VERSION ""

NS_ :

BS_:

BU_: BMS_Controller NF_Controller NF_Controllers

BO_ 2499762532 BATT_Diagnostic_Pack_A: 8 BMS_Controller
 SG_ BATT_01_vBrickOverSev m0 : 2|2@1+ (1,0) [0|3] ""  NF_Controller
 SG_ BATT_01_vBrickOverMod m0 : 0|2@1+ (1,0) [0|3] ""  NF_Controller
 SG_ BATT_01_vBrickOverWar m0 : 14|2@1+ (1,0) [0|3] ""  NF_Controller
 SG_ BATT_01_HostQuiet m0 : 12|2@1+ (1,0) [0|3] ""  NF_Controller
 SG_ BATT_01_vBrickUnderMod m0 : 10|2@1+ (1,0) [0|3] ""  NF_Controller
 SG_ BATT_01_vBrickUnderWar m0 : 8|2@1+ (1,0) [0|3] ""  NF_Controller
 SG_ BATT_01_TempModuleOverSev m0 : 22|2@1+ (1,0) [0|3] ""  NF_Controller
 SG_ BATT_01_TempModuleOverMod m0 : 20|2@1+ (1,0) [0|3] ""  NF_Controller
 SG_ BATT_01_TempModuleOverWar m0 : 18|2@1+ (1,0) [0|3] ""  NF_Controller
 SG_ BATT_01_TempModuleUnderSev m0 : 16|2@1+ (1,0) [0|3] ""  NF_Controller
 SG_ BATT_01_TempModuleUnderMod m0 : 30|2@1+ (1,0) [0|3] ""  NF_Controller
 SG_ BATT_01_TempModuleUnderWar m0 : 28|2@1+ (1,0) [0|3] ""  NF_Controller
 SG_ BATT_01_iOvercharge m0 : 26|2@1+ (1,0) [0|3] ""  NF_Controller
 SG_ BATT_01_iOverdischarge m0 : 24|2@1+ (1,0) [0|3] ""  NF_Controller
 SG_ BATT_01_iOverHardware m0 : 38|2@1+ (1,0) [0|3] ""  NF_Controller
 SG_ BATT_01_PosDcContStuckOpen m0 : 36|2@1+ (1,0) [0|3] ""  NF_Controller
 SG_ BATT_01_PosDcContWelded m0 : 34|2@1+ (1,0) [0|3] ""  NF_Controller
 SG_ BATT_01_NegDcContStuckOpen m0 : 32|2@1+ (1,0) [0|3] ""  NF_Controller
 SG_ BATT_01_NegDcContWelded m0 : 46|2@1+ (1,0) [0|3] ""  NF_Controller
 SG_ BATT_01_PrechgTooFast m0 : 44|2@1+ (1,0) [0|3] ""  NF_Controller
 SG_ BATT_01_PrechgContWelded m0 : 42|2@1+ (1,0) [0|3] ""  NF_Controller
 SG_ BATT_01_PrechgTimeout m0 : 40|2@1+ (1,0) [0|3] ""  NF_Controller
 SG_ BATT_01_PrechgContStuckOpen m0 : 54|2@1+ (1,0) [0|3] ""  NF_Controller
 SG_ BATT_01_ModuleImbalance m0 : 52|2@1+ (1,0) [0|3] ""  NF_Controller
 SG_ BATT_01_ModuleMIA m0 : 50|2@1+ (1,0) [0|3] ""  NF_Controller
 SG_ BATT_01_SensePackVoltError m0 : 48|2@1+ (1,0) [0|3] ""  NF_Controller
 SG_ BATT_01_SenseLoadVoltError m0 : 62|2@1+ (1,0) [0|3] ""  NF_Controller
 SG_ BATT_01_SenseShuntError m0 : 60|2@1+ (1,0) [0|3] ""  NF_Controller
 SG_ BATT_01_SenseFcVoltErrorr m0 : 58|2@1+ (1,0) [0|3] ""  NF_Controller
 SG_ BATT_01_SenseBrickOpen m0 : 56|2@1+ (1,0) [0|3] ""  NF_Controller
 SG_ BATT_02_vBrickOverSev m1 : 2|2@1+ (1,0) [0|3] ""  NF_Controller
 SG_ BATT_02_vBrickOverMod m1 : 0|2@1+ (1,0) [0|3] ""  NF_Controller
 SG_ BATT_02_vBrickOverWar m1 : 14|2@1+ (1,0) [0|3] ""  NF_Controller
 SG_ BATT_02_HostQuiet m1 : 12|2@1+ (1,0) [0|3] ""  NF_Controller
 SG_ BATT_02_vBrickUnderMod m1 : 10|2@1+ (1,0) [0|3] ""  NF_Controller
 SG_ BATT_02_vBrickUnderWar m1 : 8|2@1+ (1,0) [0|3] ""  NF_Controller
 SG_ BATT_02_TempModuleOverSev m1 : 22|2@1+ (1,0) [0|3] ""  NF_Controller
 SG_ BATT_02_TempModuleOverMod m1 : 20|2@1+ (1,0) [0|3] ""  NF_Controller
 SG_ BATT_02_TempModuleOverWar m1 : 18|2@1+ (1,0) [0|3] ""  NF_Controller
 SG_ BATT_02_TempModuleUnderSev m1 : 16|2@1+ (1,0) [0|3] ""  NF_Controller
 SG_ BATT_02_TempModuleUnderMod m1 : 30|2@1+ (1,0) [0|3] ""  NF_Controller
 SG_ BATT_02_TempModuleUnderWar m1 : 28|2@1+ (1,0) [0|3] ""  NF_Controller
 SG_ BATT_02_iOvercharge m1 : 26|2@1+ (1,0) [0|3] ""  NF_Controller
 SG_ BATT_02_iOverdischarge m1 : 24|2@1+ (1,0) [0|3] ""  NF_Controller
 SG_ BATT_02_iOverHardware m1 : 38|2@1+ (1,0) [0|3] ""  NF_Controller
 SG_ BATT_02_PosDcContStuckOpen m1 : 36|2@1+ (1,0) [0|3] ""  NF_Controller
 SG_ BATT_02_PosDcContWelded m1 : 34|2@1+ (1,0) [0|3] ""  NF_Controller
 SG_ BATT_02_NegDcContStuckOpen m1 : 32|2@1+ (1,0) [0|3] ""  NF_Controller
 SG_ BATT_02_NegDcContWelded m1 : 46|2@1+ (1,0) [0|3] ""  NF_Controller
 SG_ BATT_02_PrechgTooFast m1 : 44|2@1+ (1,0) [0|3] ""  NF_Controller
 SG_ BATT_02_PrechgContWelded m1 : 42|2@1+ (1,0) [0|3] ""  NF_Controller
 SG_ BATT_02_PrechgTimeout m1 : 40|2@1+ (1,0) [0|3] ""  NF_Controller
 SG_ BATT_02_PrechgContStuckOpen m1 : 54|2@1+ (1,0) [0|3] ""  NF_Controller
 SG_ BATT_02_ModuleImbalance m1 : 52|2@1+ (1,0) [0|3] ""  NF_Controller
 SG_ BATT_02_ModuleMIA m1 : 50|2@1+ (1,0) [0|3] ""  NF_Controller
 SG_ BATT_02_SensePackVoltError m1 : 48|2@1+ (1,0) [0|3] ""  NF_Controller
 SG_ BATT_02_SenseLoadVoltError m1 : 62|2@1+ (1,0) [0|3] ""  NF_Controller
 SG_ BATT_02_SenseShuntError m1 : 60|2@1+ (1,0) [0|3] ""  NF_Controller
 SG_ BATT_02_SenseFcVoltErrorr m1 : 58|2@1+ (1,0) [0|3] ""  NF_Controller
 SG_ BATT_02_SenseBrickOpen m1 : 56|2@1+ (1,0) [0|3] ""  NF_Controller
 SG_ BATT_03_vBrickOverSev m2 : 2|2@1+ (1,0) [0|3] ""  NF_Controller
 SG_ BATT_03_vBrickOverMod m2 : 0|2@1+ (1,0) [0|3] ""  NF_Controller
 SG_ BATT_03_vBrickOverWar m2 : 14|2@1+ (1,0) [0|3] ""  NF_Controller
 SG_ BATT_03_HostQuiet m2 : 12|2@1+ (1,0) [0|3] ""  NF_Controller
 SG_ BATT_03_vBrickUnderMod m2 : 10|2@1+ (1,0) [0|3] ""  NF_Controller
 SG_ BATT_03_vBrickUnderWar m2 : 8|2@1+ (1,0) [0|3] ""  NF_Controller
 SG_ BATT_03_TempModuleOverSev m2 : 22|2@1+ (1,0) [0|3] ""  NF_Controller
 SG_ BATT_03_TempModuleOverMod m2 : 20|2@1+ (1,0) [0|3] ""  NF_Controller
 SG_ BATT_03_TempModuleOverWar m2 : 18|2@1+ (1,0) [0|3] ""  NF_Controller
 SG_ BATT_03_TempModuleUnderSev m2 : 16|2@1+ (1,0) [0|3] ""  NF_Controller
 SG_ BATT_03_TempModuleUnderMod m2 : 30|2@1+ (1,0) [0|3] ""  NF_Controller
 SG_ BATT_03_TempModuleUnderWar m2 : 28|2@1+ (1,0) [0|3] ""  NF_Controller
 SG_ BATT_03_iOvercharge m2 : 26|2@1+ (1,0) [0|3] ""  NF_Controller
 SG_ BATT_03_iOverdischarge m2 : 24|2@1+ (1,0) [0|3] ""  NF_Controller
 SG_ BATT_03_iOverHardware m2 : 38|2@1+ (1,0) [0|3] ""  NF_Controller
 SG_ BATT_03_PosDcContStuckOpen m2 : 36|2@1+ (1,0) [0|3] ""  NF_Controller
 SG_ BATT_03_PosDcContWelded m2 : 34|2@1+ (1,0) [0|3] ""  NF_Controller
 SG_ BATT_03_NegDcContStuckOpen m2 : 32|2@1+ (1,0) [0|3] ""  NF_Controller
 SG_ BATT_03_NegDcContWelded m2 : 46|2@1+ (1,0) [0|3] ""  NF_Controller
 SG_ BATT_03_PrechgTooFast m2 : 44|2@1+ (1,0) [0|3] ""  NF_Controller
 SG_ BATT_03_PrechgContWelded m2 : 42|2@1+ (1,0) [0|3] ""  NF_Controller
 SG_ BATT_03_PrechgTimeout m2 : 40|2@1+ (1,0) [0|3] ""  NF_Controller
 SG_ BATT_03_PrechgContStuckOpen m2 : 54|2@1+ (1,0) [0|3] ""  NF_Controller
 SG_ BATT_03_ModuleImbalance m2 : 52|2@1+ (1,0) [0|3] ""  NF_Controller
 SG_ BATT_03_ModuleMIA m2 : 50|2@1+ (1,0) [0|3] ""  NF_Controller
 SG_ BATT_03_SensePackVoltError m2 : 48|2@1+ (1,0) [0|3] ""  NF_Controller
 SG_ BATT_03_SenseLoadVoltError m2 : 62|2@1+ (1,0) [0|3] ""  NF_Controller
 SG_ BATT_03_SenseShuntError m2 : 60|2@1+ (1,0) [0|3] ""  NF_Controller
 SG_ BATT_03_SenseFcVoltErrorr m2 : 58|2@1+ (1,0) [0|3] ""  NF_Controller
 SG_ BATT_03_SenseBrickOpen m2 : 56|2@1+ (1,0) [0|3] ""  NF_Controller
 SG_ BATT_04_vBrickOverSev m3 : 2|2@1+ (1,0) [0|3] ""  NF_Controller
 SG_ BATT_04_vBrickOverMod m3 : 0|2@1+ (1,0) [0|3] ""  NF_Controller
 SG_ BATT_04_vBrickOverWar m3 : 14|2@1+ (1,0) [0|3] ""  NF_Controller
 SG_ BATT_04_HostQuiet m3 : 12|2@1+ (1,0) [0|3] ""  NF_Controller
 SG_ BATT_04_vBrickUnderMod m3 : 10|2@1+ (1,0) [0|3] ""  NF_Controller
 SG_ BATT_04_vBrickUnderWar m3 : 8|2@1+ (1,0) [0|3] ""  NF_Controller
 SG_ BATT_04_TempModuleOverSev m3 : 22|2@1+ (1,0) [0|3] ""  NF_Controller
 SG_ BATT_04_TempModuleOverMod m3 : 20|2@1+ (1,0) [0|3] ""  NF_Controller
 SG_ BATT_04_TempModuleOverWar m3 : 18|2@1+ (1,0) [0|3] ""  NF_Controller
 SG_ BATT_04_TempModuleUnderSev m3 : 16|2@1+ (1,0) [0|3] ""  NF_Controller
 SG_ BATT_04_TempModuleUnderMod m3 : 30|2@1+ (1,0) [0|3] ""  NF_Controller
 SG_ BATT_04_TempModuleUnderWar m3 : 28|2@1+ (1,0) [0|3] ""  NF_Controller
 SG_ BATT_04_iOvercharge m3 : 26|2@1+ (1,0) [0|3] ""  NF_Controller
 SG_ BATT_04_iOverdischarge m3 : 24|2@1+ (1,0) [0|3] ""  NF_Controller
 SG_ BATT_04_iOverHardware m3 : 38|2@1+ (1,0) [0|3] ""  NF_Controller
 SG_ BATT_04_PosDcContStuckOpen m3 : 36|2@1+ (1,0) [0|3] ""  NF_Controller
 SG_ BATT_04_PosDcContWelded m3 : 34|2@1+ (1,0) [0|3] ""  NF_Controller
 SG_ BATT_04_NegDcContStuckOpen m3 : 32|2@1+ (1,0) [0|3] ""  NF_Controller
 SG_ BATT_04_NegDcContWelded m3 : 46|2@1+ (1,0) [0|3] ""  NF_Controller
 SG_ BATT_04_PrechgTooFast m3 : 44|2@1+ (1,0) [0|3] ""  NF_Controller
 SG_ BATT_04_PrechgContWelded m3 : 42|2@1+ (1,0) [0|3] ""  NF_Controller
 SG_ BATT_04_PrechgTimeout m3 : 40|2@1+ (1,0) [0|3] ""  NF_Controller
 SG_ BATT_04_PrechgContStuckOpen m3 : 54|2@1+ (1,0) [0|3] ""  NF_Controller
 SG_ BATT_04_ModuleImbalance m3 : 52|2@1+ (1,0) [0|3] ""  NF_Controller
 SG_ BATT_04_ModuleMIA m3 : 50|2@1+ (1,0) [0|3] ""  NF_Controller
 SG_ BATT_04_SensePackVoltError m3 : 48|2@1+ (1,0) [0|3] ""  NF_Controller
 SG_ BATT_04_SenseLoadVoltError m3 : 62|2@1+ (1,0) [0|3] ""  NF_Controller
 SG_ BATT_04_SenseShuntError m3 : 60|2@1+ (1,0) [0|3] ""  NF_Controller
 SG_ BATT_04_SenseFcVoltErrorr m3 : 58|2@1+ (1,0) [0|3] ""  NF_Controller
 SG_ BATT_04_SenseBrickOpen m3 : 56|2@1+ (1,0) [0|3] ""  NF_Controller
 SG_ BATT_05_vBrickOverSev m4 : 2|2@1+ (1,0) [0|3] ""  NF_Controller
 SG_ BATT_05_vBrickOverMod m4 : 0|2@1+ (1,0) [0|3] ""  NF_Controller
 SG_ BATT_05_vBrickOverWar m4 : 14|2@1+ (1,0) [0|3] ""  NF_Controller
 SG_ BATT_05_HostQuiet m4 : 12|2@1+ (1,0) [0|3] ""  NF_Controller
 SG_ BATT_05_vBrickUnderMod m4 : 10|2@1+ (1,0) [0|3] ""  NF_Controller
 SG_ BATT_05_vBrickUnderWar m4 : 8|2@1+ (1,0) [0|3] ""  NF_Controller
 SG_ BATT_05_TempModuleOverSev m4 : 22|2@1+ (1,0) [0|3] ""  NF_Controller
 SG_ BATT_05_TempModuleOverMod m4 : 20|2@1+ (1,0) [0|3] ""  NF_Controller
 SG_ BATT_05_TempModuleOverWar m4 : 18|2@1+ (1,0) [0|3] ""  NF_Controller
 SG_ BATT_05_TempModuleUnderSev m4 : 16|2@1+ (1,0) [0|3] ""  NF_Controller
 SG_ BATT_05_TempModuleUnderMod m4 : 30|2@1+ (1,0) [0|3] ""  NF_Controller
 SG_ BATT_05_TempModuleUnderWar m4 : 28|2@1+ (1,0) [0|3] ""  NF_Controller
 SG_ BATT_05_iOvercharge m4 : 26|2@1+ (1,0) [0|3] ""  NF_Controller
 SG_ BATT_05_iOverdischarge m4 : 24|2@1+ (1,0) [0|3] ""  NF_Controller
 SG_ BATT_05_iOverHardware m4 : 38|2@1+ (1,0) [0|3] ""  NF_Controller
 SG_ BATT_05_PosDcContStuckOpen m4 : 36|2@1+ (1,0) [0|3] ""  NF_Controller
 SG_ BATT_05_PosDcContWelded m4 : 34|2@1+ (1,0) [0|3] ""  NF_Controller
 SG_ BATT_05_NegDcContStuckOpen m4 : 32|2@1+ (1,0) [0|3] ""  NF_Controller
 SG_ BATT_05_NegDcContWelded m4 : 46|2@1+ (1,0) [0|3] ""  NF_Controller
 SG_ BATT_05_PrechgTooFast m4 : 44|2@1+ (1,0) [0|3] ""  NF_Controller
 SG_ BATT_05_PrechgContWelded m4 : 42|2@1+ (1,0) [0|3] ""  NF_Controller
 SG_ BATT_05_PrechgTimeout m4 : 40|2@1+ (1,0) [0|3] ""  NF_Controller
 SG_ BATT_05_PrechgContStuckOpen m4 : 54|2@1+ (1,0) [0|3] ""  NF_Controller
 SG_ BATT_05_ModuleImbalance m4 : 52|2@1+ (1,0) [0|3] ""  NF_Controller
 SG_ BATT_05_ModuleMIA m4 : 50|2@1+ (1,0) [0|3] ""  NF_Controller
 SG_ BATT_05_SensePackVoltError m4 : 48|2@1+ (1,0) [0|3] ""  NF_Controller
 SG_ BATT_05_SenseLoadVoltError m4 : 62|2@1+ (1,0) [0|3] ""  NF_Controller
 SG_ BATT_05_SenseShuntError m4 : 60|2@1+ (1,0) [0|3] ""  NF_Controller
 SG_ BATT_05_SenseFcVoltErrorr m4 : 58|2@1+ (1,0) [0|3] ""  NF_Controller
 SG_ BATT_05_SenseBrickOpen m4 : 56|2@1+ (1,0) [0|3] ""  NF_Controller
 SG_ BATT_06_vBrickOverSev m5 : 2|2@1+ (1,0) [0|3] ""  NF_Controller
 SG_ BATT_06_vBrickOverMod m5 : 0|2@1+ (1,0) [0|3] ""  NF_Controller
 SG_ BATT_06_vBrickOverWar m5 : 14|2@1+ (1,0) [0|3] ""  NF_Controller
 SG_ BATT_06_HostQuiet m5 : 12|2@1+ (1,0) [0|3] ""  NF_Controller
 SG_ BATT_06_vBrickUnderMod m5 : 10|2@1+ (1,0) [0|3] ""  NF_Controller
 SG_ BATT_06_vBrickUnderWar m5 : 8|2@1+ (1,0) [0|3] ""  NF_Controller
 SG_ BATT_06_TempModuleOverSev m5 : 22|2@1+ (1,0) [0|3] ""  NF_Controller
 SG_ BATT_06_TempModuleOverMod m5 : 20|2@1+ (1,0) [0|3] ""  NF_Controller
 SG_ BATT_06_TempModuleOverWar m5 : 18|2@1+ (1,0) [0|3] ""  NF_Controller
 SG_ BATT_06_TempModuleUnderSev m5 : 16|2@1+ (1,0) [0|3] ""  NF_Controller
 SG_ BATT_06_TempModuleUnderMod m5 : 30|2@1+ (1,0) [0|3] ""  NF_Controller
 SG_ BATT_06_TempModuleUnderWar m5 : 28|2@1+ (1,0) [0|3] ""  NF_Controller
 SG_ BATT_06_iOvercharge m5 : 26|2@1+ (1,0) [0|3] ""  NF_Controller
 SG_ BATT_06_iOverdischarge m5 : 24|2@1+ (1,0) [0|3] ""  NF_Controller
 SG_ BATT_06_iOverHardware m5 : 38|2@1+ (1,0) [0|3] ""  NF_Controller
 SG_ BATT_06_PosDcContStuckOpen m5 : 36|2@1+ (1,0) [0|3] ""  NF_Controller
 SG_ BATT_06_PosDcContWelded m5 : 34|2@1+ (1,0) [0|3] ""  NF_Controller
 SG_ BATT_06_NegDcContStuckOpen m5 : 32|2@1+ (1,0) [0|3] ""  NF_Controller
 SG_ BATT_06_NegDcContWelded m5 : 46|2@1+ (1,0) [0|3] ""  NF_Controller
 SG_ BATT_06_PrechgTooFast m5 : 44|2@1+ (1,0) [0|3] ""  NF_Controller
 SG_ BATT_06_PrechgContWelded m5 : 42|2@1+ (1,0) [0|3] ""  NF_Controller
 SG_ BATT_06_PrechgTimeout m5 : 40|2@1+ (1,0) [0|3] ""  NF_Controller
 SG_ BATT_06_PrechgContStuckOpen m5 : 54|2@1+ (1,0) [0|3] ""  NF_Controller
 SG_ BATT_06_ModuleImbalance m5 : 52|2@1+ (1,0) [0|3] ""  NF_Controller
 SG_ BATT_06_ModuleMIA m5 : 50|2@1+ (1,0) [0|3] ""  NF_Controller
 SG_ BATT_06_SensePackVoltError m5 : 48|2@1+ (1,0) [0|3] ""  NF_Controller
 SG_ BATT_06_SenseLoadVoltError m5 : 62|2@1+ (1,0) [0|3] ""  NF_Controller
 SG_ BATT_06_SenseShuntError m5 : 60|2@1+ (1,0) [0|3] ""  NF_Controller
 SG_ BATT_06_SenseFcVoltErrorr m5 : 58|2@1+ (1,0) [0|3] ""  NF_Controller
 SG_ BATT_06_SenseBrickOpen m5 : 56|2@1+ (1,0) [0|3] ""  NF_Controller
 SG_ BATT_07_vBrickOverSev m6 : 2|2@1+ (1,0) [0|3] ""  NF_Controller
 SG_ BATT_07_vBrickOverMod m6 : 0|2@1+ (1,0) [0|3] ""  NF_Controller
 SG_ BATT_07_vBrickOverWar m6 : 14|2@1+ (1,0) [0|3] ""  NF_Controller
 SG_ BATT_07_HostQuiet m6 : 12|2@1+ (1,0) [0|3] ""  NF_Controller
 SG_ BATT_07_vBrickUnderMod m6 : 10|2@1+ (1,0) [0|3] ""  NF_Controller
 SG_ BATT_07_vBrickUnderWar m6 : 8|2@1+ (1,0) [0|3] ""  NF_Controller
 SG_ BATT_07_TempModuleOverSev m6 : 22|2@1+ (1,0) [0|3] ""  NF_Controller
 SG_ BATT_07_TempModuleOverMod m6 : 20|2@1+ (1,0) [0|3] ""  NF_Controller
 SG_ BATT_07_TempModuleOverWar m6 : 18|2@1+ (1,0) [0|3] ""  NF_Controller
 SG_ BATT_07_TempModuleUnderSev m6 : 16|2@1+ (1,0) [0|3] ""  NF_Controller
 SG_ BATT_07_TempModuleUnderMod m6 : 30|2@1+ (1,0) [0|3] ""  NF_Controller
 SG_ BATT_07_TempModuleUnderWar m6 : 28|2@1+ (1,0) [0|3] ""  NF_Controller
 SG_ BATT_07_iOvercharge m6 : 26|2@1+ (1,0) [0|3] ""  NF_Controller
 SG_ BATT_07_iOverdischarge m6 : 24|2@1+ (1,0) [0|3] ""  NF_Controller
 SG_ BATT_07_iOverHardware m6 : 38|2@1+ (1,0) [0|3] ""  NF_Controller
 SG_ BATT_07_PosDcContStuckOpen m6 : 36|2@1+ (1,0) [0|3] ""  NF_Controller
 SG_ BATT_07_PosDcContWelded m6 : 34|2@1+ (1,0) [0|3] ""  NF_Controller
 SG_ BATT_07_NegDcContStuckOpen m6 : 32|2@1+ (1,0) [0|3] ""  NF_Controller
 SG_ BATT_07_NegDcContWelded m6 : 46|2@1+ (1,0) [0|3] ""  NF_Controller
 SG_ BATT_07_PrechgTooFast m6 : 44|2@1+ (1,0) [0|3] ""  NF_Controller
 SG_ BATT_07_PrechgContWelded m6 : 42|2@1+ (1,0) [0|3] ""  NF_Controller
 SG_ BATT_07_PrechgTimeout m6 : 40|2@1+ (1,0) [0|3] ""  NF_Controller
 SG_ BATT_07_PrechgContStuckOpen m6 : 54|2@1+ (1,0) [0|3] ""  NF_Controller
 SG_ BATT_07_ModuleImbalance m6 : 52|2@1+ (1,0) [0|3] ""  NF_Controller
 SG_ BATT_07_ModuleMIA m6 : 50|2@1+ (1,0) [0|3] ""  NF_Controller
 SG_ BATT_07_SensePackVoltError m6 : 48|2@1+ (1,0) [0|3] ""  NF_Controller
 SG_ BATT_07_SenseLoadVoltError m6 : 62|2@1+ (1,0) [0|3] ""  NF_Controller
 SG_ BATT_07_SenseShuntError m6 : 60|2@1+ (1,0) [0|3] ""  NF_Controller
 SG_ BATT_07_SenseFcVoltErrorr m6 : 58|2@1+ (1,0) [0|3] ""  NF_Controller
 SG_ BATT_07_SenseBrickOpen m6 : 56|2@1+ (1,0) [0|3] ""  NF_Controller
 SG_ BATT_08_vBrickOverSev m7 : 2|2@1+ (1,0) [0|3] ""  NF_Controller
 SG_ BATT_08_vBrickOverMod m7 : 0|2@1+ (1,0) [0|3] ""  NF_Controller
 SG_ BATT_08_vBrickOverWar m7 : 14|2@1+ (1,0) [0|3] ""  NF_Controller
 SG_ BATT_08_HostQuiet m7 : 12|2@1+ (1,0) [0|3] ""  NF_Controller
 SG_ BATT_08_vBrickUnderMod m7 : 10|2@1+ (1,0) [0|3] ""  NF_Controller
 SG_ BATT_08_vBrickUnderWar m7 : 8|2@1+ (1,0) [0|3] ""  NF_Controller
 SG_ BATT_08_TempModuleOverSev m7 : 22|2@1+ (1,0) [0|3] ""  NF_Controller
 SG_ BATT_08_TempModuleOverMod m7 : 20|2@1+ (1,0) [0|3] ""  NF_Controller
 SG_ BATT_08_TempModuleOverWar m7 : 18|2@1+ (1,0) [0|3] ""  NF_Controller
 SG_ BATT_08_TempModuleUnderSev m7 : 16|2@1+ (1,0) [0|3] ""  NF_Controller
 SG_ BATT_08_TempModuleUnderMod m7 : 30|2@1+ (1,0) [0|3] ""  NF_Controller
 SG_ BATT_08_TempModuleUnderWar m7 : 28|2@1+ (1,0) [0|3] ""  NF_Controller
 SG_ BATT_08_iOvercharge m7 : 26|2@1+ (1,0) [0|3] ""  NF_Controller
 SG_ BATT_08_iOverdischarge m7 : 24|2@1+ (1,0) [0|3] ""  NF_Controller
 SG_ BATT_08_iOverHardware m7 : 38|2@1+ (1,0) [0|3] ""  NF_Controller
 SG_ BATT_08_PosDcContStuckOpen m7 : 36|2@1+ (1,0) [0|3] ""  NF_Controller
 SG_ BATT_08_PosDcContWelded m7 : 34|2@1+ (1,0) [0|3] ""  NF_Controller
 SG_ BATT_08_NegDcContStuckOpen m7 : 32|2@1+ (1,0) [0|3] ""  NF_Controller
 SG_ BATT_08_NegDcContWelded m7 : 46|2@1+ (1,0) [0|3] ""  NF_Controller
 SG_ BATT_08_PrechgTooFast m7 : 44|2@1+ (1,0) [0|3] ""  NF_Controller
 SG_ BATT_08_PrechgContWelded m7 : 42|2@1+ (1,0) [0|3] ""  NF_Controller
 SG_ BATT_08_PrechgTimeout m7 : 40|2@1+ (1,0) [0|3] ""  NF_Controller
 SG_ BATT_08_PrechgContStuckOpen m7 : 54|2@1+ (1,0) [0|3] ""  NF_Controller
 SG_ BATT_08_ModuleImbalance m7 : 52|2@1+ (1,0) [0|3] ""  NF_Controller
 SG_ BATT_08_ModuleMIA m7 : 50|2@1+ (1,0) [0|3] ""  NF_Controller
 SG_ BATT_08_SensePackVoltError m7 : 48|2@1+ (1,0) [0|3] ""  NF_Controller
 SG_ BATT_08_SenseLoadVoltError m7 : 62|2@1+ (1,0) [0|3] ""  NF_Controller
 SG_ BATT_08_SenseShuntError m7 : 60|2@1+ (1,0) [0|3] ""  NF_Controller
 SG_ BATT_08_SenseFcVoltErrorr m7 : 58|2@1+ (1,0) [0|3] ""  NF_Controller
 SG_ BATT_08_SenseBrickOpen m7 : 56|2@1+ (1,0) [0|3] ""  NF_Controller
 SG_ BATT_09_vBrickOverSev m8 : 2|2@1+ (1,0) [0|3] ""  NF_Controller
 SG_ BATT_09_vBrickOverMod m8 : 0|2@1+ (1,0) [0|3] ""  NF_Controller
 SG_ BATT_09_vBrickOverWar m8 : 14|2@1+ (1,0) [0|3] ""  NF_Controller
 SG_ BATT_09_HostQuiet m8 : 12|2@1+ (1,0) [0|3] ""  NF_Controller
 SG_ BATT_09_vBrickUnderMod m8 : 10|2@1+ (1,0) [0|3] ""  NF_Controller
 SG_ BATT_09_vBrickUnderWar m8 : 8|2@1+ (1,0) [0|3] ""  NF_Controller
 SG_ BATT_09_TempModuleOverSev m8 : 22|2@1+ (1,0) [0|3] ""  NF_Controller
 SG_ BATT_09_TempModuleOverMod m8 : 20|2@1+ (1,0) [0|3] ""  NF_Controller
 SG_ BATT_09_TempModuleOverWar m8 : 18|2@1+ (1,0) [0|3] ""  NF_Controller
 SG_ BATT_09_TempModuleUnderSev m8 : 16|2@1+ (1,0) [0|3] ""  NF_Controller
 SG_ BATT_09_TempModuleUnderMod m8 : 30|2@1+ (1,0) [0|3] ""  NF_Controller
 SG_ BATT_09_TempModuleUnderWar m8 : 28|2@1+ (1,0) [0|3] ""  NF_Controller
 SG_ BATT_09_iOvercharge m8 : 26|2@1+ (1,0) [0|3] ""  NF_Controller
 SG_ BATT_09_iOverdischarge m8 : 24|2@1+ (1,0) [0|3] ""  NF_Controller
 SG_ BATT_09_iOverHardware m8 : 38|2@1+ (1,0) [0|3] ""  NF_Controller
 SG_ BATT_09_PosDcContStuckOpen m8 : 36|2@1+ (1,0) [0|3] ""  NF_Controller
 SG_ BATT_09_PosDcContWelded m8 : 34|2@1+ (1,0) [0|3] ""  NF_Controller
 SG_ BATT_09_NegDcContStuckOpen m8 : 32|2@1+ (1,0) [0|3] ""  NF_Controller
 SG_ BATT_09_NegDcContWelded m8 : 46|2@1+ (1,0) [0|3] ""  NF_Controller
 SG_ BATT_09_PrechgTooFast m8 : 44|2@1+ (1,0) [0|3] ""  NF_Controller
 SG_ BATT_09_PrechgContWelded m8 : 42|2@1+ (1,0) [0|3] ""  NF_Controller
 SG_ BATT_09_PrechgTimeout m8 : 40|2@1+ (1,0) [0|3] ""  NF_Controller
 SG_ BATT_09_PrechgContStuckOpen m8 : 54|2@1+ (1,0) [0|3] ""  NF_Controller
 SG_ BATT_09_ModuleImbalance m8 : 52|2@1+ (1,0) [0|3] ""  NF_Controller
 SG_ BATT_09_ModuleMIA m8 : 50|2@1+ (1,0) [0|3] ""  NF_Controller
 SG_ BATT_09_SensePackVoltError m8 : 48|2@1+ (1,0) [0|3] ""  NF_Controller
 SG_ BATT_09_SenseLoadVoltError m8 : 62|2@1+ (1,0) [0|3] ""  NF_Controller
 SG_ BATT_09_SenseShuntError m8 : 60|2@1+ (1,0) [0|3] ""  NF_Controller
 SG_ BATT_09_SenseFcVoltErrorr m8 : 58|2@1+ (1,0) [0|3] ""  NF_Controller
 SG_ BATT_09_SenseBrickOpen m8 : 56|2@1+ (1,0) [0|3] ""  NF_Controller
 SG_ BATT_10_vBrickOverSev m9 : 2|2@1+ (1,0) [0|3] ""  NF_Controller
 SG_ BATT_10_vBrickOverMod m9 : 0|2@1+ (1,0) [0|3] ""  NF_Controller
 SG_ BATT_10_vBrickOverWar m9 : 14|2@1+ (1,0) [0|3] ""  NF_Controller
 SG_ BATT_10_HostQuiet m9 : 12|2@1+ (1,0) [0|3] ""  NF_Controller
 SG_ BATT_10_vBrickUnderMod m9 : 10|2@1+ (1,0) [0|3] ""  NF_Controller
 SG_ BATT_10_vBrickUnderWar m9 : 8|2@1+ (1,0) [0|3] ""  NF_Controller
 SG_ BATT_10_TempModuleOverSev m9 : 22|2@1+ (1,0) [0|3] ""  NF_Controller
 SG_ BATT_10_TempModuleOverMod m9 : 20|2@1+ (1,0) [0|3] ""  NF_Controller
 SG_ BATT_10_TempModuleOverWar m9 : 18|2@1+ (1,0) [0|3] ""  NF_Controller
 SG_ BATT_10_TempModuleUnderSev m9 : 16|2@1+ (1,0) [0|3] ""  NF_Controller
 SG_ BATT_10_TempModuleUnderMod m9 : 30|2@1+ (1,0) [0|3] ""  NF_Controller
 SG_ BATT_10_TempModuleUnderWar m9 : 28|2@1+ (1,0) [0|3] ""  NF_Controller
 SG_ BATT_10_iOvercharge m9 : 26|2@1+ (1,0) [0|3] ""  NF_Controller
 SG_ BATT_10_iOverdischarge m9 : 24|2@1+ (1,0) [0|3] ""  NF_Controller
 SG_ BATT_10_iOverHardware m9 : 38|2@1+ (1,0) [0|3] ""  NF_Controller
 SG_ BATT_10_PosDcContStuckOpen m9 : 36|2@1+ (1,0) [0|3] ""  NF_Controller
 SG_ BATT_10_PosDcContWelded m9 : 34|2@1+ (1,0) [0|3] ""  NF_Controller
 SG_ BATT_10_NegDcContStuckOpen m9 : 32|2@1+ (1,0) [0|3] ""  NF_Controller
 SG_ BATT_10_NegDcContWelded m9 : 46|2@1+ (1,0) [0|3] ""  NF_Controller
 SG_ BATT_10_PrechgTooFast m9 : 44|2@1+ (1,0) [0|3] ""  NF_Controller
 SG_ BATT_10_PrechgContWelded m9 : 42|2@1+ (1,0) [0|3] ""  NF_Controller
 SG_ BATT_10_PrechgTimeout m9 : 40|2@1+ (1,0) [0|3] ""  NF_Controller
 SG_ BATT_10_PrechgContStuckOpen m9 : 54|2@1+ (1,0) [0|3] ""  NF_Controller
 SG_ BATT_10_ModuleImbalance m9 : 52|2@1+ (1,0) [0|3] ""  NF_Controller
 SG_ BATT_10_ModuleMIA m9 : 50|2@1+ (1,0) [0|3] ""  NF_Controller
 SG_ BATT_10_SensePackVoltError m9 : 48|2@1+ (1,0) [0|3] ""  NF_Controller
 SG_ BATT_10_SenseLoadVoltError m9 : 62|2@1+ (1,0) [0|3] ""  NF_Controller
 SG_ BATT_10_SenseShuntError m9 : 60|2@1+ (1,0) [0|3] ""  NF_Controller
 SG_ BATT_10_SenseFcVoltErrorr m9 : 58|2@1+ (1,0) [0|3] ""  NF_Controller
 SG_ BATT_10_SenseBrickOpen m9 : 56|2@1+ (1,0) [0|3] ""  NF_Controller
 SG_ BATT_11_vBrickOverSev m10 : 2|2@1+ (1,0) [0|3] ""  NF_Controller
 SG_ BATT_11_vBrickOverMod m10 : 0|2@1+ (1,0) [0|3] ""  NF_Controller
 SG_ BATT_11_vBrickOverWar m10 : 14|2@1+ (1,0) [0|3] ""  NF_Controller
 SG_ BATT_11_HostQuiet m10 : 12|2@1+ (1,0) [0|3] ""  NF_Controller
 SG_ BATT_11_vBrickUnderMod m10 : 10|2@1+ (1,0) [0|3] ""  NF_Controller
 SG_ BATT_11_vBrickUnderWar m10 : 8|2@1+ (1,0) [0|3] ""  NF_Controller
 SG_ BATT_11_TempModuleOverSev m10 : 22|2@1+ (1,0) [0|3] ""  NF_Controller
 SG_ BATT_11_TempModuleOverMod m10 : 20|2@1+ (1,0) [0|3] ""  NF_Controller
 SG_ BATT_11_TempModuleOverWar m10 : 18|2@1+ (1,0) [0|3] ""  NF_Controller
 SG_ BATT_11_TempModuleUnderSev m10 : 16|2@1+ (1,0) [0|3] ""  NF_Controller
 SG_ BATT_11_TempModuleUnderMod m10 : 30|2@1+ (1,0) [0|3] ""  NF_Controller
 SG_ BATT_11_TempModuleUnderWar m10 : 28|2@1+ (1,0) [0|3] ""  NF_Controller
 SG_ BATT_11_iOvercharge m10 : 26|2@1+ (1,0) [0|3] ""  NF_Controller
 SG_ BATT_11_iOverdischarge m10 : 24|2@1+ (1,0) [0|3] ""  NF_Controller
 SG_ BATT_11_iOverHardware m10 : 38|2@1+ (1,0) [0|3] ""  NF_Controller
 SG_ BATT_11_PosDcContStuckOpen m10 : 36|2@1+ (1,0) [0|3] ""  NF_Controller
 SG_ BATT_11_PosDcContWelded m10 : 34|2@1+ (1,0) [0|3] ""  NF_Controller
 SG_ BATT_11_NegDcContStuckOpen m10 : 32|2@1+ (1,0) [0|3] ""  NF_Controller
 SG_ BATT_11_NegDcContWelded m10 : 46|2@1+ (1,0) [0|3] ""  NF_Controller
 SG_ BATT_11_PrechgTooFast m10 : 44|2@1+ (1,0) [0|3] ""  NF_Controller
 SG_ BATT_11_PrechgContWelded m10 : 42|2@1+ (1,0) [0|3] ""  NF_Controller
 SG_ BATT_11_PrechgTimeout m10 : 40|2@1+ (1,0) [0|3] ""  NF_Controller
 SG_ BATT_11_PrechgContStuckOpen m10 : 54|2@1+ (1,0) [0|3] ""  NF_Controller
 SG_ BATT_11_ModuleImbalance m10 : 52|2@1+ (1,0) [0|3] ""  NF_Controller
 SG_ BATT_11_ModuleMIA m10 : 50|2@1+ (1,0) [0|3] ""  NF_Controller
 SG_ BATT_11_SensePackVoltError m10 : 48|2@1+ (1,0) [0|3] ""  NF_Controller
 SG_ BATT_11_SenseLoadVoltError m10 : 62|2@1+ (1,0) [0|3] ""  NF_Controller
 SG_ BATT_11_SenseShuntError m10 : 60|2@1+ (1,0) [0|3] ""  NF_Controller
 SG_ BATT_11_SenseFcVoltErrorr m10 : 58|2@1+ (1,0) [0|3] ""  NF_Controller
 SG_ BATT_11_SenseBrickOpen m10 : 56|2@1+ (1,0) [0|3] ""  NF_Controller
 SG_ BATT_12_vBrickOverSev m11 : 2|2@1+ (1,0) [0|3] ""  NF_Controller
 SG_ BATT_12_vBrickOverMod m11 : 0|2@1+ (1,0) [0|3] ""  NF_Controller
 SG_ BATT_12_vBrickOverWar m11 : 14|2@1+ (1,0) [0|3] ""  NF_Controller
 SG_ BATT_12_HostQuiet m11 : 12|2@1+ (1,0) [0|3] ""  NF_Controller
 SG_ BATT_12_vBrickUnderMod m11 : 10|2@1+ (1,0) [0|3] ""  NF_Controller
 SG_ BATT_12_vBrickUnderWar m11 : 8|2@1+ (1,0) [0|3] ""  NF_Controller
 SG_ BATT_12_TempModuleOverSev m11 : 22|2@1+ (1,0) [0|3] ""  NF_Controller
 SG_ BATT_12_TempModuleOverMod m11 : 20|2@1+ (1,0) [0|3] ""  NF_Controller
 SG_ BATT_12_TempModuleOverWar m11 : 18|2@1+ (1,0) [0|3] ""  NF_Controller
 SG_ BATT_12_TempModuleUnderSev m11 : 16|2@1+ (1,0) [0|3] ""  NF_Controller
 SG_ BATT_12_TempModuleUnderMod m11 : 30|2@1+ (1,0) [0|3] ""  NF_Controller
 SG_ BATT_12_TempModuleUnderWar m11 : 28|2@1+ (1,0) [0|3] ""  NF_Controller
 SG_ BATT_12_iOvercharge m11 : 26|2@1+ (1,0) [0|3] ""  NF_Controller
 SG_ BATT_12_iOverdischarge m11 : 24|2@1+ (1,0) [0|3] ""  NF_Controller
 SG_ BATT_12_iOverHardware m11 : 38|2@1+ (1,0) [0|3] ""  NF_Controller
 SG_ BATT_12_PosDcContStuckOpen m11 : 36|2@1+ (1,0) [0|3] ""  NF_Controller
 SG_ BATT_12_PosDcContWelded m11 : 34|2@1+ (1,0) [0|3] ""  NF_Controller
 SG_ BATT_12_NegDcContStuckOpen m11 : 32|2@1+ (1,0) [0|3] ""  NF_Controller
 SG_ BATT_12_NegDcContWelded m11 : 46|2@1+ (1,0) [0|3] ""  NF_Controller
 SG_ BATT_12_PrechgTooFast m11 : 44|2@1+ (1,0) [0|3] ""  NF_Controller
 SG_ BATT_12_PrechgContWelded m11 : 42|2@1+ (1,0) [0|3] ""  NF_Controller
 SG_ BATT_12_PrechgTimeout m11 : 40|2@1+ (1,0) [0|3] ""  NF_Controller
 SG_ BATT_12_PrechgContStuckOpen m11 : 54|2@1+ (1,0) [0|3] ""  NF_Controller
 SG_ BATT_12_ModuleImbalance m11 : 52|2@1+ (1,0) [0|3] ""  NF_Controller
 SG_ BATT_12_ModuleMIA m11 : 50|2@1+ (1,0) [0|3] ""  NF_Controller
 SG_ BATT_12_SensePackVoltError m11 : 48|2@1+ (1,0) [0|3] ""  NF_Controller
 SG_ BATT_12_SenseLoadVoltError m11 : 62|2@1+ (1,0) [0|3] ""  NF_Controller
 SG_ BATT_12_SenseShuntError m11 : 60|2@1+ (1,0) [0|3] ""  NF_Controller
 SG_ BATT_12_SenseFcVoltErrorr m11 : 58|2@1+ (1,0) [0|3] ""  NF_Controller
 SG_ BATT_12_SenseBrickOpen m11 : 56|2@1+ (1,0) [0|3] ""  NF_Controller
 SG_ BATT_13_vBrickOverSev m12 : 2|2@1+ (1,0) [0|3] ""  NF_Controller
 SG_ BATT_13_vBrickOverMod m12 : 0|2@1+ (1,0) [0|3] ""  NF_Controller
 SG_ BATT_13_vBrickOverWar m12 : 14|2@1+ (1,0) [0|3] ""  NF_Controller
 SG_ BATT_13_HostQuiet m12 : 12|2@1+ (1,0) [0|3] ""  NF_Controller
 SG_ BATT_13_vBrickUnderMod m12 : 10|2@1+ (1,0) [0|3] ""  NF_Controller
 SG_ BATT_13_vBrickUnderWar m12 : 8|2@1+ (1,0) [0|3] ""  NF_Controller
 SG_ BATT_13_TempModuleOverSev m12 : 22|2@1+ (1,0) [0|3] ""  NF_Controller
 SG_ BATT_13_TempModuleOverMod m12 : 20|2@1+ (1,0) [0|3] ""  NF_Controller
 SG_ BATT_13_TempModuleOverWar m12 : 18|2@1+ (1,0) [0|3] ""  NF_Controller
 SG_ BATT_13_TempModuleUnderSev m12 : 16|2@1+ (1,0) [0|3] ""  NF_Controller
 SG_ BATT_13_TempModuleUnderMod m12 : 30|2@1+ (1,0) [0|3] ""  NF_Controller
 SG_ BATT_13_TempModuleUnderWar m12 : 28|2@1+ (1,0) [0|3] ""  NF_Controller
 SG_ BATT_13_iOvercharge m12 : 26|2@1+ (1,0) [0|3] ""  NF_Controller
 SG_ BATT_13_iOverdischarge m12 : 24|2@1+ (1,0) [0|3] ""  NF_Controller
 SG_ BATT_13_iOverHardware m12 : 38|2@1+ (1,0) [0|3] ""  NF_Controller
 SG_ BATT_13_PosDcContStuckOpen m12 : 36|2@1+ (1,0) [0|3] ""  NF_Controller
 SG_ BATT_13_PosDcContWelded m12 : 34|2@1+ (1,0) [0|3] ""  NF_Controller
 SG_ BATT_13_NegDcContStuckOpen m12 : 32|2@1+ (1,0) [0|3] ""  NF_Controller
 SG_ BATT_13_NegDcContWelded m12 : 46|2@1+ (1,0) [0|3] ""  NF_Controller
 SG_ BATT_13_PrechgTooFast m12 : 44|2@1+ (1,0) [0|3] ""  NF_Controller
 SG_ BATT_13_PrechgContWelded m12 : 42|2@1+ (1,0) [0|3] ""  NF_Controller
 SG_ BATT_13_PrechgTimeout m12 : 40|2@1+ (1,0) [0|3] ""  NF_Controller
 SG_ BATT_13_PrechgContStuckOpen m12 : 54|2@1+ (1,0) [0|3] ""  NF_Controller
 SG_ BATT_13_ModuleImbalance m12 : 52|2@1+ (1,0) [0|3] ""  NF_Controller
 SG_ BATT_13_ModuleMIA m12 : 50|2@1+ (1,0) [0|3] ""  NF_Controller
 SG_ BATT_13_SensePackVoltError m12 : 48|2@1+ (1,0) [0|3] ""  NF_Controller
 SG_ BATT_13_SenseLoadVoltError m12 : 62|2@1+ (1,0) [0|3] ""  NF_Controller
 SG_ BATT_13_SenseShuntError m12 : 60|2@1+ (1,0) [0|3] ""  NF_Controller
 SG_ BATT_13_SenseFcVoltErrorr m12 : 58|2@1+ (1,0) [0|3] ""  NF_Controller
 SG_ BATT_13_SenseBrickOpen m12 : 56|2@1+ (1,0) [0|3] ""  NF_Controller
 SG_ BATT_14_vBrickOverSev m13 : 2|2@1+ (1,0) [0|3] ""  NF_Controller
 SG_ BATT_14_vBrickOverMod m13 : 0|2@1+ (1,0) [0|3] ""  NF_Controller
 SG_ BATT_14_vBrickOverWar m13 : 14|2@1+ (1,0) [0|3] ""  NF_Controller
 SG_ BATT_14_HostQuiet m13 : 12|2@1+ (1,0) [0|3] ""  NF_Controller
 SG_ BATT_14_vBrickUnderMod m13 : 10|2@1+ (1,0) [0|3] ""  NF_Controller
 SG_ BATT_14_vBrickUnderWar m13 : 8|2@1+ (1,0) [0|3] ""  NF_Controller
 SG_ BATT_14_TempModuleOverSev m13 : 22|2@1+ (1,0) [0|3] ""  NF_Controller
 SG_ BATT_14_TempModuleOverMod m13 : 20|2@1+ (1,0) [0|3] ""  NF_Controller
 SG_ BATT_14_TempModuleOverWar m13 : 18|2@1+ (1,0) [0|3] ""  NF_Controller
 SG_ BATT_14_TempModuleUnderSev m13 : 16|2@1+ (1,0) [0|3] ""  NF_Controller
 SG_ BATT_14_TempModuleUnderMod m13 : 30|2@1+ (1,0) [0|3] ""  NF_Controller
 SG_ BATT_14_TempModuleUnderWar m13 : 28|2@1+ (1,0) [0|3] ""  NF_Controller
 SG_ BATT_14_iOvercharge m13 : 26|2@1+ (1,0) [0|3] ""  NF_Controller
 SG_ BATT_14_iOverdischarge m13 : 24|2@1+ (1,0) [0|3] ""  NF_Controller
 SG_ BATT_14_iOverHardware m13 : 38|2@1+ (1,0) [0|3] ""  NF_Controller
 SG_ BATT_14_PosDcContStuckOpen m13 : 36|2@1+ (1,0) [0|3] ""  NF_Controller
 SG_ BATT_14_PosDcContWelded m13 : 34|2@1+ (1,0) [0|3] ""  NF_Controller
 SG_ BATT_14_NegDcContStuckOpen m13 : 32|2@1+ (1,0) [0|3] ""  NF_Controller
 SG_ BATT_14_NegDcContWelded m13 : 46|2@1+ (1,0) [0|3] ""  NF_Controller
 SG_ BATT_14_PrechgTooFast m13 : 44|2@1+ (1,0) [0|3] ""  NF_Controller
 SG_ BATT_14_PrechgContWelded m13 : 42|2@1+ (1,0) [0|3] ""  NF_Controller
 SG_ BATT_14_PrechgTimeout m13 : 40|2@1+ (1,0) [0|3] ""  NF_Controller
 SG_ BATT_14_PrechgContStuckOpen m13 : 54|2@1+ (1,0) [0|3] ""  NF_Controller
 SG_ BATT_14_ModuleImbalance m13 : 52|2@1+ (1,0) [0|3] ""  NF_Controller
 SG_ BATT_14_ModuleMIA m13 : 50|2@1+ (1,0) [0|3] ""  NF_Controller
 SG_ BATT_14_SensePackVoltError m13 : 48|2@1+ (1,0) [0|3] ""  NF_Controller
 SG_ BATT_14_SenseLoadVoltError m13 : 62|2@1+ (1,0) [0|3] ""  NF_Controller
 SG_ BATT_14_SenseShuntError m13 : 60|2@1+ (1,0) [0|3] ""  NF_Controller
 SG_ BATT_14_SenseFcVoltErrorr m13 : 58|2@1+ (1,0) [0|3] ""  NF_Controller
 SG_ BATT_14_SenseBrickOpen m13 : 56|2@1+ (1,0) [0|3] ""  NF_Controller
 SG_ BATT_15_vBrickOverSev m14 : 2|2@1+ (1,0) [0|3] ""  NF_Controller
 SG_ BATT_15_vBrickOverMod m14 : 0|2@1+ (1,0) [0|3] ""  NF_Controller
 SG_ BATT_15_vBrickOverWar m14 : 14|2@1+ (1,0) [0|3] ""  NF_Controller
 SG_ BATT_15_HostQuiet m14 : 12|2@1+ (1,0) [0|3] ""  NF_Controller
 SG_ BATT_15_vBrickUnderMod m14 : 10|2@1+ (1,0) [0|3] ""  NF_Controller
 SG_ BATT_15_vBrickUnderWar m14 : 8|2@1+ (1,0) [0|3] ""  NF_Controller
 SG_ BATT_15_TempModuleOverSev m14 : 22|2@1+ (1,0) [0|3] ""  NF_Controller
 SG_ BATT_15_TempModuleOverMod m14 : 20|2@1+ (1,0) [0|3] ""  NF_Controller
 SG_ BATT_15_TempModuleOverWar m14 : 18|2@1+ (1,0) [0|3] ""  NF_Controller
 SG_ BATT_15_TempModuleUnderSev m14 : 16|2@1+ (1,0) [0|3] ""  NF_Controller
 SG_ BATT_15_TempModuleUnderMod m14 : 30|2@1+ (1,0) [0|3] ""  NF_Controller
 SG_ BATT_15_TempModuleUnderWar m14 : 28|2@1+ (1,0) [0|3] ""  NF_Controller
 SG_ BATT_15_iOvercharge m14 : 26|2@1+ (1,0) [0|3] ""  NF_Controller
 SG_ BATT_15_iOverdischarge m14 : 24|2@1+ (1,0) [0|3] ""  NF_Controller
 SG_ BATT_15_iOverHardware m14 : 38|2@1+ (1,0) [0|3] ""  NF_Controller
 SG_ BATT_15_PosDcContStuckOpen m14 : 36|2@1+ (1,0) [0|3] ""  NF_Controller
 SG_ BATT_15_PosDcContWelded m14 : 34|2@1+ (1,0) [0|3] ""  NF_Controller
 SG_ BATT_15_NegDcContStuckOpen m14 : 32|2@1+ (1,0) [0|3] ""  NF_Controller
 SG_ BATT_15_NegDcContWelded m14 : 46|2@1+ (1,0) [0|3] ""  NF_Controller
 SG_ BATT_15_PrechgTooFast m14 : 44|2@1+ (1,0) [0|3] ""  NF_Controller
 SG_ BATT_15_PrechgContWelded m14 : 42|2@1+ (1,0) [0|3] ""  NF_Controller
 SG_ BATT_15_PrechgTimeout m14 : 40|2@1+ (1,0) [0|3] ""  NF_Controller
 SG_ BATT_15_PrechgContStuckOpen m14 : 54|2@1+ (1,0) [0|3] ""  NF_Controller
 SG_ BATT_15_ModuleImbalance m14 : 52|2@1+ (1,0) [0|3] ""  NF_Controller
 SG_ BATT_15_ModuleMIA m14 : 50|2@1+ (1,0) [0|3] ""  NF_Controller
 SG_ BATT_15_SensePackVoltError m14 : 48|2@1+ (1,0) [0|3] ""  NF_Controller
 SG_ BATT_15_SenseLoadVoltError m14 : 62|2@1+ (1,0) [0|3] ""  NF_Controller
 SG_ BATT_15_SenseShuntError m14 : 60|2@1+ (1,0) [0|3] ""  NF_Controller
 SG_ BATT_15_SenseFcVoltErrorr m14 : 58|2@1+ (1,0) [0|3] ""  NF_Controller
 SG_ BATT_15_SenseBrickOpen m14 : 56|2@1+ (1,0) [0|3] ""  NF_Controller
 SG_ multiplexor_batt_diag_A M : 4|4@1+ (1,0) [0|15] ""  NF_Controller

BO_ 2499758948 BATT_Diagnostic_System_A: 8 BMS_Controller
 SG_ BATT_vBrickOverSev : 2|2@1+ (1,0) [0|3] ""  NF_Controller
 SG_ BATT_vBrickOverMod : 0|2@1+ (1,0) [0|3] ""  NF_Controller
 SG_ BATT_vBrickOverWar : 14|2@1+ (1,0) [0|3] ""  NF_Controller
 SG_ BATT_HostQuiet : 12|2@1+ (1,0) [0|3] ""  NF_Controller
 SG_ BATT_vBrickUnderMod : 10|2@1+ (1,0) [0|3] ""  NF_Controller
 SG_ BATT_vBrickUnderWar : 8|2@1+ (1,0) [0|3] ""  NF_Controller
 SG_ BATT_TempModuleOverSev : 22|2@1+ (1,0) [0|3] ""  NF_Controller
 SG_ BATT_TempModuleOverMod : 20|2@1+ (1,0) [0|3] ""  NF_Controller
 SG_ BATT_TempModuleOverWar : 18|2@1+ (1,0) [0|3] ""  NF_Controller
 SG_ BATT_TempModuleUnderSev : 16|2@1+ (1,0) [0|3] ""  NF_Controller
 SG_ BATT_TempModuleUnderMod : 30|2@1+ (1,0) [0|3] ""  NF_Controller
 SG_ BATT_TempModuleUnderWar : 28|2@1+ (1,0) [0|3] ""  NF_Controller
 SG_ BATT_iOvercharge : 26|2@1+ (1,0) [0|3] ""  NF_Controller
 SG_ BATT_iOverdischarge : 24|2@1+ (1,0) [0|3] ""  NF_Controller
 SG_ BATT_iOverHardware : 38|2@1+ (1,0) [0|3] ""  NF_Controller
 SG_ BATT_PosDcContStuckOpen : 36|2@1+ (1,0) [0|3] ""  NF_Controller
 SG_ BATT_PosDcContWelded : 34|2@1+ (1,0) [0|3] ""  NF_Controller
 SG_ BATT_NegDcContStuckOpen : 32|2@1+ (1,0) [0|3] ""  NF_Controller
 SG_ BATT_NegDcContWelded : 46|2@1+ (1,0) [0|3] ""  NF_Controller
 SG_ BATT_PrechgTooFast : 44|2@1+ (1,0) [0|3] ""  NF_Controller
 SG_ BATT_PrechgContWelded : 42|2@1+ (1,0) [0|3] ""  NF_Controller
 SG_ BATT_PrechgTimeout : 40|2@1+ (1,0) [0|3] ""  NF_Controller
 SG_ BATT_PrechgContStuckOpen : 54|2@1+ (1,0) [0|3] ""  NF_Controller
 SG_ BATT_ModuleImbalance : 52|2@1+ (1,0) [0|3] ""  NF_Controller
 SG_ BATT_ModuleMIA : 50|2@1+ (1,0) [0|3] ""  NF_Controller
 SG_ BATT_SensePackVoltError : 48|2@1+ (1,0) [0|3] ""  NF_Controller
 SG_ BATT_SenseLoadVoltError : 62|2@1+ (1,0) [0|3] ""  NF_Controller
 SG_ BATT_SenseShuntError : 60|2@1+ (1,0) [0|3] ""  NF_Controller
 SG_ BATT_SenseFcVoltErrorr : 58|2@1+ (1,0) [0|3] ""  NF_Controller
 SG_ BATT_SenseBrickOpen : 56|2@1+ (1,0) [0|3] ""  NF_Controller

BO_ 2499759204 BATT_Diagnostic_System_B: 8 BMS_Controller
 SG_ BATT_SenseBrickImpHigh : 2|2@1+ (1,0) [0|3] ""  NF_Controller
 SG_ BATT_AFEfault : 0|2@1+ (1,0) [0|3] ""  NF_Controller
 SG_ BATT_AFEerror : 14|2@1+ (1,0) [0|3] ""  NF_Controller
 SG_ BATT_HostMIA : 12|2@1+ (1,0) [0|3] ""  NF_Controller
 SG_ BATT_TempAmbientOverSev : 10|2@1+ (1,0) [0|3] ""  NF_Controller
 SG_ BATT_TempAmbientOverMod : 8|2@1+ (1,0) [0|3] ""  NF_Controller
 SG_ BATT_TempAmbientOverWar : 22|2@1+ (1,0) [0|3] ""  NF_Controller
 SG_ BATT_AbnormReset : 20|2@1+ (1,0) [0|3] ""  NF_Controller
 SG_ BATT_SenseAuxVoltError : 18|2@1+ (1,0) [0|3] ""  NF_Controller
 SG_ BATT_CalibrationInvalid : 16|2@1+ (1,0) [0|3] ""  NF_Controller
 SG_ BATT_TaskLockup : 30|2@1+ (1,0) [0|3] ""  NF_Controller
 SG_ BATT_RAMover : 28|2@1+ (1,0) [0|3] ""  NF_Controller
 SG_ BATT_BrickOverdischarge : 26|2@1+ (1,0) [0|3] ""  NF_Controller
 SG_ BATT_BrickOvercharge : 24|2@1+ (1,0) [0|3] ""  NF_Controller
 SG_ BATT_vBrickImbalance : 38|2@1+ (1,0) [0|3] ""  NF_Controller
 SG_ BATT_TempBrickImbalance : 36|2@1+ (1,0) [0|3] ""  NF_Controller
 SG_ BATT_CapPackLow : 34|2@1+ (1,0) [0|3] ""  NF_Controller
 SG_ BATT_rBrickHigh : 32|2@1+ (1,0) [0|3] ""  NF_Controller
 SG_ BATT_PowerpackInsuffErr : 46|2@1+ (1,0) [0|3] ""  NF_Controller
 SG_ BATT_BrickSoftShort : 44|2@1+ (1,0) [0|3] ""  NF_Controller
 SG_ BATT_chargeUndercurrent : 42|2@1+ (1,0) [0|3] ""  NF_Controller
 SG_ BATT_HVILcurrentSourceError : 40|2@1+ (1,0) [0|3] ""  NF_Controller
 SG_ BATT_SRS : 54|2@1+ (1,0) [0|3] ""  NF_Controller
 SG_ BATT_IsolationExtWar : 52|2@1+ (1,0) [0|3] ""  NF_Controller
 SG_ BATT_IsolationIntWar : 50|2@1+ (1,0) [0|3] ""  NF_Controller
 SG_ BATT_PyroFuseBlown : 48|2@1+ (1,0) [0|3] ""  NF_Controller
 SG_ BATT_vBrickUnderSev : 62|2@1+ (1,0) [0|3] ""  NF_Controller
 SG_ BATT_chargePrechargeTimeout : 60|2@1+ (1,0) [0|3] ""  NF_Controller
 SG_ BATT_ModuleThermistorShort : 58|2@1+ (1,0) [0|3] ""  NF_Controller
 SG_ BATT_ModuleThermistorBroken : 56|2@1+ (1,0) [0|3] ""  NF_Controller

BO_ 2499759460 BATT_Diagnostic_System_C: 8 BMS_Controller
 SG_ BATT_HVILvoltageError : 2|2@1+ (1,0) [0|3] ""  NF_Controller
 SG_ BATT_HVILcurrentReturnError : 0|2@1+ (1,0) [0|3] ""  NF_Controller
 SG_ BATT_PosFcContWelded : 14|2@1+ (1,0) [0|3] ""  NF_Controller
 SG_ BATT_PosFcContStuckOpen : 12|2@1+ (1,0) [0|3] ""  NF_Controller
 SG_ BATT_NegFcContWelded : 10|2@1+ (1,0) [0|3] ""  NF_Controller
 SG_ BATT_NegFcContStuckOpen : 8|2@1+ (1,0) [0|3] ""  NF_Controller
 SG_ BATT_IsospiBreak : 22|2@1+ (1,0) [0|3] ""  NF_Controller
 SG_ BATT_IsolationIntFault : 20|2@1+ (1,0) [0|3] ""  NF_Controller
 SG_ BATT_IsolationExtFault : 18|2@1+ (1,0) [0|3] ""  NF_Controller
 SG_ BATT_event_12v_filter_error : 16|2@1+ (1,0) [0|3] ""  NF_Controller
 SG_ BATT_event_hall_eff_hi_rang_err : 30|2@1+ (1,0) [0|3] ""  NF_Controller
 SG_ BATT_event_brick_volt_sns_open : 28|2@1+ (1,0) [0|3] ""  NF_Controller
 SG_ BATT_event_5v_error : 26|2@1+ (1,0) [0|3] ""  NF_Controller
 SG_ BATT_event_3_3_hot_error : 24|2@1+ (1,0) [0|3] ""  NF_Controller
 SG_ BATT_event_12v_input_error : 38|2@1+ (1,0) [0|3] ""  NF_Controller
 SG_ BATT_event_1_25v_error : 36|2@1+ (1,0) [0|3] ""  NF_Controller
 SG_ BATT_event_shunt_MIA : 34|2@1+ (1,0) [0|3] ""  NF_Controller
 SG_ BATT_event_SBC_int_reg_error : 32|2@1+ (1,0) [0|3] ""  NF_Controller
 SG_ BATT_event_pos_3_3v_analog_error : 46|2@1+ (1,0) [0|3] ""  NF_Controller
 SG_ BATT_event_outlt_clnt_thrm_open : 44|2@1+ (1,0) [0|3] ""  NF_Controller
 SG_ BATT_event_neg_3_3_analog_error : 42|2@1+ (1,0) [0|3] ""  NF_Controller
 SG_ BATT_event_inlet_clnt_thrm_open : 40|2@1+ (1,0) [0|3] ""  NF_Controller
 SG_ BATT_event_hall_eff_lo_rang_err : 54|2@1+ (1,0) [0|3] ""  NF_Controller
 SG_ BATT_event_outlt_clnt_thrm_short : 52|2@1+ (1,0) [0|3] ""  NF_Controller
 SG_ BATT_event_inlet_clnt_thrm_short : 50|2@1+ (1,0) [0|3] ""  NF_Controller
 SG_ BATT_event_3_3v_error : 48|2@1+ (1,0) [0|3] ""  NF_Controller

BO_ 2499759716 BATT_Diagnostic_System_D: 8 BMS_Controller

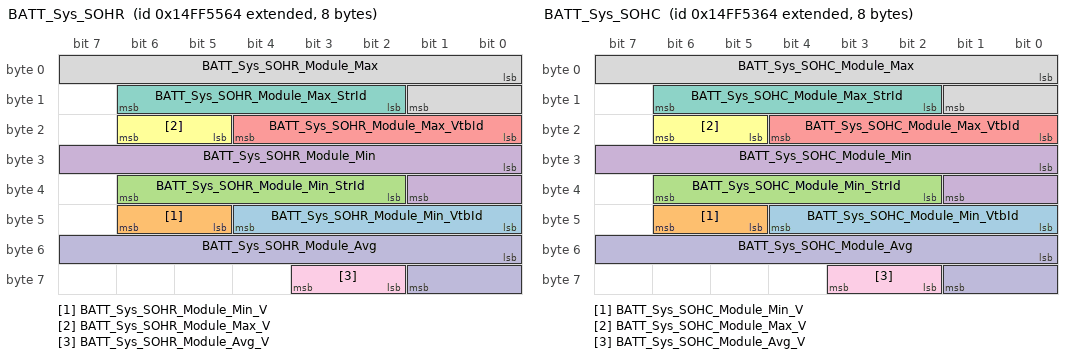
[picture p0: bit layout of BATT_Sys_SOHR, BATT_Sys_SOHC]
BO_ 2499761508 BATT_Sys_SOHR: 8 BMS_Controller
 SG_ BATT_Sys_SOHR_Module_Min_VtbId : 40|5@1+ (1,0) [0|29] "Index"  NF_Controller
 SG_ BATT_Sys_SOHR_Module_Min_V : 45|2@1+ (1,0) [0|3] ""  NF_Controller
 SG_ BATT_Sys_SOHR_Module_Min_StrId : 34|5@1+ (1,101) [101|124] "Index"  NF_Controller
 SG_ BATT_Sys_SOHR_Module_Min : 24|10@1+ (0.1,0) [0|100] "%"  NF_Controller
 SG_ BATT_Sys_SOHR_Module_Max_VtbId : 16|5@1+ (1,0) [0|29] "Index"  NF_Controller
 SG_ BATT_Sys_SOHR_Module_Max_V : 21|2@1+ (1,0) [0|3] ""  NF_Controller
 SG_ BATT_Sys_SOHR_Module_Max_StrId : 10|5@1+ (1,101) [101|124] "Index"  NF_Controller
 SG_ BATT_Sys_SOHR_Module_Max : 0|10@1+ (0.1,0) [0|100] "%"  NF_Controller
 SG_ BATT_Sys_SOHR_Module_Avg_V : 58|2@1+ (1,0) [0|3] ""  NF_Controller
 SG_ BATT_Sys_SOHR_Module_Avg : 48|10@1+ (0.1,0) [0|100] "%"  NF_Controller

BO_ 2499760996 BATT_Sys_SOHC: 8 BMS_Controller
 SG_ BATT_Sys_SOHC_Module_Min_VtbId : 40|5@1+ (1,0) [0|29] "Index"  NF_Controller
 SG_ BATT_Sys_SOHC_Module_Min_V : 45|2@1+ (1,0) [0|3] ""  NF_Controller
 SG_ BATT_Sys_SOHC_Module_Min_StrId : 34|5@1+ (1,101) [101|124] "Index"  NF_Controller
 SG_ BATT_Sys_SOHC_Module_Min : 24|10@1+ (0.1,0) [0|100] "%"  NF_Controller
 SG_ BATT_Sys_SOHC_Module_Max_VtbId : 16|5@1+ (1,0) [0|29] "Index"  NF_Controller
 SG_ BATT_Sys_SOHC_Module_Max_V : 21|2@1+ (1,0) [0|3] ""  NF_Controller
 SG_ BATT_Sys_SOHC_Module_Max_StrId : 10|5@1+ (1,101) [101|124] "Index"  NF_Controller
 SG_ BATT_Sys_SOHC_Module_Max : 0|10@1+ (0.1,0) [0|100] "%"  NF_Controller
 SG_ BATT_Sys_SOHC_Module_Avg_V : 58|2@1+ (1,0) [0|3] ""  NF_Controller
 SG_ BATT_Sys_SOHC_Module_Avg : 48|10@1+ (0.1,0) [0|100] "%"  NF_Controller

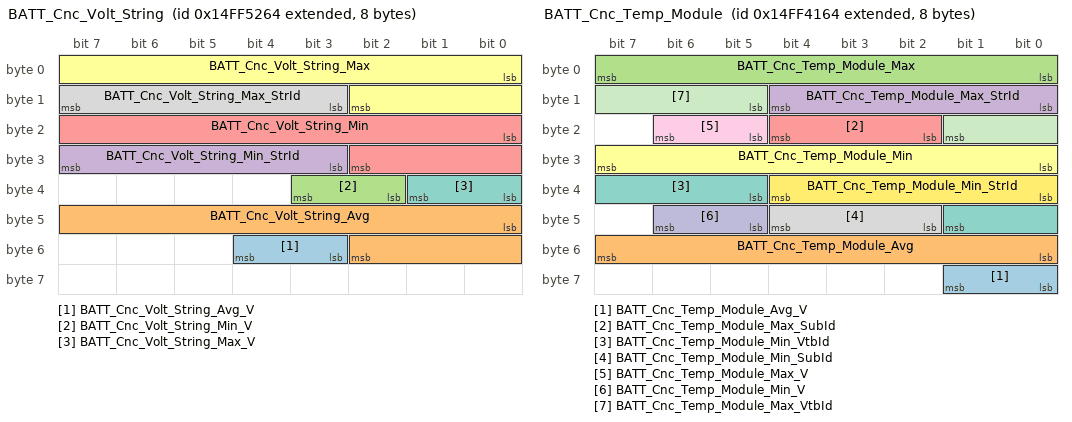
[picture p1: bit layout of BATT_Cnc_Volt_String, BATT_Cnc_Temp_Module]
BO_ 2499760740 BATT_Cnc_Volt_String: 8 BMS_Controller
 SG_ BATT_Cnc_Volt_String_Avg_V : 51|2@1+ (1,0) [0|3] ""  NF_Controller
 SG_ BATT_Cnc_Volt_String_Avg : 40|11@1+ (1,0) [0|1250] "Volts"  NF_Controller
 SG_ BATT_Cnc_Volt_String_Min_V : 34|2@1+ (1,0) [0|3] ""  NF_Controller
 SG_ BATT_Cnc_Volt_String_Min_StrId : 27|5@1+ (1,101) [101|124] "Index"  NF_Controller
 SG_ BATT_Cnc_Volt_String_Min : 16|11@1+ (1,0) [0|1250] "Volts"  NF_Controller
 SG_ BATT_Cnc_Volt_String_Max : 0|11@1+ (1,0) [0|1250] "Volts"  NF_Controller
 SG_ BATT_Cnc_Volt_String_Max_V : 32|2@1+ (1,0) [0|3] ""  NF_Controller
 SG_ BATT_Cnc_Volt_String_Max_StrId : 11|5@1+ (1,101) [101|124] "Index"  NF_Controller

BO_ 2499756388 BATT_Cnc_Temp_Module: 8 BMS_Controller
 SG_ BATT_Cnc_Temp_Module_Avg_V : 56|2@1+ (1,0) [0|3] ""  NF_Controller
 SG_ BATT_Cnc_Temp_Module_Avg : 48|8@1+ (1,-40) [-40|200] "Degree C"  NF_Controller
 SG_ BATT_Cnc_Temp_Module_Max : 0|8@1+ (1,-40) [-40|200] "Degree C"  NF_Controller
 SG_ BATT_Cnc_Temp_Module_Max_StrId : 8|5@1+ (1,101) [101|124] "Index"  NF_Controller
 SG_ BATT_Cnc_Temp_Module_Max_SubId : 18|3@1+ (1,0) [1|4] "Index"  NF_Controller
 SG_ BATT_Cnc_Temp_Module_Min : 24|8@1+ (1,-40) [-40|200] "Degree C"  NF_Controller
 SG_ BATT_Cnc_Temp_Module_Min_VtbId : 37|5@1+ (1,0) [0|29] "Index"  NF_Controller
 SG_ BATT_Cnc_Temp_Module_Min_SubId : 42|3@1+ (1,0) [1|4] "Index"  NF_Controller
 SG_ BATT_Cnc_Temp_Module_Max_V : 21|2@1+ (1,0) [0|3] ""  NF_Controller
 SG_ BATT_Cnc_Temp_Module_Min_V : 45|2@1+ (1,0) [0|3] ""  NF_Controller
 SG_ BATT_Cnc_Temp_Module_Max_VtbId : 13|5@1+ (1,0) [0|29] "Index"  NF_Controller
 SG_ BATT_Cnc_Temp_Module_Min_StrId : 32|5@1+ (1,101) [101|124] "Index"  NF_Controller

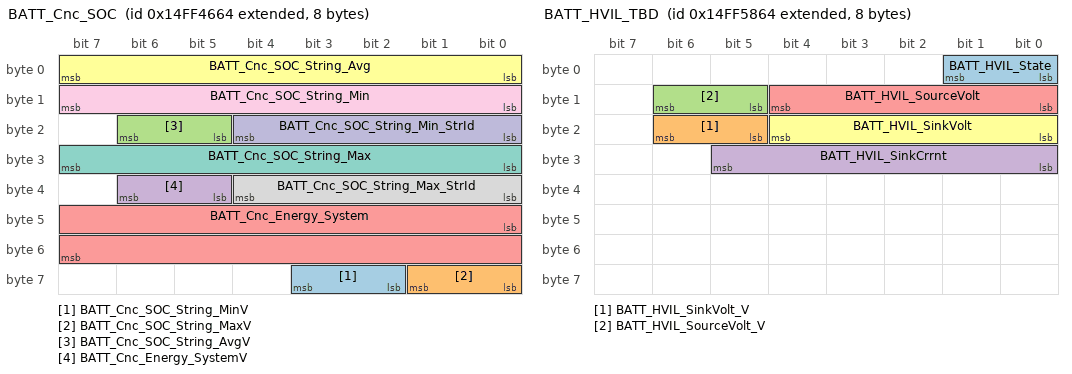
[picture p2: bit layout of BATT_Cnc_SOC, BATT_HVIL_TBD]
BO_ 2499757668 BATT_Cnc_SOC: 8 BMS_Controller
 SG_ BATT_Cnc_SOC_String_MinV : 58|2@1+ (1,0) [0|3] ""  NF_Controller
 SG_ BATT_Cnc_SOC_String_MaxV : 56|2@1+ (1,0) [0|3] ""  NF_Controller
 SG_ BATT_Cnc_SOC_String_AvgV : 21|2@1+ (1,0) [0|3] ""  NF_Controller
 SG_ BATT_Cnc_Energy_SystemV : 37|2@1+ (1,0) [0|3] ""  NF_Controller
 SG_ BATT_Cnc_Energy_System : 40|16@1+ (0.01,0) [0|655.35] "KWh"  NF_Controller
 SG_ BATT_Cnc_SOC_String_Avg : 0|8@1+ (0.4,0) [0|100] "%"  NF_Controller
 SG_ BATT_Cnc_SOC_String_Max : 24|8@1+ (0.4,0) [0|100] "%"  NF_Controller
 SG_ BATT_Cnc_SOC_String_Max_StrId : 32|5@1+ (1,101) [101|124] "Index"  NF_Controller
 SG_ BATT_Cnc_SOC_String_Min : 8|8@1+ (0.4,0) [0|100] "%"  NF_Controller
 SG_ BATT_Cnc_SOC_String_Min_StrId : 16|5@1+ (1,101) [101|124] "Index"  NF_Controller

BO_ 2499762276 BATT_HVIL_TBD: 8 BMS_Controller
 SG_ BATT_HVIL_State : 0|2@1+ (1,0) [0|3] ""  NF_Controller
 SG_ BATT_HVIL_SinkVolt_V : 21|2@1+ (1,0) [0|3] ""  NF_Controller
 SG_ BATT_HVIL_SourceVolt_V : 13|2@1+ (1,0) [0|3] ""  NF_Controller
 SG_ BATT_HVIL_SinkCrrnt : 24|6@1+ (1,0) [0|50] "mA"  NF_Controller
 SG_ BATT_HVIL_SourceVolt : 8|5@1+ (1,0) [0|29] "Volts"  NF_Controller
 SG_ BATT_HVIL_SinkVolt : 16|5@1+ (1,0) [0|29] "Volts"  NF_Controller

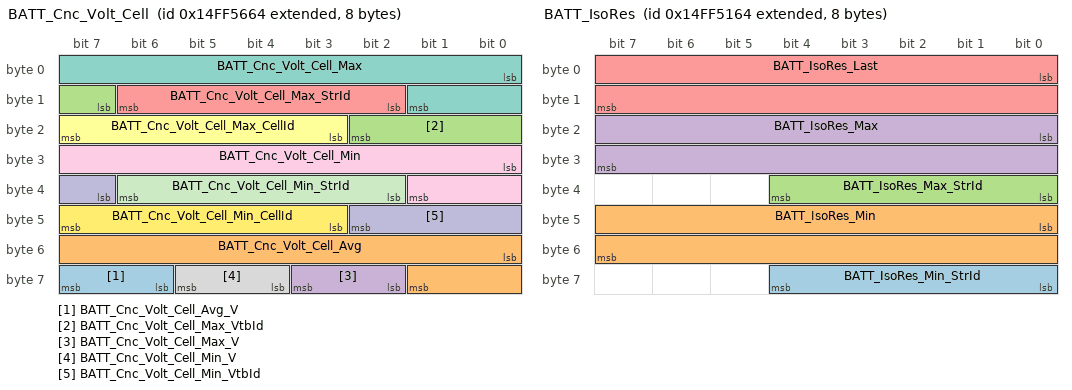
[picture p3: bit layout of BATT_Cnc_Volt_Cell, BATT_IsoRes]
BO_ 2499761764 BATT_Cnc_Volt_Cell: 8 BMS_Controller
 SG_ BATT_Cnc_Volt_Cell_Avg_V : 62|2@1+ (1,0) [0|3] ""  NF_Controller
 SG_ BATT_Cnc_Volt_Cell_Avg : 48|10@1+ (0.005,0) [0|5.115] "Volts"  NF_Controller
 SG_ BATT_Cnc_Volt_Cell_Max_VtbId : 15|4@1+ (1,1) [0|16] "Index"  NF_Controller
 SG_ BATT_Cnc_Volt_Cell_Max_V : 58|2@1+ (1,0) [0|3] ""  NF_Controller
 SG_ BATT_Cnc_Volt_Cell_Max_StrId : 10|5@1+ (1,101) [101|124] "Index"  NF_Controller
 SG_ BATT_Cnc_Volt_Cell_Max_CellId : 19|5@1+ (1,0) [0|31] "Index"  NF_Controller
 SG_ BATT_Cnc_Volt_Cell_Max : 0|10@1+ (0.005,0) [0|5.115] "Volts"  NF_Controller
 SG_ BATT_Cnc_Volt_Cell_Min_V : 60|2@1+ (1,0) [0|3] ""  NF_Controller
 SG_ BATT_Cnc_Volt_Cell_Min : 24|10@1+ (0.005,0) [0|5.115] "Volts"  NF_Controller
 SG_ BATT_Cnc_Volt_Cell_Min_VtbId : 39|4@1+ (1,1) [0|16] "Index"  NF_Controller
 SG_ BATT_Cnc_Volt_Cell_Min_StrId : 34|5@1+ (1,101) [101|124] "Index"  NF_Controller
 SG_ BATT_Cnc_Volt_Cell_Min_CellId : 43|5@1+ (1,0) [0|31] "Index"  NF_Controller

BO_ 2499760484 BATT_IsoRes: 8 BMS_Controller
 SG_ BATT_IsoRes_Min_StrId : 56|5@1+ (1,101) [101|124] "Index"  NF_Controller
 SG_ BATT_IsoRes_Min : 40|16@1+ (10,0) [0|655330] "kOhms"  NF_Controller
 SG_ BATT_IsoRes_Max_StrId : 32|5@1+ (1,101) [101|124] "Index"  NF_Controller
 SG_ BATT_IsoRes_Max : 16|16@1+ (10,0) [0|655330] "kOhms"  NF_Controller
 SG_ BATT_IsoRes_Last : 0|16@1+ (10,0) [0|655330] "kOhms"  NF_Controller

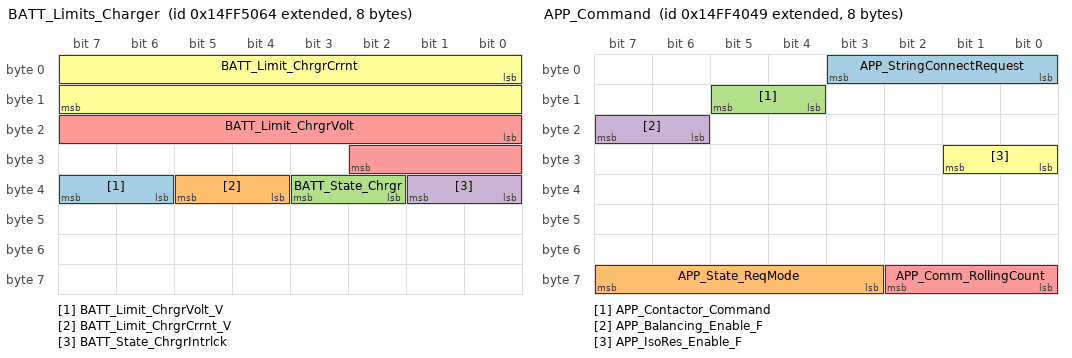
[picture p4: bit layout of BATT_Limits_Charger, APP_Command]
BO_ 2499760228 BATT_Limits_Charger: 8 BMS_Controller
 SG_ BATT_Limit_ChrgrVolt_V : 38|2@1+ (1,0) [0|3] ""  NF_Controller
 SG_ BATT_Limit_ChrgrCrrnt_V : 36|2@1+ (1,0) [0|3] ""  NF_Controller
 SG_ BATT_State_Chrgr : 34|2@1+ (1,0) [0|3] ""  NF_Controller
 SG_ BATT_State_ChrgrIntrlck : 32|2@1+ (1,0) [0|3] ""  NF_Controller
 SG_ BATT_Limit_ChrgrVolt : 16|11@1+ (1,0) [0|2047] "Volts"  NF_Controller
 SG_ BATT_Limit_ChrgrCrrnt : 0|16@1+ (0.5,0) [0|16000] "Amps"  NF_Controller

BO_ 2499756105 APP_Command: 8 NF_Controller
 SG_ APP_StringConnectRequest : 0|4@1+ (1,0) [0|15] ""  BMS_Controller
 SG_ APP_State_ReqMode : 59|5@1+ (1,0) [0|4] ""  BMS_Controller
 SG_ APP_Contactor_Command : 12|2@1+ (1,0) [0|3] ""  BMS_Controller
 SG_ APP_Balancing_Enable_F : 22|2@1+ (1,0) [0|3] ""  BMS_Controller
 SG_ APP_Comm_RollingCount : 56|3@1+ (1,0) [0|7] "Count"  BMS_Controller
 SG_ APP_IsoRes_Enable_F : 24|2@1+ (1,0) [0|3] ""  BMS_Controller

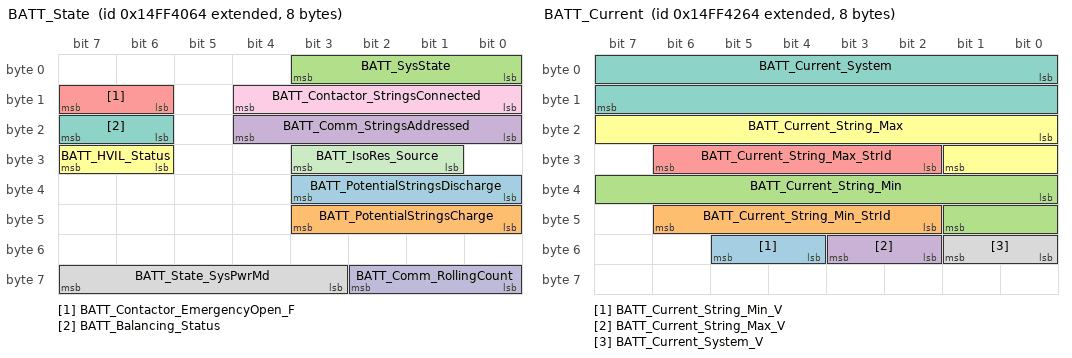
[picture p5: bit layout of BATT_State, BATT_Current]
BO_ 2499756132 BATT_State: 8 BMS_Controller
 SG_ BATT_PotentialStringsDischarge : 32|4@1+ (1,0) [0|15] "" Vector__XXX
 SG_ BATT_PotentialStringsCharge : 40|4@1+ (1,0) [0|15] "" Vector__XXX
 SG_ BATT_SysState : 0|4@1+ (1,0) [0|15] "" Vector__XXX
 SG_ BATT_Comm_StringsAddressed : 16|5@1+ (1,0) [0|24] "Count"  NF_Controller
 SG_ BATT_Contactor_EmergencyOpen_F : 14|2@1+ (1,0) [0|3] ""  NF_Controller
 SG_ BATT_HVIL_Status : 30|2@1+ (1,0) [0|3] ""  NF_Controller
 SG_ BATT_Balancing_Status : 22|2@1+ (1,0) [0|3] ""  NF_Controller
 SG_ BATT_State_SysPwrMd : 59|5@1+ (1,0) [0|5] ""  NF_Controller
 SG_ BATT_Contactor_StringsConnected : 8|5@1+ (1,0) [0|24] "Count"  NF_Controller
 SG_ BATT_Comm_RollingCount : 56|3@1+ (1,0) [0|7] "Count"  NF_Controller
 SG_ BATT_IsoRes_Source : 25|3@1+ (1,0) [0|7] ""  NF_Controller

BO_ 2499756644 BATT_Current: 8 BMS_Controller
 SG_ BATT_Current_String_Min_V : 52|2@1+ (1,0) [0|3] ""  NF_Controller
 SG_ BATT_Current_String_Min_StrId : 42|5@1+ (1,101) [101|124] "Index"  NF_Controller
 SG_ BATT_Current_String_Min : 32|10@1+ (1,-500) [-500|500] "Amps"  NF_Controller
 SG_ BATT_Current_String_Max_V : 50|2@1+ (1,0) [0|3] ""  NF_Controller
 SG_ BATT_Current_String_Max_StrId : 26|5@1+ (1,101) [101|124] "Index"  NF_Controller
 SG_ BATT_Current_String_Max : 16|10@1+ (1,-500) [-500|500] "Amps"  NF_Controller
 SG_ BATT_Current_System : 0|16@1+ (0.5,-16000) [-16000|16000] "Amps"  NF_Controller
 SG_ BATT_Current_System_V : 48|2@1+ (1,0) [0|3] ""  NF_Controller

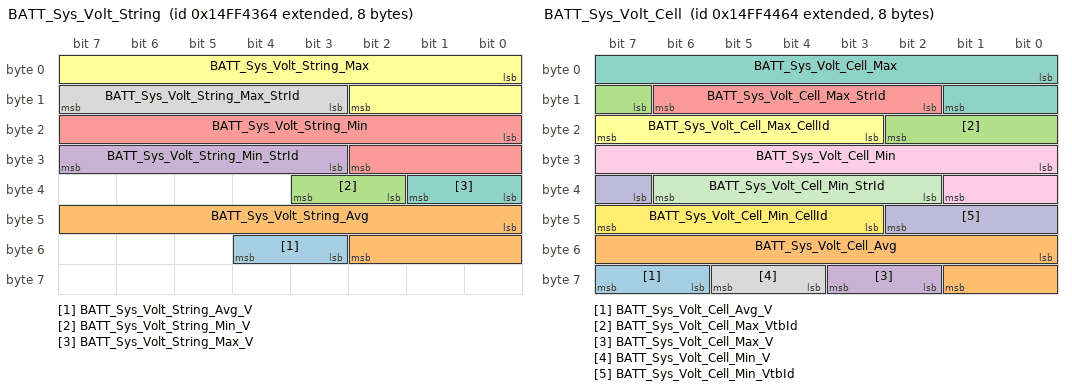
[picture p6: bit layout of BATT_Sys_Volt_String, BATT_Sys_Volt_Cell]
BO_ 2499756900 BATT_Sys_Volt_String: 8 BMS_Controller
 SG_ BATT_Sys_Volt_String_Avg_V : 51|2@1+ (1,0) [0|3] ""  NF_Controller
 SG_ BATT_Sys_Volt_String_Avg : 40|11@1+ (1,0) [0|1250] "Volts"  NF_Controller
 SG_ BATT_Sys_Volt_String_Min_V : 34|2@1+ (1,0) [0|3] ""  NF_Controller
 SG_ BATT_Sys_Volt_String_Min_StrId : 27|5@1+ (1,101) [101|124] "Index"  NF_Controller
 SG_ BATT_Sys_Volt_String_Min : 16|11@1+ (1,0) [0|1250] "Volts"  NF_Controller
 SG_ BATT_Sys_Volt_String_Max : 0|11@1+ (1,0) [0|1250] "Volts"  NF_Controller
 SG_ BATT_Sys_Volt_String_Max_V : 32|2@1+ (1,0) [0|3] ""  NF_Controller
 SG_ BATT_Sys_Volt_String_Max_StrId : 11|5@1+ (1,101) [101|124] "Index"  NF_Controller

BO_ 2499757156 BATT_Sys_Volt_Cell: 8 BMS_Controller
 SG_ BATT_Sys_Volt_Cell_Avg_V : 62|2@1+ (1,0) [0|3] ""  NF_Controller
 SG_ BATT_Sys_Volt_Cell_Avg : 48|10@1+ (0.005,0) [0|5.115] "Volts"  NF_Controller
 SG_ BATT_Sys_Volt_Cell_Max_VtbId : 15|4@1+ (1,0) [0|15] "Index"  NF_Controller
 SG_ BATT_Sys_Volt_Cell_Max_V : 58|2@1+ (1,0) [0|3] ""  NF_Controller
 SG_ BATT_Sys_Volt_Cell_Max_StrId : 10|5@1+ (1,101) [101|124] "Index"  NF_Controller
 SG_ BATT_Sys_Volt_Cell_Max_CellId : 19|5@1+ (1,0) [0|31] "Index"  NF_Controller
 SG_ BATT_Sys_Volt_Cell_Max : 0|10@1+ (0.005,0) [0|5.115] "Volts"  NF_Controller
 SG_ BATT_Sys_Volt_Cell_Min_V : 60|2@1+ (1,0) [0|3] ""  NF_Controller
 SG_ BATT_Sys_Volt_Cell_Min : 24|10@1+ (0.005,0) [0|5.115] "Volts"  NF_Controller
 SG_ BATT_Sys_Volt_Cell_Min_VtbId : 39|4@1+ (1,0) [0|31] "Index"  NF_Controller
 SG_ BATT_Sys_Volt_Cell_Min_StrId : 34|5@1+ (1,101) [101|124] "Index"  NF_Controller
 SG_ BATT_Sys_Volt_Cell_Min_CellId : 43|5@1+ (1,0) [0|31] "Index"  NF_Controller

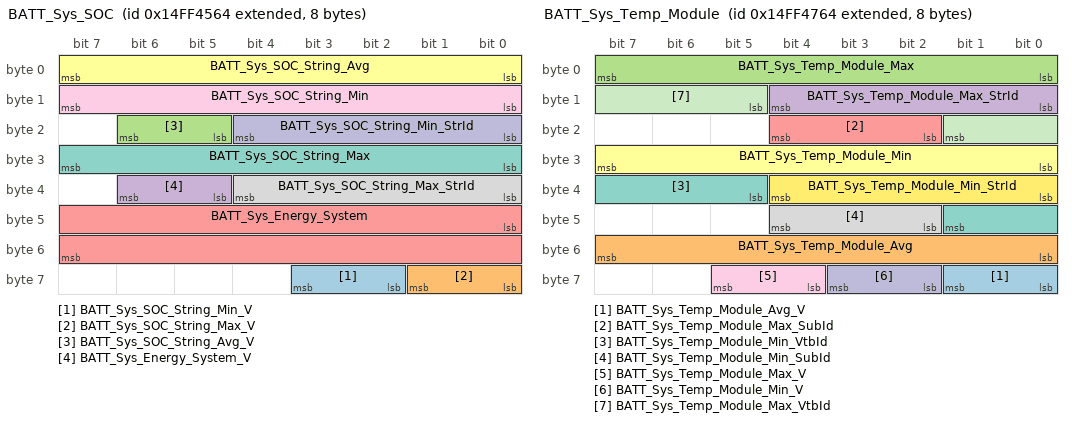
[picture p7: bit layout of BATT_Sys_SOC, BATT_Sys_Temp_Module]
BO_ 2499757412 BATT_Sys_SOC: 8 BMS_Controller
 SG_ BATT_Sys_SOC_String_Min_V : 58|2@1+ (1,0) [0|3] ""  NF_Controller
 SG_ BATT_Sys_SOC_String_Max_V : 56|2@1+ (1,0) [0|3] ""  NF_Controller
 SG_ BATT_Sys_SOC_String_Avg_V : 21|2@1+ (1,0) [0|3] ""  NF_Controller
 SG_ BATT_Sys_Energy_System_V : 37|2@1+ (1,0) [0|3] ""  NF_Controller
 SG_ BATT_Sys_Energy_System : 40|16@1+ (0.01,0) [0|655.35] "KWh"  NF_Controller
 SG_ BATT_Sys_SOC_String_Avg : 0|8@1+ (0.4,0) [0|100] "%"  NF_Controller
 SG_ BATT_Sys_SOC_String_Max : 24|8@1+ (0.4,0) [0|100] "%"  NF_Controller
 SG_ BATT_Sys_SOC_String_Max_StrId : 32|5@1+ (1,101) [101|124] "Index"  NF_Controller
 SG_ BATT_Sys_SOC_String_Min : 8|8@1+ (0.4,0) [0|100] "%"  NF_Controller
 SG_ BATT_Sys_SOC_String_Min_StrId : 16|5@1+ (1,101) [101|124] "Index"  NF_Controller

BO_ 2499757924 BATT_Sys_Temp_Module: 8 BMS_Controller
 SG_ BATT_Sys_Temp_Module_Avg_V : 56|2@1+ (1,0) [0|3] ""  NF_Controller
 SG_ BATT_Sys_Temp_Module_Avg : 48|8@1+ (1,-40) [-40|200] "Degree C"  NF_Controller
 SG_ BATT_Sys_Temp_Module_Max : 0|8@1+ (1,-40) [-40|200] "Degree C"  NF_Controller
 SG_ BATT_Sys_Temp_Module_Max_StrId : 8|5@1+ (1,101) [101|124] "Index"  NF_Controller
 SG_ BATT_Sys_Temp_Module_Max_SubId : 18|3@1+ (1,0) [1|4] "Index"  NF_Controller
 SG_ BATT_Sys_Temp_Module_Min : 24|8@1+ (1,-40) [-40|200] "Degree C"  NF_Controller
 SG_ BATT_Sys_Temp_Module_Min_VtbId : 37|5@1+ (1,0) [0|29] "Index"  NF_Controller
 SG_ BATT_Sys_Temp_Module_Min_SubId : 42|3@1+ (1,0) [1|4] "Index"  NF_Controller
 SG_ BATT_Sys_Temp_Module_Max_V : 60|2@1+ (1,0) [0|3] ""  NF_Controller
 SG_ BATT_Sys_Temp_Module_Min_V : 58|2@1+ (1,0) [0|3] ""  NF_Controller
 SG_ BATT_Sys_Temp_Module_Max_VtbId : 13|5@1+ (1,0) [0|29] "Index"  NF_Controller
 SG_ BATT_Sys_Temp_Module_Min_StrId : 32|5@1+ (1,101) [101|124] "Index"  NF_Controller

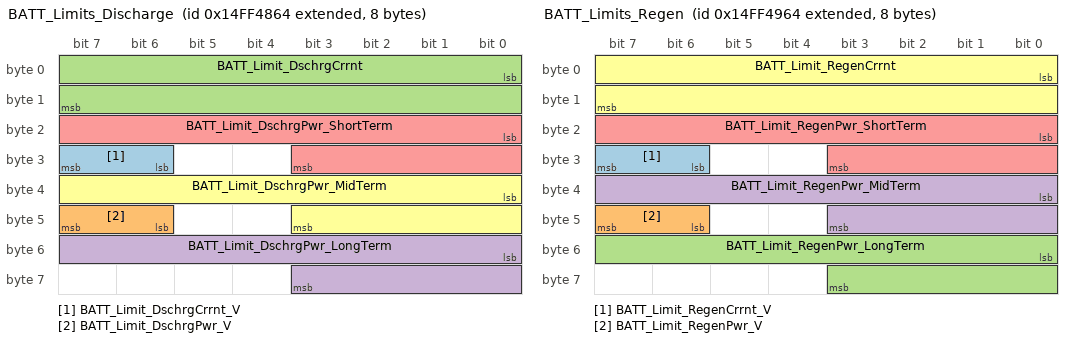
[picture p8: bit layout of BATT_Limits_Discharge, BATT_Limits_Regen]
BO_ 2499758180 BATT_Limits_Discharge: 8 BMS_Controller
 SG_ BATT_Limit_DschrgCrrnt_V : 30|2@1+ (1,0) [0|3] ""  NF_Controller
 SG_ BATT_Limit_DschrgPwr_V : 46|2@1+ (1,0) [0|3] ""  NF_Controller
 SG_ BATT_Limit_DschrgCrrnt : 0|16@1+ (0.5,0) [0|16000] "Amps"  NF_Controller
 SG_ BATT_Limit_DschrgPwr_LongTerm : 48|12@1+ (1,0) [0|4095] "KW"  NF_Controller
 SG_ BATT_Limit_DschrgPwr_ShortTerm : 16|12@1+ (1,0) [0|4095] "KW"  NF_Controller
 SG_ BATT_Limit_DschrgPwr_MidTerm : 32|12@1+ (1,0) [0|4095] "KW"  NF_Controller

BO_ 2499758436 BATT_Limits_Regen: 8 BMS_Controller
 SG_ BATT_Limit_RegenCrrnt_V : 30|2@1+ (1,0) [0|3] ""  NF_Controller
 SG_ BATT_Limit_RegenPwr_V : 46|2@1+ (1,0) [0|3] ""  NF_Controller
 SG_ BATT_Limit_RegenPwr_LongTerm : 48|12@1+ (1,0) [0|4095] "KW"  NF_Controller
 SG_ BATT_Limit_RegenPwr_MidTerm : 32|12@1+ (1,0) [0|4095] "KW"  NF_Controller
 SG_ BATT_Limit_RegenPwr_ShortTerm : 16|12@1+ (1,0) [0|4095] "KW"  NF_Controller
 SG_ BATT_Limit_RegenCrrnt : 0|16@1+ (0.5,0) [0|16000] "Amps"  NF_Controller

CM_ BO_ 2499761508 "SOH  signals communicating string resistance information calculated from all strings.";
CM_ BO_ 2499760996 "SOH signals communicating string capacity related information calculated from all strings.";
CM_ BO_ 2499760740 "String Voltage signals communicating string information limted to strings that are connected to High Voltage (contactors closed).";
CM_ BO_ 2499756388 "Temperature signals communicating string information limted to strings that are connected to High Voltage (contactors closed).";
CM_ BO_ 2499757668 "SOC / Energy signals communicating string information limted to strings that are connected to High Voltage (contactors closed).";
CM_ BO_ 2499762276 "HVIL information as reported by the Application - BMS Interface (Master Contrl Unit).";
CM_ BO_ 2499761764 "Voltage signals communicating string information limted to strings that are connected to High Voltage (contactors closed).";
CM_ BO_ 2499760484 "This message contains the results from the last Isolation Resistance Test.  The system always runs an Isolation Test after contactors open and may run an Isolation Test at start-up.  See integration guide for more information";
CM_ BO_ 2499760228 "Signals related to Charging Limits, are calculated by the Battery Management System.";
CM_ BO_ 2499756105 "This Message is the only message that is required for the XPAND System to operate. See individual signal comments and the Integration Guide.";
CM_ SG_ 2499756105 APP_State_ReqMode "A signal from the Application that requests that the Battery Management System enter Charge/Discharge Mode.
This only works if Contactor_Command is Close & APP_Comm_RollingCount is incrementing.
See Value Descriptions";
CM_ SG_ 2499756105 APP_Contactor_Command "A signal from the Application that requests that the Battery Management System closes contactors.
This only works if App_StateReqMode is Charge/Discharge & APP_Comm_RollingCount is incrementing.
See Value Descriptions";
CM_ SG_ 2499756105 APP_Balancing_Enable_F "Signal from the Application that communicates to the Battery Management System that Cell Balance (if neccessary) is allowed.
See Value Descriptions tab for more information.";
CM_ SG_ 2499756105 APP_Comm_RollingCount "An incrementing signal from the Application that the Battery Management System used to calculate freshness.
The Application should increment (with rollover) this signal every time it's message is transmitted to the Battery Management System.

";
CM_ SG_ 2499756105 APP_IsoRes_Enable_F "CURRENTLY NOT SUPPORTED.  Signal from the Application that communicates to the Battery Management System that Runtime Isolation Detection is allowed.
See Value Descriptions tab for more information.";
CM_ BO_ 2499756132 "These signals communicate the state of the Battery Management System.  Look here for an overal understanding of the state of the BMS.";
CM_ SG_ 2499756132 BATT_Comm_StringsAddressed "This signal communicates the number of strings addressed at initialization";
CM_ SG_ 2499756132 BATT_Contactor_EmergencyOpen_F "This signal communicates if there was a Battery Management Fault that necessitated the contactors opening immediately.  If this happens, there will be a Fault flag set in BATT_Diagnostics
";
CM_ SG_ 2499756132 BATT_HVIL_Status "This signal communicates the high level status of the HVIL.   See the Value Description";
CM_ SG_ 2499756132 BATT_Balancing_Status "This signal communicates if a string in the BMS is currently balancing. See the Value Description";
CM_ SG_ 2499756132 BATT_State_SysPwrMd "This signal communicates the overal state of the System. When in Partial Run or Run, one or more strings are connected to High Voltage.";
CM_ SG_ 2499756132 BATT_Contactor_StringsConnected "This signal communicates the number of strings connected to High Voltage at any given time.";
CM_ SG_ 2499756132 BATT_Comm_RollingCount "An ever incrementing signal that the Application can chose to monitor to ensure the BMS is sending fresh information with each message.";
CM_ SG_ 2499756132 BATT_IsoRes_Source "The results of the Isolation Test can be recovered from NVM or it can be from recently running the Isolation Test.  This signal communicates the source of the results.";
CM_ BO_ 2499756644 "Signals related to String Current as calculated by the Battery Management System.";
CM_ BO_ 2499756900 "String Voltage signals communicating string information calculated from all strings connected or not connected.";
CM_ BO_ 2499757156 "Cell Voltage signals communicating string information calculated from all strings connected or not connected.";
CM_ BO_ 2499757412 "SOC / Energy signals communicating string information calculated from all strings connected or not connected.";
CM_ BO_ 2499757924 "Temperature signals communicating string information calculated from all strings connected or not connected.";
CM_ BO_ 2499758180 "Signals related to Discharging Limits, are calculated by the Battery Management System.";
CM_ BO_ 2499758436 "Signals related to Regen Limits, are calculated by the Battery Management System.";
BA_DEF_ SG_  "SigType" ENUM  "Default","Range","RangeSigned","ASCII","Discrete","Control","ReferencePGN","DTC","StringDelimiter","StringLength","StringLengthControl","MessageCounter","MessageChecksum";
BA_DEF_ SG_  "GenSigEVName" STRING ;
BA_DEF_ SG_  "GenSigILSupport" ENUM  "No","Yes";
BA_DEF_ SG_  "GenSigSendType" ENUM  "Cyclic","OnWrite","OnWriteWithRepetition","OnChange","OnChangeWithRepetition","IfActive","IfActiveWithRepetition","NoSigSendType";
BA_DEF_ SG_  "GenSigStartValue" INT 0 10000;
BA_DEF_ BO_  "GenMsgILSupport" ENUM  "No","Yes";
BA_DEF_ BO_  "GenMsgSendType" ENUM  "cyclic","NotUsed","IfActive","NotUsed","NotUsed","NotUsed","NotUsed","NotUsed","noMsgSendType";
BA_DEF_ BO_  "GenMsgRequestable" INT 0 1;
BA_DEF_ BO_  "GenMsgCycleTime" INT 0 3600000;
BA_DEF_ SG_  "SPN" INT 0 524287;
BA_DEF_ BO_  "VFrameFormat" ENUM  "StandardCAN","ExtendedCAN","reserved","J1939PG";
BA_DEF_ SG_  "SystemSignalLongSymbol" STRING ;
BA_DEF_DEF_  "SigType" "Default";
BA_DEF_DEF_  "GenSigEVName" "Env@Nodename_@Signame";
BA_DEF_DEF_  "GenSigILSupport" "Yes";
BA_DEF_DEF_  "GenSigSendType" "NoSigSendType";
BA_DEF_DEF_  "GenSigStartValue" 0;
BA_DEF_DEF_  "GenMsgILSupport" "Yes";
BA_DEF_DEF_  "GenMsgSendType" "noMsgSendType";
BA_DEF_DEF_  "GenMsgRequestable" 1;
BA_DEF_DEF_  "GenMsgCycleTime" 0;
BA_DEF_DEF_  "SPN" 0;
BA_DEF_DEF_  "VFrameFormat" "J1939PG";
BA_DEF_DEF_  "SystemSignalLongSymbol" "";
BA_ "VFrameFormat" BO_ 2499762532 1;
BA_ "GenMsgSendType" BO_ 2499762532 0;
BA_ "VFrameFormat" BO_ 2499758948 1;
BA_ "GenMsgCycleTime" BO_ 2499758948 200;
BA_ "GenMsgSendType" BO_ 2499758948 0;
BA_ "GenMsgCycleTime" BO_ 2499759204 200;
BA_ "GenMsgSendType" BO_ 2499759204 0;
BA_ "VFrameFormat" BO_ 2499759204 1;
BA_ "GenMsgCycleTime" BO_ 2499759460 200;
BA_ "GenMsgSendType" BO_ 2499759460 0;
BA_ "VFrameFormat" BO_ 2499759460 1;
BA_ "VFrameFormat" BO_ 2499759716 1;
BA_ "GenMsgSendType" BO_ 2499759716 0;
BA_ "GenMsgCycleTime" BO_ 2499759716 200;
BA_ "GenMsgSendType" BO_ 2499761508 0;
BA_ "GenMsgCycleTime" BO_ 2499761508 5000;
BA_ "GenMsgSendType" BO_ 2499760996 0;
BA_ "GenMsgCycleTime" BO_ 2499760996 5000;
BA_ "GenMsgCycleTime" BO_ 2499760740 100;
BA_ "GenMsgSendType" BO_ 2499760740 0;
BA_ "GenMsgCycleTime" BO_ 2499756388 1000;
BA_ "GenMsgSendType" BO_ 2499756388 0;
BA_ "GenMsgCycleTime" BO_ 2499757668 500;
BA_ "GenMsgSendType" BO_ 2499757668 0;
BA_ "GenMsgCycleTime" BO_ 2499762276 100;
BA_ "GenMsgSendType" BO_ 2499762276 0;
BA_ "GenMsgSendType" BO_ 2499761764 0;
BA_ "GenMsgCycleTime" BO_ 2499761764 100;
BA_ "GenMsgCycleTime" BO_ 2499760484 100;
BA_ "GenMsgSendType" BO_ 2499760484 0;
BA_ "GenMsgCycleTime" BO_ 2499760228 1000;
BA_ "GenMsgSendType" BO_ 2499760228 0;
BA_ "GenMsgCycleTime" BO_ 2499756105 100;
BA_ "GenMsgSendType" BO_ 2499756105 0;
BA_ "GenMsgCycleTime" BO_ 2499756132 100;
BA_ "GenMsgSendType" BO_ 2499756132 0;
BA_ "GenMsgCycleTime" BO_ 2499756644 100;
BA_ "GenMsgSendType" BO_ 2499756644 0;
BA_ "GenMsgCycleTime" BO_ 2499756900 100;
BA_ "GenMsgSendType" BO_ 2499756900 0;
BA_ "GenMsgCycleTime" BO_ 2499757156 100;
BA_ "GenMsgSendType" BO_ 2499757156 0;
BA_ "GenMsgCycleTime" BO_ 2499757412 500;
BA_ "GenMsgSendType" BO_ 2499757412 0;
BA_ "GenMsgCycleTime" BO_ 2499757924 1000;
BA_ "GenMsgSendType" BO_ 2499757924 0;
BA_ "GenMsgCycleTime" BO_ 2499758180 1000;
BA_ "GenMsgSendType" BO_ 2499758180 0;
BA_ "GenMsgCycleTime" BO_ 2499758436 1000;
BA_ "GenMsgSendType" BO_ 2499758436 0;
BA_ "GenSigStartValue" SG_ 2499762532 BATT_01_vBrickOverSev 2;
BA_ "GenSigStartValue" SG_ 2499762532 BATT_01_vBrickOverMod 2;
BA_ "GenSigStartValue" SG_ 2499762532 BATT_01_vBrickOverWar 2;
BA_ "GenSigStartValue" SG_ 2499762532 BATT_01_HostQuiet 2;
BA_ "GenSigStartValue" SG_ 2499762532 BATT_01_vBrickUnderMod 2;
BA_ "GenSigStartValue" SG_ 2499762532 BATT_01_vBrickUnderWar 2;
BA_ "GenSigStartValue" SG_ 2499762532 BATT_01_TempModuleOverSev 2;
BA_ "GenSigStartValue" SG_ 2499762532 BATT_01_TempModuleOverMod 2;
BA_ "GenSigStartValue" SG_ 2499762532 BATT_01_TempModuleOverWar 2;
BA_ "GenSigStartValue" SG_ 2499762532 BATT_01_TempModuleUnderSev 2;
BA_ "GenSigStartValue" SG_ 2499762532 BATT_01_TempModuleUnderMod 2;
BA_ "GenSigStartValue" SG_ 2499762532 BATT_01_TempModuleUnderWar 2;
BA_ "GenSigStartValue" SG_ 2499762532 BATT_01_iOvercharge 2;
BA_ "GenSigStartValue" SG_ 2499762532 BATT_01_iOverdischarge 2;
BA_ "GenSigStartValue" SG_ 2499762532 BATT_01_iOverHardware 2;
BA_ "GenSigStartValue" SG_ 2499762532 BATT_01_PosDcContStuckOpen 2;
BA_ "GenSigStartValue" SG_ 2499762532 BATT_01_PosDcContWelded 2;
BA_ "GenSigStartValue" SG_ 2499762532 BATT_01_NegDcContStuckOpen 2;
BA_ "GenSigStartValue" SG_ 2499762532 BATT_01_NegDcContWelded 2;
BA_ "GenSigStartValue" SG_ 2499762532 BATT_01_PrechgTooFast 2;
BA_ "GenSigStartValue" SG_ 2499762532 BATT_01_PrechgContWelded 2;
BA_ "GenSigStartValue" SG_ 2499762532 BATT_01_PrechgTimeout 2;
BA_ "GenSigStartValue" SG_ 2499762532 BATT_01_PrechgContStuckOpen 2;
BA_ "GenSigStartValue" SG_ 2499762532 BATT_01_ModuleImbalance 2;
BA_ "GenSigStartValue" SG_ 2499762532 BATT_01_ModuleMIA 2;
BA_ "GenSigStartValue" SG_ 2499762532 BATT_01_SensePackVoltError 2;
BA_ "GenSigStartValue" SG_ 2499762532 BATT_01_SenseLoadVoltError 2;
BA_ "GenSigStartValue" SG_ 2499762532 BATT_01_SenseShuntError 2;
BA_ "GenSigStartValue" SG_ 2499762532 BATT_01_SenseFcVoltErrorr 2;
BA_ "GenSigStartValue" SG_ 2499762532 BATT_01_SenseBrickOpen 2;
BA_ "GenSigStartValue" SG_ 2499762532 BATT_02_vBrickOverSev 2;
BA_ "GenSigStartValue" SG_ 2499762532 BATT_02_vBrickOverMod 2;
BA_ "GenSigStartValue" SG_ 2499762532 BATT_02_vBrickOverWar 2;
BA_ "GenSigStartValue" SG_ 2499762532 BATT_02_HostQuiet 2;
BA_ "GenSigStartValue" SG_ 2499762532 BATT_02_vBrickUnderMod 2;
BA_ "GenSigStartValue" SG_ 2499762532 BATT_02_vBrickUnderWar 2;
BA_ "GenSigStartValue" SG_ 2499762532 BATT_02_TempModuleOverSev 2;
BA_ "GenSigStartValue" SG_ 2499762532 BATT_02_TempModuleOverMod 2;
BA_ "GenSigStartValue" SG_ 2499762532 BATT_02_TempModuleOverWar 2;
BA_ "GenSigStartValue" SG_ 2499762532 BATT_02_TempModuleUnderSev 2;
BA_ "GenSigStartValue" SG_ 2499762532 BATT_02_TempModuleUnderMod 2;
BA_ "GenSigStartValue" SG_ 2499762532 BATT_02_TempModuleUnderWar 2;
BA_ "GenSigStartValue" SG_ 2499762532 BATT_02_iOvercharge 2;
BA_ "GenSigStartValue" SG_ 2499762532 BATT_02_iOverdischarge 2;
BA_ "GenSigStartValue" SG_ 2499762532 BATT_02_iOverHardware 2;
BA_ "GenSigStartValue" SG_ 2499762532 BATT_02_PosDcContStuckOpen 2;
BA_ "GenSigStartValue" SG_ 2499762532 BATT_02_PosDcContWelded 2;
BA_ "GenSigStartValue" SG_ 2499762532 BATT_02_NegDcContStuckOpen 2;
BA_ "GenSigStartValue" SG_ 2499762532 BATT_02_NegDcContWelded 2;
BA_ "GenSigStartValue" SG_ 2499762532 BATT_02_PrechgTooFast 2;
BA_ "GenSigStartValue" SG_ 2499762532 BATT_02_PrechgContWelded 2;
BA_ "GenSigStartValue" SG_ 2499762532 BATT_02_PrechgTimeout 2;
BA_ "GenSigStartValue" SG_ 2499762532 BATT_02_PrechgContStuckOpen 2;
BA_ "GenSigStartValue" SG_ 2499762532 BATT_02_ModuleImbalance 2;
BA_ "GenSigStartValue" SG_ 2499762532 BATT_02_ModuleMIA 2;
BA_ "GenSigStartValue" SG_ 2499762532 BATT_02_SensePackVoltError 2;
BA_ "GenSigStartValue" SG_ 2499762532 BATT_02_SenseLoadVoltError 2;
BA_ "GenSigStartValue" SG_ 2499762532 BATT_02_SenseShuntError 2;
BA_ "GenSigStartValue" SG_ 2499762532 BATT_02_SenseFcVoltErrorr 2;
BA_ "GenSigStartValue" SG_ 2499762532 BATT_02_SenseBrickOpen 2;
BA_ "GenSigStartValue" SG_ 2499762532 BATT_03_vBrickOverSev 2;
BA_ "GenSigStartValue" SG_ 2499762532 BATT_03_vBrickOverMod 2;
BA_ "GenSigStartValue" SG_ 2499762532 BATT_03_vBrickOverWar 2;
BA_ "GenSigStartValue" SG_ 2499762532 BATT_03_HostQuiet 2;
BA_ "GenSigStartValue" SG_ 2499762532 BATT_03_vBrickUnderMod 2;
BA_ "GenSigStartValue" SG_ 2499762532 BATT_03_vBrickUnderWar 2;
BA_ "GenSigStartValue" SG_ 2499762532 BATT_03_TempModuleOverSev 2;
BA_ "GenSigStartValue" SG_ 2499762532 BATT_03_TempModuleOverMod 2;
BA_ "GenSigStartValue" SG_ 2499762532 BATT_03_TempModuleOverWar 2;
BA_ "GenSigStartValue" SG_ 2499762532 BATT_03_TempModuleUnderSev 2;
BA_ "GenSigStartValue" SG_ 2499762532 BATT_03_TempModuleUnderMod 2;
BA_ "GenSigStartValue" SG_ 2499762532 BATT_03_TempModuleUnderWar 2;
BA_ "GenSigStartValue" SG_ 2499762532 BATT_03_iOvercharge 2;
BA_ "GenSigStartValue" SG_ 2499762532 BATT_03_iOverdischarge 2;
BA_ "GenSigStartValue" SG_ 2499762532 BATT_03_iOverHardware 2;
BA_ "GenSigStartValue" SG_ 2499762532 BATT_03_PosDcContStuckOpen 2;
BA_ "GenSigStartValue" SG_ 2499762532 BATT_03_PosDcContWelded 2;
BA_ "GenSigStartValue" SG_ 2499762532 BATT_03_NegDcContStuckOpen 2;
BA_ "GenSigStartValue" SG_ 2499762532 BATT_03_NegDcContWelded 2;
BA_ "GenSigStartValue" SG_ 2499762532 BATT_03_PrechgTooFast 2;
BA_ "GenSigStartValue" SG_ 2499762532 BATT_03_PrechgContWelded 2;
BA_ "GenSigStartValue" SG_ 2499762532 BATT_03_PrechgTimeout 2;
BA_ "GenSigStartValue" SG_ 2499762532 BATT_03_PrechgContStuckOpen 2;
BA_ "GenSigStartValue" SG_ 2499762532 BATT_03_ModuleImbalance 2;
BA_ "GenSigStartValue" SG_ 2499762532 BATT_03_ModuleMIA 2;
BA_ "GenSigStartValue" SG_ 2499762532 BATT_03_SensePackVoltError 2;
BA_ "GenSigStartValue" SG_ 2499762532 BATT_03_SenseLoadVoltError 2;
BA_ "GenSigStartValue" SG_ 2499762532 BATT_03_SenseShuntError 2;
BA_ "GenSigStartValue" SG_ 2499762532 BATT_03_SenseFcVoltErrorr 2;
BA_ "GenSigStartValue" SG_ 2499762532 BATT_03_SenseBrickOpen 2;
BA_ "GenSigStartValue" SG_ 2499762532 BATT_04_vBrickOverSev 2;
BA_ "GenSigStartValue" SG_ 2499762532 BATT_04_vBrickOverMod 2;
BA_ "GenSigStartValue" SG_ 2499762532 BATT_04_vBrickOverWar 2;
BA_ "GenSigStartValue" SG_ 2499762532 BATT_04_HostQuiet 2;
BA_ "GenSigStartValue" SG_ 2499762532 BATT_04_vBrickUnderMod 2;
BA_ "GenSigStartValue" SG_ 2499762532 BATT_04_vBrickUnderWar 2;
BA_ "GenSigStartValue" SG_ 2499762532 BATT_04_TempModuleOverSev 2;
BA_ "GenSigStartValue" SG_ 2499762532 BATT_04_TempModuleOverMod 2;
BA_ "GenSigStartValue" SG_ 2499762532 BATT_04_TempModuleOverWar 2;
BA_ "GenSigStartValue" SG_ 2499762532 BATT_04_TempModuleUnderSev 2;
BA_ "GenSigStartValue" SG_ 2499762532 BATT_04_TempModuleUnderMod 2;
BA_ "GenSigStartValue" SG_ 2499762532 BATT_04_TempModuleUnderWar 2;
BA_ "GenSigStartValue" SG_ 2499762532 BATT_04_iOvercharge 2;
BA_ "GenSigStartValue" SG_ 2499762532 BATT_04_iOverdischarge 2;
BA_ "GenSigStartValue" SG_ 2499762532 BATT_04_iOverHardware 2;
BA_ "GenSigStartValue" SG_ 2499762532 BATT_04_PosDcContStuckOpen 2;
BA_ "GenSigStartValue" SG_ 2499762532 BATT_04_PosDcContWelded 2;
BA_ "GenSigStartValue" SG_ 2499762532 BATT_04_NegDcContStuckOpen 2;
BA_ "GenSigStartValue" SG_ 2499762532 BATT_04_NegDcContWelded 2;
BA_ "GenSigStartValue" SG_ 2499762532 BATT_04_PrechgTooFast 2;
BA_ "GenSigStartValue" SG_ 2499762532 BATT_04_PrechgContWelded 2;
BA_ "GenSigStartValue" SG_ 2499762532 BATT_04_PrechgTimeout 2;
BA_ "GenSigStartValue" SG_ 2499762532 BATT_04_PrechgContStuckOpen 2;
BA_ "GenSigStartValue" SG_ 2499762532 BATT_04_ModuleImbalance 2;
BA_ "GenSigStartValue" SG_ 2499762532 BATT_04_ModuleMIA 2;
BA_ "GenSigStartValue" SG_ 2499762532 BATT_04_SensePackVoltError 2;
BA_ "GenSigStartValue" SG_ 2499762532 BATT_04_SenseLoadVoltError 2;
BA_ "GenSigStartValue" SG_ 2499762532 BATT_04_SenseShuntError 2;
BA_ "GenSigStartValue" SG_ 2499762532 BATT_04_SenseFcVoltErrorr 2;
BA_ "GenSigStartValue" SG_ 2499762532 BATT_04_SenseBrickOpen 2;
BA_ "GenSigStartValue" SG_ 2499762532 BATT_05_vBrickOverSev 2;
BA_ "GenSigStartValue" SG_ 2499762532 BATT_05_vBrickOverMod 2;
BA_ "GenSigStartValue" SG_ 2499762532 BATT_05_vBrickOverWar 2;
BA_ "GenSigStartValue" SG_ 2499762532 BATT_05_HostQuiet 2;
BA_ "GenSigStartValue" SG_ 2499762532 BATT_05_vBrickUnderMod 2;
BA_ "GenSigStartValue" SG_ 2499762532 BATT_05_vBrickUnderWar 2;
BA_ "GenSigStartValue" SG_ 2499762532 BATT_05_TempModuleOverSev 2;
BA_ "GenSigStartValue" SG_ 2499762532 BATT_05_TempModuleOverMod 2;
BA_ "GenSigStartValue" SG_ 2499762532 BATT_05_TempModuleOverWar 2;
BA_ "GenSigStartValue" SG_ 2499762532 BATT_05_TempModuleUnderSev 2;
BA_ "GenSigStartValue" SG_ 2499762532 BATT_05_TempModuleUnderMod 2;
BA_ "GenSigStartValue" SG_ 2499762532 BATT_05_TempModuleUnderWar 2;
BA_ "GenSigStartValue" SG_ 2499762532 BATT_05_iOvercharge 2;
BA_ "GenSigStartValue" SG_ 2499762532 BATT_05_iOverdischarge 2;
BA_ "GenSigStartValue" SG_ 2499762532 BATT_05_iOverHardware 2;
BA_ "GenSigStartValue" SG_ 2499762532 BATT_05_PosDcContStuckOpen 2;
BA_ "GenSigStartValue" SG_ 2499762532 BATT_05_PosDcContWelded 2;
BA_ "GenSigStartValue" SG_ 2499762532 BATT_05_NegDcContStuckOpen 2;
BA_ "GenSigStartValue" SG_ 2499762532 BATT_05_NegDcContWelded 2;
BA_ "GenSigStartValue" SG_ 2499762532 BATT_05_PrechgTooFast 2;
BA_ "GenSigStartValue" SG_ 2499762532 BATT_05_PrechgContWelded 2;
BA_ "GenSigStartValue" SG_ 2499762532 BATT_05_PrechgTimeout 2;
BA_ "GenSigStartValue" SG_ 2499762532 BATT_05_PrechgContStuckOpen 2;
BA_ "GenSigStartValue" SG_ 2499762532 BATT_05_ModuleImbalance 2;
BA_ "GenSigStartValue" SG_ 2499762532 BATT_05_ModuleMIA 2;
BA_ "GenSigStartValue" SG_ 2499762532 BATT_05_SensePackVoltError 2;
BA_ "GenSigStartValue" SG_ 2499762532 BATT_05_SenseLoadVoltError 2;
BA_ "GenSigStartValue" SG_ 2499762532 BATT_05_SenseShuntError 2;
BA_ "GenSigStartValue" SG_ 2499762532 BATT_05_SenseFcVoltErrorr 2;
BA_ "GenSigStartValue" SG_ 2499762532 BATT_05_SenseBrickOpen 2;
BA_ "GenSigStartValue" SG_ 2499762532 BATT_06_vBrickOverSev 2;
BA_ "GenSigStartValue" SG_ 2499762532 BATT_06_vBrickOverMod 2;
BA_ "GenSigStartValue" SG_ 2499762532 BATT_06_vBrickOverWar 2;
BA_ "GenSigStartValue" SG_ 2499762532 BATT_06_HostQuiet 2;
BA_ "GenSigStartValue" SG_ 2499762532 BATT_06_vBrickUnderMod 2;
BA_ "GenSigStartValue" SG_ 2499762532 BATT_06_vBrickUnderWar 2;
BA_ "GenSigStartValue" SG_ 2499762532 BATT_06_TempModuleOverSev 2;
BA_ "GenSigStartValue" SG_ 2499762532 BATT_06_TempModuleOverMod 2;
BA_ "GenSigStartValue" SG_ 2499762532 BATT_06_TempModuleOverWar 2;
BA_ "GenSigStartValue" SG_ 2499762532 BATT_06_TempModuleUnderSev 2;
BA_ "GenSigStartValue" SG_ 2499762532 BATT_06_TempModuleUnderMod 2;
BA_ "GenSigStartValue" SG_ 2499762532 BATT_06_TempModuleUnderWar 2;
BA_ "GenSigStartValue" SG_ 2499762532 BATT_06_iOvercharge 2;
BA_ "GenSigStartValue" SG_ 2499762532 BATT_06_iOverdischarge 2;
BA_ "GenSigStartValue" SG_ 2499762532 BATT_06_iOverHardware 2;
BA_ "GenSigStartValue" SG_ 2499762532 BATT_06_PosDcContStuckOpen 2;
BA_ "GenSigStartValue" SG_ 2499762532 BATT_06_PosDcContWelded 2;
BA_ "GenSigStartValue" SG_ 2499762532 BATT_06_NegDcContStuckOpen 2;
BA_ "GenSigStartValue" SG_ 2499762532 BATT_06_NegDcContWelded 2;
BA_ "GenSigStartValue" SG_ 2499762532 BATT_06_PrechgTooFast 2;
BA_ "GenSigStartValue" SG_ 2499762532 BATT_06_PrechgContWelded 2;
BA_ "GenSigStartValue" SG_ 2499762532 BATT_06_PrechgTimeout 2;
BA_ "GenSigStartValue" SG_ 2499762532 BATT_06_PrechgContStuckOpen 2;
BA_ "GenSigStartValue" SG_ 2499762532 BATT_06_ModuleImbalance 2;
BA_ "GenSigStartValue" SG_ 2499762532 BATT_06_ModuleMIA 2;
BA_ "GenSigStartValue" SG_ 2499762532 BATT_06_SensePackVoltError 2;
BA_ "GenSigStartValue" SG_ 2499762532 BATT_06_SenseLoadVoltError 2;
BA_ "GenSigStartValue" SG_ 2499762532 BATT_06_SenseShuntError 2;
BA_ "GenSigStartValue" SG_ 2499762532 BATT_06_SenseFcVoltErrorr 2;
BA_ "GenSigStartValue" SG_ 2499762532 BATT_06_SenseBrickOpen 2;
BA_ "GenSigStartValue" SG_ 2499762532 BATT_07_vBrickOverSev 2;
BA_ "GenSigStartValue" SG_ 2499762532 BATT_07_vBrickOverMod 2;
BA_ "GenSigStartValue" SG_ 2499762532 BATT_07_vBrickOverWar 2;
BA_ "GenSigStartValue" SG_ 2499762532 BATT_07_HostQuiet 2;
BA_ "GenSigStartValue" SG_ 2499762532 BATT_07_vBrickUnderMod 2;
BA_ "GenSigStartValue" SG_ 2499762532 BATT_07_vBrickUnderWar 2;
BA_ "GenSigStartValue" SG_ 2499762532 BATT_07_TempModuleOverSev 2;
BA_ "GenSigStartValue" SG_ 2499762532 BATT_07_TempModuleOverMod 2;
BA_ "GenSigStartValue" SG_ 2499762532 BATT_07_TempModuleOverWar 2;
BA_ "GenSigStartValue" SG_ 2499762532 BATT_07_TempModuleUnderSev 2;
BA_ "GenSigStartValue" SG_ 2499762532 BATT_07_TempModuleUnderMod 2;
BA_ "GenSigStartValue" SG_ 2499762532 BATT_07_TempModuleUnderWar 2;
BA_ "GenSigStartValue" SG_ 2499762532 BATT_07_iOvercharge 2;
BA_ "GenSigStartValue" SG_ 2499762532 BATT_07_iOverdischarge 2;
BA_ "GenSigStartValue" SG_ 2499762532 BATT_07_iOverHardware 2;
BA_ "GenSigStartValue" SG_ 2499762532 BATT_07_PosDcContStuckOpen 2;
BA_ "GenSigStartValue" SG_ 2499762532 BATT_07_PosDcContWelded 2;
BA_ "GenSigStartValue" SG_ 2499762532 BATT_07_NegDcContStuckOpen 2;
BA_ "GenSigStartValue" SG_ 2499762532 BATT_07_NegDcContWelded 2;
BA_ "GenSigStartValue" SG_ 2499762532 BATT_07_PrechgTooFast 2;
BA_ "GenSigStartValue" SG_ 2499762532 BATT_07_PrechgContWelded 2;
BA_ "GenSigStartValue" SG_ 2499762532 BATT_07_PrechgTimeout 2;
BA_ "GenSigStartValue" SG_ 2499762532 BATT_07_PrechgContStuckOpen 2;
BA_ "GenSigStartValue" SG_ 2499762532 BATT_07_ModuleImbalance 2;
BA_ "GenSigStartValue" SG_ 2499762532 BATT_07_ModuleMIA 2;
BA_ "GenSigStartValue" SG_ 2499762532 BATT_07_SensePackVoltError 2;
BA_ "GenSigStartValue" SG_ 2499762532 BATT_07_SenseLoadVoltError 2;
BA_ "GenSigStartValue" SG_ 2499762532 BATT_07_SenseShuntError 2;
BA_ "GenSigStartValue" SG_ 2499762532 BATT_07_SenseFcVoltErrorr 2;
BA_ "GenSigStartValue" SG_ 2499762532 BATT_07_SenseBrickOpen 2;
BA_ "GenSigStartValue" SG_ 2499762532 BATT_08_vBrickOverSev 2;
BA_ "GenSigStartValue" SG_ 2499762532 BATT_08_vBrickOverMod 2;
BA_ "GenSigStartValue" SG_ 2499762532 BATT_08_vBrickOverWar 2;
BA_ "GenSigStartValue" SG_ 2499762532 BATT_08_HostQuiet 2;
BA_ "GenSigStartValue" SG_ 2499762532 BATT_08_vBrickUnderMod 2;
BA_ "GenSigStartValue" SG_ 2499762532 BATT_08_vBrickUnderWar 2;
BA_ "GenSigStartValue" SG_ 2499762532 BATT_08_TempModuleOverSev 2;
BA_ "GenSigStartValue" SG_ 2499762532 BATT_08_TempModuleOverMod 2;
BA_ "GenSigStartValue" SG_ 2499762532 BATT_08_TempModuleOverWar 2;
BA_ "GenSigStartValue" SG_ 2499762532 BATT_08_TempModuleUnderSev 2;
BA_ "GenSigStartValue" SG_ 2499762532 BATT_08_TempModuleUnderMod 2;
BA_ "GenSigStartValue" SG_ 2499762532 BATT_08_TempModuleUnderWar 2;
BA_ "GenSigStartValue" SG_ 2499762532 BATT_08_iOvercharge 2;
BA_ "GenSigStartValue" SG_ 2499762532 BATT_08_iOverdischarge 2;
BA_ "GenSigStartValue" SG_ 2499762532 BATT_08_iOverHardware 2;
BA_ "GenSigStartValue" SG_ 2499762532 BATT_08_PosDcContStuckOpen 2;
BA_ "GenSigStartValue" SG_ 2499762532 BATT_08_PosDcContWelded 2;
BA_ "GenSigStartValue" SG_ 2499762532 BATT_08_NegDcContStuckOpen 2;
BA_ "GenSigStartValue" SG_ 2499762532 BATT_08_NegDcContWelded 2;
BA_ "GenSigStartValue" SG_ 2499762532 BATT_08_PrechgTooFast 2;
BA_ "GenSigStartValue" SG_ 2499762532 BATT_08_PrechgContWelded 2;
BA_ "GenSigStartValue" SG_ 2499762532 BATT_08_PrechgTimeout 2;
BA_ "GenSigStartValue" SG_ 2499762532 BATT_08_PrechgContStuckOpen 2;
BA_ "GenSigStartValue" SG_ 2499762532 BATT_08_ModuleImbalance 2;
BA_ "GenSigStartValue" SG_ 2499762532 BATT_08_ModuleMIA 2;
BA_ "GenSigStartValue" SG_ 2499762532 BATT_08_SensePackVoltError 2;
BA_ "GenSigStartValue" SG_ 2499762532 BATT_08_SenseLoadVoltError 2;
BA_ "GenSigStartValue" SG_ 2499762532 BATT_08_SenseShuntError 2;
BA_ "GenSigStartValue" SG_ 2499762532 BATT_08_SenseFcVoltErrorr 2;
BA_ "GenSigStartValue" SG_ 2499762532 BATT_08_SenseBrickOpen 2;
BA_ "GenSigStartValue" SG_ 2499762532 BATT_09_vBrickOverSev 2;
BA_ "GenSigStartValue" SG_ 2499762532 BATT_09_vBrickOverMod 2;
BA_ "GenSigStartValue" SG_ 2499762532 BATT_09_vBrickOverWar 2;
BA_ "GenSigStartValue" SG_ 2499762532 BATT_09_HostQuiet 2;
BA_ "GenSigStartValue" SG_ 2499762532 BATT_09_vBrickUnderMod 2;
BA_ "GenSigStartValue" SG_ 2499762532 BATT_09_vBrickUnderWar 2;
BA_ "GenSigStartValue" SG_ 2499762532 BATT_09_TempModuleOverSev 2;
BA_ "GenSigStartValue" SG_ 2499762532 BATT_09_TempModuleOverMod 2;
BA_ "GenSigStartValue" SG_ 2499762532 BATT_09_TempModuleOverWar 2;
BA_ "GenSigStartValue" SG_ 2499762532 BATT_09_TempModuleUnderSev 2;
BA_ "GenSigStartValue" SG_ 2499762532 BATT_09_TempModuleUnderMod 2;
BA_ "GenSigStartValue" SG_ 2499762532 BATT_09_TempModuleUnderWar 2;
BA_ "GenSigStartValue" SG_ 2499762532 BATT_09_iOvercharge 2;
BA_ "GenSigStartValue" SG_ 2499762532 BATT_09_iOverdischarge 2;
BA_ "GenSigStartValue" SG_ 2499762532 BATT_09_iOverHardware 2;
BA_ "GenSigStartValue" SG_ 2499762532 BATT_09_PosDcContStuckOpen 2;
BA_ "GenSigStartValue" SG_ 2499762532 BATT_09_PosDcContWelded 2;
BA_ "GenSigStartValue" SG_ 2499762532 BATT_09_NegDcContStuckOpen 2;
BA_ "GenSigStartValue" SG_ 2499762532 BATT_09_NegDcContWelded 2;
BA_ "GenSigStartValue" SG_ 2499762532 BATT_09_PrechgTooFast 2;
BA_ "GenSigStartValue" SG_ 2499762532 BATT_09_PrechgContWelded 2;
BA_ "GenSigStartValue" SG_ 2499762532 BATT_09_PrechgTimeout 2;
BA_ "GenSigStartValue" SG_ 2499762532 BATT_09_PrechgContStuckOpen 2;
BA_ "GenSigStartValue" SG_ 2499762532 BATT_09_ModuleImbalance 2;
BA_ "GenSigStartValue" SG_ 2499762532 BATT_09_ModuleMIA 2;
BA_ "GenSigStartValue" SG_ 2499762532 BATT_09_SensePackVoltError 2;
BA_ "GenSigStartValue" SG_ 2499762532 BATT_09_SenseLoadVoltError 2;
BA_ "GenSigStartValue" SG_ 2499762532 BATT_09_SenseShuntError 2;
BA_ "GenSigStartValue" SG_ 2499762532 BATT_09_SenseFcVoltErrorr 2;
BA_ "GenSigStartValue" SG_ 2499762532 BATT_09_SenseBrickOpen 2;
BA_ "GenSigStartValue" SG_ 2499762532 BATT_10_vBrickOverSev 2;
BA_ "GenSigStartValue" SG_ 2499762532 BATT_10_vBrickOverMod 2;
BA_ "GenSigStartValue" SG_ 2499762532 BATT_10_vBrickOverWar 2;
BA_ "GenSigStartValue" SG_ 2499762532 BATT_10_HostQuiet 2;
BA_ "GenSigStartValue" SG_ 2499762532 BATT_10_vBrickUnderMod 2;
BA_ "GenSigStartValue" SG_ 2499762532 BATT_10_vBrickUnderWar 2;
BA_ "GenSigStartValue" SG_ 2499762532 BATT_10_TempModuleOverSev 2;
BA_ "GenSigStartValue" SG_ 2499762532 BATT_10_TempModuleOverMod 2;
BA_ "GenSigStartValue" SG_ 2499762532 BATT_10_TempModuleOverWar 2;
BA_ "GenSigStartValue" SG_ 2499762532 BATT_10_TempModuleUnderSev 2;
BA_ "GenSigStartValue" SG_ 2499762532 BATT_10_TempModuleUnderMod 2;
BA_ "GenSigStartValue" SG_ 2499762532 BATT_10_TempModuleUnderWar 2;
BA_ "GenSigStartValue" SG_ 2499762532 BATT_10_iOvercharge 2;
BA_ "GenSigStartValue" SG_ 2499762532 BATT_10_iOverdischarge 2;
BA_ "GenSigStartValue" SG_ 2499762532 BATT_10_iOverHardware 2;
BA_ "GenSigStartValue" SG_ 2499762532 BATT_10_PosDcContStuckOpen 2;
BA_ "GenSigStartValue" SG_ 2499762532 BATT_10_PosDcContWelded 2;
BA_ "GenSigStartValue" SG_ 2499762532 BATT_10_NegDcContStuckOpen 2;
BA_ "GenSigStartValue" SG_ 2499762532 BATT_10_NegDcContWelded 2;
BA_ "GenSigStartValue" SG_ 2499762532 BATT_10_PrechgTooFast 2;
BA_ "GenSigStartValue" SG_ 2499762532 BATT_10_PrechgContWelded 2;
BA_ "GenSigStartValue" SG_ 2499762532 BATT_10_PrechgTimeout 2;
BA_ "GenSigStartValue" SG_ 2499762532 BATT_10_PrechgContStuckOpen 2;
BA_ "GenSigStartValue" SG_ 2499762532 BATT_10_ModuleImbalance 2;
BA_ "GenSigStartValue" SG_ 2499762532 BATT_10_ModuleMIA 2;
BA_ "GenSigStartValue" SG_ 2499762532 BATT_10_SensePackVoltError 2;
BA_ "GenSigStartValue" SG_ 2499762532 BATT_10_SenseLoadVoltError 2;
BA_ "GenSigStartValue" SG_ 2499762532 BATT_10_SenseShuntError 2;
BA_ "GenSigStartValue" SG_ 2499762532 BATT_10_SenseFcVoltErrorr 2;
BA_ "GenSigStartValue" SG_ 2499762532 BATT_10_SenseBrickOpen 2;
BA_ "GenSigStartValue" SG_ 2499762532 BATT_11_vBrickOverSev 2;
BA_ "GenSigStartValue" SG_ 2499762532 BATT_11_vBrickOverMod 2;
BA_ "GenSigStartValue" SG_ 2499762532 BATT_11_vBrickOverWar 2;
BA_ "GenSigStartValue" SG_ 2499762532 BATT_11_HostQuiet 2;
BA_ "GenSigStartValue" SG_ 2499762532 BATT_11_vBrickUnderMod 2;
BA_ "GenSigStartValue" SG_ 2499762532 BATT_11_vBrickUnderWar 2;
BA_ "GenSigStartValue" SG_ 2499762532 BATT_11_TempModuleOverSev 2;
BA_ "GenSigStartValue" SG_ 2499762532 BATT_11_TempModuleOverMod 2;
BA_ "GenSigStartValue" SG_ 2499762532 BATT_11_TempModuleOverWar 2;
BA_ "GenSigStartValue" SG_ 2499762532 BATT_11_TempModuleUnderSev 2;
BA_ "GenSigStartValue" SG_ 2499762532 BATT_11_TempModuleUnderMod 2;
BA_ "GenSigStartValue" SG_ 2499762532 BATT_11_TempModuleUnderWar 2;
BA_ "GenSigStartValue" SG_ 2499762532 BATT_11_iOvercharge 2;
BA_ "GenSigStartValue" SG_ 2499762532 BATT_11_iOverdischarge 2;
BA_ "GenSigStartValue" SG_ 2499762532 BATT_11_iOverHardware 2;
BA_ "GenSigStartValue" SG_ 2499762532 BATT_11_PosDcContStuckOpen 2;
BA_ "GenSigStartValue" SG_ 2499762532 BATT_11_PosDcContWelded 2;
BA_ "GenSigStartValue" SG_ 2499762532 BATT_11_NegDcContStuckOpen 2;
BA_ "GenSigStartValue" SG_ 2499762532 BATT_11_NegDcContWelded 2;
BA_ "GenSigStartValue" SG_ 2499762532 BATT_11_PrechgTooFast 2;
BA_ "GenSigStartValue" SG_ 2499762532 BATT_11_PrechgContWelded 2;
BA_ "GenSigStartValue" SG_ 2499762532 BATT_11_PrechgTimeout 2;
BA_ "GenSigStartValue" SG_ 2499762532 BATT_11_PrechgContStuckOpen 2;
BA_ "GenSigStartValue" SG_ 2499762532 BATT_11_ModuleImbalance 2;
BA_ "GenSigStartValue" SG_ 2499762532 BATT_11_ModuleMIA 2;
BA_ "GenSigStartValue" SG_ 2499762532 BATT_11_SensePackVoltError 2;
BA_ "GenSigStartValue" SG_ 2499762532 BATT_11_SenseLoadVoltError 2;
BA_ "GenSigStartValue" SG_ 2499762532 BATT_11_SenseShuntError 2;
BA_ "GenSigStartValue" SG_ 2499762532 BATT_11_SenseFcVoltErrorr 2;
BA_ "GenSigStartValue" SG_ 2499762532 BATT_11_SenseBrickOpen 2;
BA_ "GenSigStartValue" SG_ 2499762532 BATT_12_vBrickOverSev 2;
BA_ "GenSigStartValue" SG_ 2499762532 BATT_12_vBrickOverMod 2;
BA_ "GenSigStartValue" SG_ 2499762532 BATT_12_vBrickOverWar 2;
BA_ "GenSigStartValue" SG_ 2499762532 BATT_12_HostQuiet 2;
BA_ "GenSigStartValue" SG_ 2499762532 BATT_12_vBrickUnderMod 2;
BA_ "GenSigStartValue" SG_ 2499762532 BATT_12_vBrickUnderWar 2;
BA_ "GenSigStartValue" SG_ 2499762532 BATT_12_TempModuleOverSev 2;
BA_ "GenSigStartValue" SG_ 2499762532 BATT_12_TempModuleOverMod 2;
BA_ "GenSigStartValue" SG_ 2499762532 BATT_12_TempModuleOverWar 2;
BA_ "GenSigStartValue" SG_ 2499762532 BATT_12_TempModuleUnderSev 2;
BA_ "GenSigStartValue" SG_ 2499762532 BATT_12_TempModuleUnderMod 2;
BA_ "GenSigStartValue" SG_ 2499762532 BATT_12_TempModuleUnderWar 2;
BA_ "GenSigStartValue" SG_ 2499762532 BATT_12_iOvercharge 2;
BA_ "GenSigStartValue" SG_ 2499762532 BATT_12_iOverdischarge 2;
BA_ "GenSigStartValue" SG_ 2499762532 BATT_12_iOverHardware 2;
BA_ "GenSigStartValue" SG_ 2499762532 BATT_12_PosDcContStuckOpen 2;
BA_ "GenSigStartValue" SG_ 2499762532 BATT_12_PosDcContWelded 2;
BA_ "GenSigStartValue" SG_ 2499762532 BATT_12_NegDcContStuckOpen 2;
BA_ "GenSigStartValue" SG_ 2499762532 BATT_12_NegDcContWelded 2;
BA_ "GenSigStartValue" SG_ 2499762532 BATT_12_PrechgTooFast 2;
BA_ "GenSigStartValue" SG_ 2499762532 BATT_12_PrechgContWelded 2;
BA_ "GenSigStartValue" SG_ 2499762532 BATT_12_PrechgTimeout 2;
BA_ "GenSigStartValue" SG_ 2499762532 BATT_12_PrechgContStuckOpen 2;
BA_ "GenSigStartValue" SG_ 2499762532 BATT_12_ModuleImbalance 2;
BA_ "GenSigStartValue" SG_ 2499762532 BATT_12_ModuleMIA 2;
BA_ "GenSigStartValue" SG_ 2499762532 BATT_12_SensePackVoltError 2;
BA_ "GenSigStartValue" SG_ 2499762532 BATT_12_SenseLoadVoltError 2;
BA_ "GenSigStartValue" SG_ 2499762532 BATT_12_SenseShuntError 2;
BA_ "GenSigStartValue" SG_ 2499762532 BATT_12_SenseFcVoltErrorr 2;
BA_ "GenSigStartValue" SG_ 2499762532 BATT_12_SenseBrickOpen 2;
BA_ "GenSigStartValue" SG_ 2499762532 BATT_13_vBrickOverSev 2;
BA_ "GenSigStartValue" SG_ 2499762532 BATT_13_vBrickOverMod 2;
BA_ "GenSigStartValue" SG_ 2499762532 BATT_13_vBrickOverWar 2;
BA_ "GenSigStartValue" SG_ 2499762532 BATT_13_HostQuiet 2;
BA_ "GenSigStartValue" SG_ 2499762532 BATT_13_vBrickUnderMod 2;
BA_ "GenSigStartValue" SG_ 2499762532 BATT_13_vBrickUnderWar 2;
BA_ "GenSigStartValue" SG_ 2499762532 BATT_13_TempModuleOverSev 2;
BA_ "GenSigStartValue" SG_ 2499762532 BATT_13_TempModuleOverMod 2;
BA_ "GenSigStartValue" SG_ 2499762532 BATT_13_TempModuleOverWar 2;
BA_ "GenSigStartValue" SG_ 2499762532 BATT_13_TempModuleUnderSev 2;
BA_ "GenSigStartValue" SG_ 2499762532 BATT_13_TempModuleUnderMod 2;
BA_ "GenSigStartValue" SG_ 2499762532 BATT_13_TempModuleUnderWar 2;
BA_ "GenSigStartValue" SG_ 2499762532 BATT_13_iOvercharge 2;
BA_ "GenSigStartValue" SG_ 2499762532 BATT_13_iOverdischarge 2;
BA_ "GenSigStartValue" SG_ 2499762532 BATT_13_iOverHardware 2;
BA_ "GenSigStartValue" SG_ 2499762532 BATT_13_PosDcContStuckOpen 2;
BA_ "GenSigStartValue" SG_ 2499762532 BATT_13_PosDcContWelded 2;
BA_ "GenSigStartValue" SG_ 2499762532 BATT_13_NegDcContStuckOpen 2;
BA_ "GenSigStartValue" SG_ 2499762532 BATT_13_NegDcContWelded 2;
BA_ "GenSigStartValue" SG_ 2499762532 BATT_13_PrechgTooFast 2;
BA_ "GenSigStartValue" SG_ 2499762532 BATT_13_PrechgContWelded 2;
BA_ "GenSigStartValue" SG_ 2499762532 BATT_13_PrechgTimeout 2;
BA_ "GenSigStartValue" SG_ 2499762532 BATT_13_PrechgContStuckOpen 2;
BA_ "GenSigStartValue" SG_ 2499762532 BATT_13_ModuleImbalance 2;
BA_ "GenSigStartValue" SG_ 2499762532 BATT_13_ModuleMIA 2;
BA_ "GenSigStartValue" SG_ 2499762532 BATT_13_SensePackVoltError 2;
BA_ "GenSigStartValue" SG_ 2499762532 BATT_13_SenseLoadVoltError 2;
BA_ "GenSigStartValue" SG_ 2499762532 BATT_13_SenseShuntError 2;
BA_ "GenSigStartValue" SG_ 2499762532 BATT_13_SenseFcVoltErrorr 2;
BA_ "GenSigStartValue" SG_ 2499762532 BATT_13_SenseBrickOpen 2;
BA_ "GenSigStartValue" SG_ 2499762532 BATT_14_vBrickOverSev 2;
BA_ "GenSigStartValue" SG_ 2499762532 BATT_14_vBrickOverMod 2;
BA_ "GenSigStartValue" SG_ 2499762532 BATT_14_vBrickOverWar 2;
BA_ "GenSigStartValue" SG_ 2499762532 BATT_14_HostQuiet 2;
BA_ "GenSigStartValue" SG_ 2499762532 BATT_14_vBrickUnderMod 2;
BA_ "GenSigStartValue" SG_ 2499762532 BATT_14_vBrickUnderWar 2;
BA_ "GenSigStartValue" SG_ 2499762532 BATT_14_TempModuleOverSev 2;
BA_ "GenSigStartValue" SG_ 2499762532 BATT_14_TempModuleOverMod 2;
BA_ "GenSigStartValue" SG_ 2499762532 BATT_14_TempModuleOverWar 2;
BA_ "GenSigStartValue" SG_ 2499762532 BATT_14_TempModuleUnderSev 2;
BA_ "GenSigStartValue" SG_ 2499762532 BATT_14_TempModuleUnderMod 2;
BA_ "GenSigStartValue" SG_ 2499762532 BATT_14_TempModuleUnderWar 2;
BA_ "GenSigStartValue" SG_ 2499762532 BATT_14_iOvercharge 2;
BA_ "GenSigStartValue" SG_ 2499762532 BATT_14_iOverdischarge 2;
BA_ "GenSigStartValue" SG_ 2499762532 BATT_14_iOverHardware 2;
BA_ "GenSigStartValue" SG_ 2499762532 BATT_14_PosDcContStuckOpen 2;
BA_ "GenSigStartValue" SG_ 2499762532 BATT_14_PosDcContWelded 2;
BA_ "GenSigStartValue" SG_ 2499762532 BATT_14_NegDcContStuckOpen 2;
BA_ "GenSigStartValue" SG_ 2499762532 BATT_14_NegDcContWelded 2;
BA_ "GenSigStartValue" SG_ 2499762532 BATT_14_PrechgTooFast 2;
BA_ "GenSigStartValue" SG_ 2499762532 BATT_14_PrechgContWelded 2;
BA_ "GenSigStartValue" SG_ 2499762532 BATT_14_PrechgTimeout 2;
BA_ "GenSigStartValue" SG_ 2499762532 BATT_14_PrechgContStuckOpen 2;
BA_ "GenSigStartValue" SG_ 2499762532 BATT_14_ModuleImbalance 2;
BA_ "GenSigStartValue" SG_ 2499762532 BATT_14_ModuleMIA 2;
BA_ "GenSigStartValue" SG_ 2499762532 BATT_14_SensePackVoltError 2;
BA_ "GenSigStartValue" SG_ 2499762532 BATT_14_SenseLoadVoltError 2;
BA_ "GenSigStartValue" SG_ 2499762532 BATT_14_SenseShuntError 2;
BA_ "GenSigStartValue" SG_ 2499762532 BATT_14_SenseFcVoltErrorr 2;
BA_ "GenSigStartValue" SG_ 2499762532 BATT_14_SenseBrickOpen 2;
BA_ "GenSigStartValue" SG_ 2499762532 BATT_15_vBrickOverSev 2;
BA_ "GenSigStartValue" SG_ 2499762532 BATT_15_vBrickOverMod 2;
BA_ "GenSigStartValue" SG_ 2499762532 BATT_15_vBrickOverWar 2;
BA_ "GenSigStartValue" SG_ 2499762532 BATT_15_HostQuiet 2;
BA_ "GenSigStartValue" SG_ 2499762532 BATT_15_vBrickUnderMod 2;
BA_ "GenSigStartValue" SG_ 2499762532 BATT_15_vBrickUnderWar 2;
BA_ "GenSigStartValue" SG_ 2499762532 BATT_15_TempModuleOverSev 2;
BA_ "GenSigStartValue" SG_ 2499762532 BATT_15_TempModuleOverMod 2;
BA_ "GenSigStartValue" SG_ 2499762532 BATT_15_TempModuleOverWar 2;
BA_ "GenSigStartValue" SG_ 2499762532 BATT_15_TempModuleUnderSev 2;
BA_ "GenSigStartValue" SG_ 2499762532 BATT_15_TempModuleUnderMod 2;
BA_ "GenSigStartValue" SG_ 2499762532 BATT_15_TempModuleUnderWar 2;
BA_ "GenSigStartValue" SG_ 2499762532 BATT_15_iOvercharge 2;
BA_ "GenSigStartValue" SG_ 2499762532 BATT_15_iOverdischarge 2;
BA_ "GenSigStartValue" SG_ 2499762532 BATT_15_iOverHardware 2;
BA_ "GenSigStartValue" SG_ 2499762532 BATT_15_PosDcContStuckOpen 2;
BA_ "GenSigStartValue" SG_ 2499762532 BATT_15_PosDcContWelded 2;
BA_ "GenSigStartValue" SG_ 2499762532 BATT_15_NegDcContStuckOpen 2;
BA_ "GenSigStartValue" SG_ 2499762532 BATT_15_NegDcContWelded 2;
BA_ "GenSigStartValue" SG_ 2499762532 BATT_15_PrechgTooFast 2;
BA_ "GenSigStartValue" SG_ 2499762532 BATT_15_PrechgContWelded 2;
BA_ "GenSigStartValue" SG_ 2499762532 BATT_15_PrechgTimeout 2;
BA_ "GenSigStartValue" SG_ 2499762532 BATT_15_PrechgContStuckOpen 2;
BA_ "GenSigStartValue" SG_ 2499762532 BATT_15_ModuleImbalance 2;
BA_ "GenSigStartValue" SG_ 2499762532 BATT_15_ModuleMIA 2;
BA_ "GenSigStartValue" SG_ 2499762532 BATT_15_SensePackVoltError 2;
BA_ "GenSigStartValue" SG_ 2499762532 BATT_15_SenseLoadVoltError 2;
BA_ "GenSigStartValue" SG_ 2499762532 BATT_15_SenseShuntError 2;
BA_ "GenSigStartValue" SG_ 2499762532 BATT_15_SenseFcVoltErrorr 2;
BA_ "GenSigStartValue" SG_ 2499762532 BATT_15_SenseBrickOpen 2;
BA_ "GenSigStartValue" SG_ 2499758948 BATT_vBrickOverSev 2;
BA_ "GenSigStartValue" SG_ 2499758948 BATT_vBrickOverMod 2;
BA_ "GenSigStartValue" SG_ 2499758948 BATT_vBrickOverWar 2;
BA_ "GenSigStartValue" SG_ 2499758948 BATT_HostQuiet 2;
BA_ "GenSigStartValue" SG_ 2499758948 BATT_vBrickUnderMod 2;
BA_ "GenSigStartValue" SG_ 2499758948 BATT_vBrickUnderWar 2;
BA_ "GenSigStartValue" SG_ 2499758948 BATT_TempModuleOverSev 2;
BA_ "GenSigStartValue" SG_ 2499758948 BATT_TempModuleOverMod 2;
BA_ "GenSigStartValue" SG_ 2499758948 BATT_TempModuleOverWar 2;
BA_ "GenSigStartValue" SG_ 2499758948 BATT_TempModuleUnderSev 2;
BA_ "GenSigStartValue" SG_ 2499758948 BATT_TempModuleUnderMod 2;
BA_ "GenSigStartValue" SG_ 2499758948 BATT_TempModuleUnderWar 2;
BA_ "GenSigStartValue" SG_ 2499758948 BATT_iOvercharge 2;
BA_ "GenSigStartValue" SG_ 2499758948 BATT_iOverdischarge 2;
BA_ "GenSigStartValue" SG_ 2499758948 BATT_iOverHardware 2;
BA_ "GenSigStartValue" SG_ 2499758948 BATT_PosDcContStuckOpen 2;
BA_ "GenSigStartValue" SG_ 2499758948 BATT_PosDcContWelded 2;
BA_ "GenSigStartValue" SG_ 2499758948 BATT_NegDcContStuckOpen 2;
BA_ "GenSigStartValue" SG_ 2499758948 BATT_NegDcContWelded 2;
BA_ "GenSigStartValue" SG_ 2499758948 BATT_PrechgTooFast 2;
BA_ "GenSigStartValue" SG_ 2499758948 BATT_PrechgContWelded 2;
BA_ "GenSigStartValue" SG_ 2499758948 BATT_PrechgTimeout 2;
BA_ "GenSigStartValue" SG_ 2499758948 BATT_PrechgContStuckOpen 2;
BA_ "GenSigStartValue" SG_ 2499758948 BATT_ModuleImbalance 2;
BA_ "GenSigStartValue" SG_ 2499758948 BATT_ModuleMIA 2;
BA_ "GenSigStartValue" SG_ 2499758948 BATT_SensePackVoltError 2;
BA_ "GenSigStartValue" SG_ 2499758948 BATT_SenseLoadVoltError 2;
BA_ "GenSigStartValue" SG_ 2499758948 BATT_SenseShuntError 2;
BA_ "GenSigStartValue" SG_ 2499758948 BATT_SenseFcVoltErrorr 2;
BA_ "GenSigStartValue" SG_ 2499758948 BATT_SenseBrickOpen 2;
BA_ "GenSigStartValue" SG_ 2499759204 BATT_SenseBrickImpHigh 2;
BA_ "GenSigStartValue" SG_ 2499759204 BATT_AFEfault 2;
BA_ "GenSigStartValue" SG_ 2499759204 BATT_AFEerror 2;
BA_ "GenSigStartValue" SG_ 2499759204 BATT_HostMIA 2;
BA_ "GenSigStartValue" SG_ 2499759204 BATT_TempAmbientOverSev 2;
BA_ "GenSigStartValue" SG_ 2499759204 BATT_TempAmbientOverMod 2;
BA_ "GenSigStartValue" SG_ 2499759204 BATT_TempAmbientOverWar 2;
BA_ "GenSigStartValue" SG_ 2499759204 BATT_AbnormReset 2;
BA_ "GenSigStartValue" SG_ 2499759204 BATT_SenseAuxVoltError 2;
BA_ "GenSigStartValue" SG_ 2499759204 BATT_CalibrationInvalid 2;
BA_ "GenSigStartValue" SG_ 2499759204 BATT_TaskLockup 2;
BA_ "GenSigStartValue" SG_ 2499759204 BATT_RAMover 2;
BA_ "GenSigStartValue" SG_ 2499759204 BATT_BrickOverdischarge 2;
BA_ "GenSigStartValue" SG_ 2499759204 BATT_BrickOvercharge 2;
BA_ "GenSigStartValue" SG_ 2499759204 BATT_vBrickImbalance 2;
BA_ "GenSigStartValue" SG_ 2499759204 BATT_TempBrickImbalance 2;
BA_ "GenSigStartValue" SG_ 2499759204 BATT_CapPackLow 2;
BA_ "GenSigStartValue" SG_ 2499759204 BATT_rBrickHigh 2;
BA_ "GenSigStartValue" SG_ 2499759204 BATT_PowerpackInsuffErr 2;
BA_ "GenSigStartValue" SG_ 2499759204 BATT_BrickSoftShort 2;
BA_ "GenSigStartValue" SG_ 2499759204 BATT_chargeUndercurrent 2;
BA_ "GenSigStartValue" SG_ 2499759204 BATT_HVILcurrentSourceError 2;
BA_ "GenSigStartValue" SG_ 2499759204 BATT_SRS 2;
BA_ "GenSigStartValue" SG_ 2499759204 BATT_IsolationExtWar 2;
BA_ "GenSigStartValue" SG_ 2499759204 BATT_IsolationIntWar 2;
BA_ "GenSigStartValue" SG_ 2499759204 BATT_PyroFuseBlown 2;
BA_ "GenSigStartValue" SG_ 2499759204 BATT_vBrickUnderSev 2;
BA_ "GenSigStartValue" SG_ 2499759204 BATT_chargePrechargeTimeout 2;
BA_ "GenSigStartValue" SG_ 2499759204 BATT_ModuleThermistorShort 2;
BA_ "GenSigStartValue" SG_ 2499759204 BATT_ModuleThermistorBroken 2;
BA_ "GenSigStartValue" SG_ 2499759460 BATT_HVILvoltageError 2;
BA_ "GenSigStartValue" SG_ 2499759460 BATT_HVILcurrentReturnError 2;
BA_ "GenSigStartValue" SG_ 2499759460 BATT_PosFcContWelded 2;
BA_ "GenSigStartValue" SG_ 2499759460 BATT_PosFcContStuckOpen 2;
BA_ "GenSigStartValue" SG_ 2499759460 BATT_NegFcContWelded 2;
BA_ "GenSigStartValue" SG_ 2499759460 BATT_NegFcContStuckOpen 2;
BA_ "GenSigStartValue" SG_ 2499759460 BATT_IsospiBreak 2;
BA_ "GenSigStartValue" SG_ 2499759460 BATT_IsolationIntFault 2;
BA_ "GenSigStartValue" SG_ 2499759460 BATT_IsolationExtFault 2;
BA_ "GenSigStartValue" SG_ 2499759460 BATT_event_12v_filter_error 2;
BA_ "GenSigStartValue" SG_ 2499759460 BATT_event_hall_eff_hi_rang_err 2;
BA_ "GenSigStartValue" SG_ 2499759460 BATT_event_brick_volt_sns_open 2;
BA_ "GenSigStartValue" SG_ 2499759460 BATT_event_5v_error 2;
BA_ "GenSigStartValue" SG_ 2499759460 BATT_event_3_3_hot_error 2;
BA_ "GenSigStartValue" SG_ 2499759460 BATT_event_12v_input_error 2;
BA_ "GenSigStartValue" SG_ 2499759460 BATT_event_1_25v_error 2;
BA_ "GenSigStartValue" SG_ 2499759460 BATT_event_shunt_MIA 2;
BA_ "GenSigStartValue" SG_ 2499759460 BATT_event_SBC_int_reg_error 2;
BA_ "GenSigStartValue" SG_ 2499759460 BATT_event_pos_3_3v_analog_error 2;
BA_ "GenSigStartValue" SG_ 2499759460 BATT_event_outlt_clnt_thrm_open 2;
BA_ "GenSigStartValue" SG_ 2499759460 BATT_event_neg_3_3_analog_error 2;
BA_ "GenSigStartValue" SG_ 2499759460 BATT_event_inlet_clnt_thrm_open 2;
BA_ "GenSigStartValue" SG_ 2499759460 BATT_event_hall_eff_lo_rang_err 2;
BA_ "GenSigStartValue" SG_ 2499759460 BATT_event_outlt_clnt_thrm_short 2;
BA_ "GenSigStartValue" SG_ 2499759460 BATT_event_inlet_clnt_thrm_short 2;
BA_ "GenSigStartValue" SG_ 2499759460 BATT_event_3_3v_error 2;
BA_ "SPN" SG_ 2499761508 BATT_Sys_SOHR_Module_Min_VtbId 2551;
BA_ "SPN" SG_ 2499761508 BATT_Sys_SOHR_Module_Min_V 2551;
BA_ "SPN" SG_ 2499761508 BATT_Sys_SOHR_Module_Min_StrId 2551;
BA_ "SPN" SG_ 2499761508 BATT_Sys_SOHR_Module_Min 2551;
BA_ "SPN" SG_ 2499761508 BATT_Sys_SOHR_Module_Max_VtbId 2551;
BA_ "SPN" SG_ 2499761508 BATT_Sys_SOHR_Module_Max_V 2551;
BA_ "SPN" SG_ 2499761508 BATT_Sys_SOHR_Module_Max_StrId 2551;
BA_ "SPN" SG_ 2499761508 BATT_Sys_SOHR_Module_Max 2551;
BA_ "SPN" SG_ 2499761508 BATT_Sys_SOHR_Module_Avg_V 2551;
BA_ "SPN" SG_ 2499761508 BATT_Sys_SOHR_Module_Avg 2551;
BA_ "SPN" SG_ 2499760996 BATT_Sys_SOHC_Module_Min_VtbId 2551;
BA_ "SPN" SG_ 2499760996 BATT_Sys_SOHC_Module_Min_V 2551;
BA_ "SPN" SG_ 2499760996 BATT_Sys_SOHC_Module_Min_StrId 2551;
BA_ "SPN" SG_ 2499760996 BATT_Sys_SOHC_Module_Min 2551;
BA_ "SPN" SG_ 2499760996 BATT_Sys_SOHC_Module_Max_VtbId 2551;
BA_ "SPN" SG_ 2499760996 BATT_Sys_SOHC_Module_Max_V 2551;
BA_ "SPN" SG_ 2499760996 BATT_Sys_SOHC_Module_Max_StrId 2551;
BA_ "SPN" SG_ 2499760996 BATT_Sys_SOHC_Module_Max 2551;
BA_ "SPN" SG_ 2499760996 BATT_Sys_SOHC_Module_Avg_V 2551;
BA_ "SPN" SG_ 2499760996 BATT_Sys_SOHC_Module_Avg 2551;
BA_ "SPN" SG_ 2499760740 BATT_Cnc_Volt_String_Avg_V 2551;
BA_ "SPN" SG_ 2499760740 BATT_Cnc_Volt_String_Avg 2551;
BA_ "SPN" SG_ 2499760740 BATT_Cnc_Volt_String_Min_V 2551;
BA_ "SPN" SG_ 2499760740 BATT_Cnc_Volt_String_Min_StrId 2551;
BA_ "SPN" SG_ 2499760740 BATT_Cnc_Volt_String_Min 2551;
BA_ "SPN" SG_ 2499760740 BATT_Cnc_Volt_String_Max 2551;
BA_ "SPN" SG_ 2499760740 BATT_Cnc_Volt_String_Max_V 2551;
BA_ "SPN" SG_ 2499760740 BATT_Cnc_Volt_String_Max_StrId 2551;
BA_ "SPN" SG_ 2499756388 BATT_Cnc_Temp_Module_Avg_V 2551;
BA_ "SPN" SG_ 2499756388 BATT_Cnc_Temp_Module_Avg 2551;
BA_ "SPN" SG_ 2499756388 BATT_Cnc_Temp_Module_Max 2551;
BA_ "SPN" SG_ 2499756388 BATT_Cnc_Temp_Module_Max_StrId 2551;
BA_ "GenSigStartValue" SG_ 2499756388 BATT_Cnc_Temp_Module_Max_SubId 1;
BA_ "SPN" SG_ 2499756388 BATT_Cnc_Temp_Module_Max_SubId 2551;
BA_ "SPN" SG_ 2499756388 BATT_Cnc_Temp_Module_Min 2551;
BA_ "SPN" SG_ 2499756388 BATT_Cnc_Temp_Module_Min_VtbId 2551;
BA_ "GenSigStartValue" SG_ 2499756388 BATT_Cnc_Temp_Module_Min_SubId 1;
BA_ "SPN" SG_ 2499756388 BATT_Cnc_Temp_Module_Min_SubId 2551;
BA_ "SPN" SG_ 2499756388 BATT_Cnc_Temp_Module_Max_V 2551;
BA_ "SPN" SG_ 2499756388 BATT_Cnc_Temp_Module_Min_V 2551;
BA_ "SPN" SG_ 2499756388 BATT_Cnc_Temp_Module_Max_VtbId 2551;
BA_ "SPN" SG_ 2499756388 BATT_Cnc_Temp_Module_Min_StrId 2551;
BA_ "SPN" SG_ 2499757668 BATT_Cnc_SOC_String_MinV 2551;
BA_ "SPN" SG_ 2499757668 BATT_Cnc_SOC_String_MaxV 2551;
BA_ "SPN" SG_ 2499757668 BATT_Cnc_SOC_String_AvgV 2551;
BA_ "SPN" SG_ 2499757668 BATT_Cnc_Energy_SystemV 2551;
BA_ "SPN" SG_ 2499757668 BATT_Cnc_Energy_System 2551;
BA_ "SPN" SG_ 2499757668 BATT_Cnc_SOC_String_Avg 2551;
BA_ "SPN" SG_ 2499757668 BATT_Cnc_SOC_String_Max 2551;
BA_ "SPN" SG_ 2499757668 BATT_Cnc_SOC_String_Max_StrId 2551;
BA_ "SPN" SG_ 2499757668 BATT_Cnc_SOC_String_Min 2551;
BA_ "SPN" SG_ 2499757668 BATT_Cnc_SOC_String_Min_StrId 2551;
BA_ "SPN" SG_ 2499762276 BATT_HVIL_SinkVolt_V 2551;
BA_ "SPN" SG_ 2499762276 BATT_HVIL_SourceVolt_V 2551;
BA_ "SPN" SG_ 2499762276 BATT_HVIL_SinkCrrnt 2551;
BA_ "SPN" SG_ 2499762276 BATT_HVIL_SourceVolt 2551;
BA_ "SPN" SG_ 2499762276 BATT_HVIL_SinkVolt 2551;
BA_ "SPN" SG_ 2499761764 BATT_Cnc_Volt_Cell_Avg_V 2551;
BA_ "SPN" SG_ 2499761764 BATT_Cnc_Volt_Cell_Avg 2551;
BA_ "SPN" SG_ 2499761764 BATT_Cnc_Volt_Cell_Max_VtbId 2551;
BA_ "SPN" SG_ 2499761764 BATT_Cnc_Volt_Cell_Max_V 2551;
BA_ "SPN" SG_ 2499761764 BATT_Cnc_Volt_Cell_Max_StrId 2551;
BA_ "SPN" SG_ 2499761764 BATT_Cnc_Volt_Cell_Max_CellId 2551;
BA_ "SPN" SG_ 2499761764 BATT_Cnc_Volt_Cell_Max 2551;
BA_ "SPN" SG_ 2499761764 BATT_Cnc_Volt_Cell_Min_V 2551;
BA_ "SPN" SG_ 2499761764 BATT_Cnc_Volt_Cell_Min 2551;
BA_ "SPN" SG_ 2499761764 BATT_Cnc_Volt_Cell_Min_VtbId 2551;
BA_ "SPN" SG_ 2499761764 BATT_Cnc_Volt_Cell_Min_StrId 2551;
BA_ "SPN" SG_ 2499761764 BATT_Cnc_Volt_Cell_Min_CellId 2551;
BA_ "SPN" SG_ 2499760484 BATT_IsoRes_Min_StrId 2551;
BA_ "SPN" SG_ 2499760484 BATT_IsoRes_Min 2551;
BA_ "SPN" SG_ 2499760484 BATT_IsoRes_Max_StrId 2551;
BA_ "SPN" SG_ 2499760484 BATT_IsoRes_Max 2551;
BA_ "SPN" SG_ 2499760484 BATT_IsoRes_Last 2551;
BA_ "SPN" SG_ 2499760228 BATT_State_Chrgr 2551;
BA_ "SPN" SG_ 2499760228 BATT_State_ChrgrIntrlck 2551;
BA_ "SPN" SG_ 2499760228 BATT_Limit_ChrgrVolt 2551;
BA_ "SPN" SG_ 2499760228 BATT_Limit_ChrgrCrrnt 2551;
BA_ "GenSigStartValue" SG_ 2499756105 APP_StringConnectRequest 1;
BA_ "SPN" SG_ 2499756105 APP_State_ReqMode 2551;
BA_ "SPN" SG_ 2499756105 APP_Contactor_Command 2551;
BA_ "SPN" SG_ 2499756105 APP_Balancing_Enable_F 2551;
BA_ "SPN" SG_ 2499756105 APP_Comm_RollingCount 2551;
BA_ "SPN" SG_ 2499756105 APP_IsoRes_Enable_F 2551;
BA_ "SPN" SG_ 2499756132 BATT_Comm_StringsAddressed 2551;
BA_ "SPN" SG_ 2499756132 BATT_Contactor_EmergencyOpen_F 2551;
BA_ "SPN" SG_ 2499756132 BATT_Balancing_Status 2551;
BA_ "SPN" SG_ 2499756132 BATT_State_SysPwrMd 2551;
BA_ "SPN" SG_ 2499756132 BATT_Contactor_StringsConnected 2551;
BA_ "SPN" SG_ 2499756132 BATT_Comm_RollingCount 2551;
BA_ "SPN" SG_ 2499756132 BATT_IsoRes_Source 2551;
BA_ "SPN" SG_ 2499756644 BATT_Current_String_Min_V 2551;
BA_ "SPN" SG_ 2499756644 BATT_Current_String_Min_StrId 2551;
BA_ "SPN" SG_ 2499756644 BATT_Current_String_Min 2551;
BA_ "SPN" SG_ 2499756644 BATT_Current_String_Max_V 2551;
BA_ "SPN" SG_ 2499756644 BATT_Current_String_Max_StrId 2551;
BA_ "SPN" SG_ 2499756644 BATT_Current_String_Max 2551;
BA_ "SPN" SG_ 2499756644 BATT_Current_System 2551;
BA_ "SPN" SG_ 2499756644 BATT_Current_System_V 2551;
BA_ "SPN" SG_ 2499756900 BATT_Sys_Volt_String_Avg 2551;
BA_ "SPN" SG_ 2499756900 BATT_Sys_Volt_String_Min_StrId 2551;
BA_ "SPN" SG_ 2499756900 BATT_Sys_Volt_String_Min 2551;
BA_ "SPN" SG_ 2499756900 BATT_Sys_Volt_String_Max 2551;
BA_ "SPN" SG_ 2499756900 BATT_Sys_Volt_String_Max_StrId 2551;
BA_ "SPN" SG_ 2499757156 BATT_Sys_Volt_Cell_Avg 2551;
BA_ "SPN" SG_ 2499757156 BATT_Sys_Volt_Cell_Max_VtbId 2551;
BA_ "SPN" SG_ 2499757156 BATT_Sys_Volt_Cell_Max_V 2551;
BA_ "SPN" SG_ 2499757156 BATT_Sys_Volt_Cell_Max_StrId 2551;
BA_ "SPN" SG_ 2499757156 BATT_Sys_Volt_Cell_Max_CellId 2551;
BA_ "SPN" SG_ 2499757156 BATT_Sys_Volt_Cell_Max 2551;
BA_ "SPN" SG_ 2499757156 BATT_Sys_Volt_Cell_Min_V 2551;
BA_ "SPN" SG_ 2499757156 BATT_Sys_Volt_Cell_Min 2551;
BA_ "SPN" SG_ 2499757156 BATT_Sys_Volt_Cell_Min_VtbId 2551;
BA_ "SPN" SG_ 2499757156 BATT_Sys_Volt_Cell_Min_StrId 2551;
BA_ "SPN" SG_ 2499757156 BATT_Sys_Volt_Cell_Min_CellId 2551;
BA_ "SPN" SG_ 2499757412 BATT_Sys_SOC_String_Min_V 2551;
BA_ "SPN" SG_ 2499757412 BATT_Sys_SOC_String_Max_V 2551;
BA_ "SPN" SG_ 2499757412 BATT_Sys_SOC_String_Avg_V 2551;
BA_ "SPN" SG_ 2499757412 BATT_Sys_Energy_System_V 2551;
BA_ "SPN" SG_ 2499757412 BATT_Sys_Energy_System 2551;
BA_ "SPN" SG_ 2499757412 BATT_Sys_SOC_String_Avg 2551;
BA_ "SPN" SG_ 2499757412 BATT_Sys_SOC_String_Max 2551;
BA_ "SPN" SG_ 2499757412 BATT_Sys_SOC_String_Max_StrId 2551;
BA_ "SPN" SG_ 2499757412 BATT_Sys_SOC_String_Min 2551;
BA_ "SPN" SG_ 2499757412 BATT_Sys_SOC_String_Min_StrId 2551;
BA_ "SPN" SG_ 2499757924 BATT_Sys_Temp_Module_Avg 2551;
BA_ "SPN" SG_ 2499757924 BATT_Sys_Temp_Module_Max 2551;
BA_ "SPN" SG_ 2499757924 BATT_Sys_Temp_Module_Max_StrId 2551;
BA_ "GenSigStartValue" SG_ 2499757924 BATT_Sys_Temp_Module_Max_SubId 1;
BA_ "SPN" SG_ 2499757924 BATT_Sys_Temp_Module_Max_SubId 2551;
BA_ "SPN" SG_ 2499757924 BATT_Sys_Temp_Module_Min 2551;
BA_ "SPN" SG_ 2499757924 BATT_Sys_Temp_Module_Min_VtbId 2551;
BA_ "GenSigStartValue" SG_ 2499757924 BATT_Sys_Temp_Module_Min_SubId 1;
BA_ "SPN" SG_ 2499757924 BATT_Sys_Temp_Module_Min_SubId 2551;
BA_ "SPN" SG_ 2499757924 BATT_Sys_Temp_Module_Max_VtbId 2551;
BA_ "SPN" SG_ 2499757924 BATT_Sys_Temp_Module_Min_StrId 2551;
BA_ "SPN" SG_ 2499758180 BATT_Limit_DschrgCrrnt 2551;
BA_ "SPN" SG_ 2499758180 BATT_Limit_DschrgPwr_LongTerm 2551;
BA_ "SPN" SG_ 2499758180 BATT_Limit_DschrgPwr_ShortTerm 2551;
BA_ "SPN" SG_ 2499758180 BATT_Limit_DschrgPwr_MidTerm 2551;
BA_ "SPN" SG_ 2499758436 BATT_Limit_RegenPwr_LongTerm 2551;
BA_ "SPN" SG_ 2499758436 BATT_Limit_RegenPwr_MidTerm 2551;
BA_ "SPN" SG_ 2499758436 BATT_Limit_RegenPwr_ShortTerm 2551;
BA_ "SPN" SG_ 2499758436 BATT_Limit_RegenCrrnt 2551;
VAL_ 2499762532 BATT_01_vBrickOverSev 3 "Error" 2 "SNA" 1 "Active" 0 "Inactive" ;
VAL_ 2499762532 BATT_01_vBrickOverMod 3 "Error" 2 "SNA" 1 "Active" 0 "Inactive" ;
VAL_ 2499762532 BATT_01_vBrickOverWar 3 "Error" 2 "SNA" 1 "Active" 0 "Inactive" ;
VAL_ 2499762532 BATT_01_HostQuiet 3 "Error" 2 "SNA" 1 "Active" 0 "Inactive" ;
VAL_ 2499762532 BATT_01_vBrickUnderMod 3 "Error" 2 "SNA" 1 "Active" 0 "Inactive" ;
VAL_ 2499762532 BATT_01_vBrickUnderWar 3 "Error" 2 "SNA" 1 "Active" 0 "Inactive" ;
VAL_ 2499762532 BATT_01_TempModuleOverSev 3 "Error" 2 "SNA" 1 "Active" 0 "Inactive" ;
VAL_ 2499762532 BATT_01_TempModuleOverMod 3 "Error" 2 "SNA" 1 "Active" 0 "Inactive" ;
VAL_ 2499762532 BATT_01_TempModuleOverWar 3 "Error" 2 "SNA" 1 "Active" 0 "Inactive" ;
VAL_ 2499762532 BATT_01_TempModuleUnderSev 3 "Error" 2 "SNA" 1 "Active" 0 "Inactive" ;
VAL_ 2499762532 BATT_01_TempModuleUnderMod 3 "Error" 2 "SNA" 1 "Active" 0 "Inactive" ;
VAL_ 2499762532 BATT_01_TempModuleUnderWar 3 "Error" 2 "SNA" 1 "Active" 0 "Inactive" ;
VAL_ 2499762532 BATT_01_iOvercharge 3 "Error" 2 "SNA" 1 "Active" 0 "Inactive" ;
VAL_ 2499762532 BATT_01_iOverdischarge 3 "Error" 2 "SNA" 1 "Active" 0 "Inactive" ;
VAL_ 2499762532 BATT_01_iOverHardware 3 "Error" 2 "SNA" 1 "Active" 0 "Inactive" ;
VAL_ 2499762532 BATT_01_PosDcContStuckOpen 3 "Error" 2 "SNA" 1 "Active" 0 "Inactive" ;
VAL_ 2499762532 BATT_01_PosDcContWelded 3 "Error" 2 "SNA" 1 "Active" 0 "Inactive" ;
VAL_ 2499762532 BATT_01_NegDcContStuckOpen 3 "Error" 2 "SNA" 1 "Active" 0 "Inactive" ;
VAL_ 2499762532 BATT_01_NegDcContWelded 3 "Error" 2 "SNA" 1 "Active" 0 "Inactive" ;
VAL_ 2499762532 BATT_01_PrechgTooFast 3 "Error" 2 "SNA" 1 "Active" 0 "Inactive" ;
VAL_ 2499762532 BATT_01_PrechgContWelded 3 "Error" 2 "SNA" 1 "Active" 0 "Inactive" ;
VAL_ 2499762532 BATT_01_PrechgTimeout 3 "Error" 2 "SNA" 1 "Active" 0 "Inactive" ;
VAL_ 2499762532 BATT_01_PrechgContStuckOpen 3 "Error" 2 "SNA" 1 "Active" 0 "Inactive" ;
VAL_ 2499762532 BATT_01_ModuleImbalance 3 "Error" 2 "SNA" 1 "Active" 0 "Inactive" ;
VAL_ 2499762532 BATT_01_ModuleMIA 3 "Error" 2 "SNA" 1 "Active" 0 "Inactive" ;
VAL_ 2499762532 BATT_01_SensePackVoltError 3 "Error" 2 "SNA" 1 "Active" 0 "Inactive" ;
VAL_ 2499762532 BATT_01_SenseLoadVoltError 3 "Error" 2 "SNA" 1 "Active" 0 "Inactive" ;
VAL_ 2499762532 BATT_01_SenseShuntError 3 "Error" 2 "SNA" 1 "Active" 0 "Inactive" ;
VAL_ 2499762532 BATT_01_SenseFcVoltErrorr 3 "Error" 2 "SNA" 1 "Active" 0 "Inactive" ;
VAL_ 2499762532 BATT_01_SenseBrickOpen 3 "Error" 2 "SNA" 1 "Active" 0 "Inactive" ;
VAL_ 2499762532 BATT_02_vBrickOverSev 3 "Error" 2 "SNA" 1 "Active" 0 "Inactive" ;
VAL_ 2499762532 BATT_02_vBrickOverMod 3 "Error" 2 "SNA" 1 "Active" 0 "Inactive" ;
VAL_ 2499762532 BATT_02_vBrickOverWar 3 "Error" 2 "SNA" 1 "Active" 0 "Inactive" ;
VAL_ 2499762532 BATT_02_HostQuiet 3 "Error" 2 "SNA" 1 "Active" 0 "Inactive" ;
VAL_ 2499762532 BATT_02_vBrickUnderMod 3 "Error" 2 "SNA" 1 "Active" 0 "Inactive" ;
VAL_ 2499762532 BATT_02_vBrickUnderWar 3 "Error" 2 "SNA" 1 "Active" 0 "Inactive" ;
VAL_ 2499762532 BATT_02_TempModuleOverSev 3 "Error" 2 "SNA" 1 "Active" 0 "Inactive" ;
VAL_ 2499762532 BATT_02_TempModuleOverMod 3 "Error" 2 "SNA" 1 "Active" 0 "Inactive" ;
VAL_ 2499762532 BATT_02_TempModuleOverWar 3 "Error" 2 "SNA" 1 "Active" 0 "Inactive" ;
VAL_ 2499762532 BATT_02_TempModuleUnderSev 3 "Error" 2 "SNA" 1 "Active" 0 "Inactive" ;
VAL_ 2499762532 BATT_02_TempModuleUnderMod 3 "Error" 2 "SNA" 1 "Active" 0 "Inactive" ;
VAL_ 2499762532 BATT_02_TempModuleUnderWar 3 "Error" 2 "SNA" 1 "Active" 0 "Inactive" ;
VAL_ 2499762532 BATT_02_iOvercharge 3 "Error" 2 "SNA" 1 "Active" 0 "Inactive" ;
VAL_ 2499762532 BATT_02_iOverdischarge 3 "Error" 2 "SNA" 1 "Active" 0 "Inactive" ;
VAL_ 2499762532 BATT_02_iOverHardware 3 "Error" 2 "SNA" 1 "Active" 0 "Inactive" ;
VAL_ 2499762532 BATT_02_PosDcContStuckOpen 3 "Error" 2 "SNA" 1 "Active" 0 "Inactive" ;
VAL_ 2499762532 BATT_02_PosDcContWelded 3 "Error" 2 "SNA" 1 "Active" 0 "Inactive" ;
VAL_ 2499762532 BATT_02_NegDcContStuckOpen 3 "Error" 2 "SNA" 1 "Active" 0 "Inactive" ;
VAL_ 2499762532 BATT_02_NegDcContWelded 3 "Error" 2 "SNA" 1 "Active" 0 "Inactive" ;
VAL_ 2499762532 BATT_02_PrechgTooFast 3 "Error" 2 "SNA" 1 "Active" 0 "Inactive" ;
VAL_ 2499762532 BATT_02_PrechgContWelded 3 "Error" 2 "SNA" 1 "Active" 0 "Inactive" ;
VAL_ 2499762532 BATT_02_PrechgTimeout 3 "Error" 2 "SNA" 1 "Active" 0 "Inactive" ;
VAL_ 2499762532 BATT_02_PrechgContStuckOpen 3 "Error" 2 "SNA" 1 "Active" 0 "Inactive" ;
VAL_ 2499762532 BATT_02_ModuleImbalance 3 "Error" 2 "SNA" 1 "Active" 0 "Inactive" ;
VAL_ 2499762532 BATT_02_ModuleMIA 3 "Error" 2 "SNA" 1 "Active" 0 "Inactive" ;
VAL_ 2499762532 BATT_02_SensePackVoltError 3 "Error" 2 "SNA" 1 "Active" 0 "Inactive" ;
VAL_ 2499762532 BATT_02_SenseLoadVoltError 3 "Error" 2 "SNA" 1 "Active" 0 "Inactive" ;
VAL_ 2499762532 BATT_02_SenseShuntError 3 "Error" 2 "SNA" 1 "Active" 0 "Inactive" ;
VAL_ 2499762532 BATT_02_SenseFcVoltErrorr 3 "Error" 2 "SNA" 1 "Active" 0 "Inactive" ;
VAL_ 2499762532 BATT_02_SenseBrickOpen 3 "Error" 2 "SNA" 1 "Active" 0 "Inactive" ;
VAL_ 2499762532 BATT_03_vBrickOverSev 3 "Error" 2 "SNA" 1 "Active" 0 "Inactive" ;
VAL_ 2499762532 BATT_03_vBrickOverMod 3 "Error" 2 "SNA" 1 "Active" 0 "Inactive" ;
VAL_ 2499762532 BATT_03_vBrickOverWar 3 "Error" 2 "SNA" 1 "Active" 0 "Inactive" ;
VAL_ 2499762532 BATT_03_HostQuiet 3 "Error" 2 "SNA" 1 "Active" 0 "Inactive" ;
VAL_ 2499762532 BATT_03_vBrickUnderMod 3 "Error" 2 "SNA" 1 "Active" 0 "Inactive" ;
VAL_ 2499762532 BATT_03_vBrickUnderWar 3 "Error" 2 "SNA" 1 "Active" 0 "Inactive" ;
VAL_ 2499762532 BATT_03_TempModuleOverSev 3 "Error" 2 "SNA" 1 "Active" 0 "Inactive" ;
VAL_ 2499762532 BATT_03_TempModuleOverMod 3 "Error" 2 "SNA" 1 "Active" 0 "Inactive" ;
VAL_ 2499762532 BATT_03_TempModuleOverWar 3 "Error" 2 "SNA" 1 "Active" 0 "Inactive" ;
VAL_ 2499762532 BATT_03_TempModuleUnderSev 3 "Error" 2 "SNA" 1 "Active" 0 "Inactive" ;
VAL_ 2499762532 BATT_03_TempModuleUnderMod 3 "Error" 2 "SNA" 1 "Active" 0 "Inactive" ;
VAL_ 2499762532 BATT_03_TempModuleUnderWar 3 "Error" 2 "SNA" 1 "Active" 0 "Inactive" ;
VAL_ 2499762532 BATT_03_iOvercharge 3 "Error" 2 "SNA" 1 "Active" 0 "Inactive" ;
VAL_ 2499762532 BATT_03_iOverdischarge 3 "Error" 2 "SNA" 1 "Active" 0 "Inactive" ;
VAL_ 2499762532 BATT_03_iOverHardware 3 "Error" 2 "SNA" 1 "Active" 0 "Inactive" ;
VAL_ 2499762532 BATT_03_PosDcContStuckOpen 3 "Error" 2 "SNA" 1 "Active" 0 "Inactive" ;
VAL_ 2499762532 BATT_03_PosDcContWelded 3 "Error" 2 "SNA" 1 "Active" 0 "Inactive" ;
VAL_ 2499762532 BATT_03_NegDcContStuckOpen 3 "Error" 2 "SNA" 1 "Active" 0 "Inactive" ;
VAL_ 2499762532 BATT_03_NegDcContWelded 3 "Error" 2 "SNA" 1 "Active" 0 "Inactive" ;
VAL_ 2499762532 BATT_03_PrechgTooFast 3 "Error" 2 "SNA" 1 "Active" 0 "Inactive" ;
VAL_ 2499762532 BATT_03_PrechgContWelded 3 "Error" 2 "SNA" 1 "Active" 0 "Inactive" ;
VAL_ 2499762532 BATT_03_PrechgTimeout 3 "Error" 2 "SNA" 1 "Active" 0 "Inactive" ;
VAL_ 2499762532 BATT_03_PrechgContStuckOpen 3 "Error" 2 "SNA" 1 "Active" 0 "Inactive" ;
VAL_ 2499762532 BATT_03_ModuleImbalance 3 "Error" 2 "SNA" 1 "Active" 0 "Inactive" ;
VAL_ 2499762532 BATT_03_ModuleMIA 3 "Error" 2 "SNA" 1 "Active" 0 "Inactive" ;
VAL_ 2499762532 BATT_03_SensePackVoltError 3 "Error" 2 "SNA" 1 "Active" 0 "Inactive" ;
VAL_ 2499762532 BATT_03_SenseLoadVoltError 3 "Error" 2 "SNA" 1 "Active" 0 "Inactive" ;
VAL_ 2499762532 BATT_03_SenseShuntError 3 "Error" 2 "SNA" 1 "Active" 0 "Inactive" ;
VAL_ 2499762532 BATT_03_SenseFcVoltErrorr 3 "Error" 2 "SNA" 1 "Active" 0 "Inactive" ;
VAL_ 2499762532 BATT_03_SenseBrickOpen 3 "Error" 2 "SNA" 1 "Active" 0 "Inactive" ;
VAL_ 2499762532 BATT_04_vBrickOverSev 3 "Error" 2 "SNA" 1 "Active" 0 "Inactive" ;
VAL_ 2499762532 BATT_04_vBrickOverMod 3 "Error" 2 "SNA" 1 "Active" 0 "Inactive" ;
VAL_ 2499762532 BATT_04_vBrickOverWar 3 "Error" 2 "SNA" 1 "Active" 0 "Inactive" ;
VAL_ 2499762532 BATT_04_HostQuiet 3 "Error" 2 "SNA" 1 "Active" 0 "Inactive" ;
VAL_ 2499762532 BATT_04_vBrickUnderMod 3 "Error" 2 "SNA" 1 "Active" 0 "Inactive" ;
VAL_ 2499762532 BATT_04_vBrickUnderWar 3 "Error" 2 "SNA" 1 "Active" 0 "Inactive" ;
VAL_ 2499762532 BATT_04_TempModuleOverSev 3 "Error" 2 "SNA" 1 "Active" 0 "Inactive" ;
VAL_ 2499762532 BATT_04_TempModuleOverMod 3 "Error" 2 "SNA" 1 "Active" 0 "Inactive" ;
VAL_ 2499762532 BATT_04_TempModuleOverWar 3 "Error" 2 "SNA" 1 "Active" 0 "Inactive" ;
VAL_ 2499762532 BATT_04_TempModuleUnderSev 3 "Error" 2 "SNA" 1 "Active" 0 "Inactive" ;
VAL_ 2499762532 BATT_04_TempModuleUnderMod 3 "Error" 2 "SNA" 1 "Active" 0 "Inactive" ;
VAL_ 2499762532 BATT_04_TempModuleUnderWar 3 "Error" 2 "SNA" 1 "Active" 0 "Inactive" ;
VAL_ 2499762532 BATT_04_iOvercharge 3 "Error" 2 "SNA" 1 "Active" 0 "Inactive" ;
VAL_ 2499762532 BATT_04_iOverdischarge 3 "Error" 2 "SNA" 1 "Active" 0 "Inactive" ;
VAL_ 2499762532 BATT_04_iOverHardware 3 "Error" 2 "SNA" 1 "Active" 0 "Inactive" ;
VAL_ 2499762532 BATT_04_PosDcContStuckOpen 3 "Error" 2 "SNA" 1 "Active" 0 "Inactive" ;
VAL_ 2499762532 BATT_04_PosDcContWelded 3 "Error" 2 "SNA" 1 "Active" 0 "Inactive" ;
VAL_ 2499762532 BATT_04_NegDcContStuckOpen 3 "Error" 2 "SNA" 1 "Active" 0 "Inactive" ;
VAL_ 2499762532 BATT_04_NegDcContWelded 3 "Error" 2 "SNA" 1 "Active" 0 "Inactive" ;
VAL_ 2499762532 BATT_04_PrechgTooFast 3 "Error" 2 "SNA" 1 "Active" 0 "Inactive" ;
VAL_ 2499762532 BATT_04_PrechgContWelded 3 "Error" 2 "SNA" 1 "Active" 0 "Inactive" ;
VAL_ 2499762532 BATT_04_PrechgTimeout 3 "Error" 2 "SNA" 1 "Active" 0 "Inactive" ;
VAL_ 2499762532 BATT_04_PrechgContStuckOpen 3 "Error" 2 "SNA" 1 "Active" 0 "Inactive" ;
VAL_ 2499762532 BATT_04_ModuleImbalance 3 "Error" 2 "SNA" 1 "Active" 0 "Inactive" ;
VAL_ 2499762532 BATT_04_ModuleMIA 3 "Error" 2 "SNA" 1 "Active" 0 "Inactive" ;
VAL_ 2499762532 BATT_04_SensePackVoltError 3 "Error" 2 "SNA" 1 "Active" 0 "Inactive" ;
VAL_ 2499762532 BATT_04_SenseLoadVoltError 3 "Error" 2 "SNA" 1 "Active" 0 "Inactive" ;
VAL_ 2499762532 BATT_04_SenseShuntError 3 "Error" 2 "SNA" 1 "Active" 0 "Inactive" ;
VAL_ 2499762532 BATT_04_SenseFcVoltErrorr 3 "Error" 2 "SNA" 1 "Active" 0 "Inactive" ;
VAL_ 2499762532 BATT_04_SenseBrickOpen 3 "Error" 2 "SNA" 1 "Active" 0 "Inactive" ;
VAL_ 2499762532 BATT_05_vBrickOverSev 3 "Error" 2 "SNA" 1 "Active" 0 "Inactive" ;
VAL_ 2499762532 BATT_05_vBrickOverMod 3 "Error" 2 "SNA" 1 "Active" 0 "Inactive" ;
VAL_ 2499762532 BATT_05_vBrickOverWar 3 "Error" 2 "SNA" 1 "Active" 0 "Inactive" ;
VAL_ 2499762532 BATT_05_HostQuiet 3 "Error" 2 "SNA" 1 "Active" 0 "Inactive" ;
VAL_ 2499762532 BATT_05_vBrickUnderMod 3 "Error" 2 "SNA" 1 "Active" 0 "Inactive" ;
VAL_ 2499762532 BATT_05_vBrickUnderWar 3 "Error" 2 "SNA" 1 "Active" 0 "Inactive" ;
VAL_ 2499762532 BATT_05_TempModuleOverSev 3 "Error" 2 "SNA" 1 "Active" 0 "Inactive" ;
VAL_ 2499762532 BATT_05_TempModuleOverMod 3 "Error" 2 "SNA" 1 "Active" 0 "Inactive" ;
VAL_ 2499762532 BATT_05_TempModuleOverWar 3 "Error" 2 "SNA" 1 "Active" 0 "Inactive" ;
VAL_ 2499762532 BATT_05_TempModuleUnderSev 3 "Error" 2 "SNA" 1 "Active" 0 "Inactive" ;
VAL_ 2499762532 BATT_05_TempModuleUnderMod 3 "Error" 2 "SNA" 1 "Active" 0 "Inactive" ;
VAL_ 2499762532 BATT_05_TempModuleUnderWar 3 "Error" 2 "SNA" 1 "Active" 0 "Inactive" ;
VAL_ 2499762532 BATT_05_iOvercharge 3 "Error" 2 "SNA" 1 "Active" 0 "Inactive" ;
VAL_ 2499762532 BATT_05_iOverdischarge 3 "Error" 2 "SNA" 1 "Active" 0 "Inactive" ;
VAL_ 2499762532 BATT_05_iOverHardware 3 "Error" 2 "SNA" 1 "Active" 0 "Inactive" ;
VAL_ 2499762532 BATT_05_PosDcContStuckOpen 3 "Error" 2 "SNA" 1 "Active" 0 "Inactive" ;
VAL_ 2499762532 BATT_05_PosDcContWelded 3 "Error" 2 "SNA" 1 "Active" 0 "Inactive" ;
VAL_ 2499762532 BATT_05_NegDcContStuckOpen 3 "Error" 2 "SNA" 1 "Active" 0 "Inactive" ;
VAL_ 2499762532 BATT_05_NegDcContWelded 3 "Error" 2 "SNA" 1 "Active" 0 "Inactive" ;
VAL_ 2499762532 BATT_05_PrechgTooFast 3 "Error" 2 "SNA" 1 "Active" 0 "Inactive" ;
VAL_ 2499762532 BATT_05_PrechgContWelded 3 "Error" 2 "SNA" 1 "Active" 0 "Inactive" ;
VAL_ 2499762532 BATT_05_PrechgTimeout 3 "Error" 2 "SNA" 1 "Active" 0 "Inactive" ;
VAL_ 2499762532 BATT_05_PrechgContStuckOpen 3 "Error" 2 "SNA" 1 "Active" 0 "Inactive" ;
VAL_ 2499762532 BATT_05_ModuleImbalance 3 "Error" 2 "SNA" 1 "Active" 0 "Inactive" ;
VAL_ 2499762532 BATT_05_ModuleMIA 3 "Error" 2 "SNA" 1 "Active" 0 "Inactive" ;
VAL_ 2499762532 BATT_05_SensePackVoltError 3 "Error" 2 "SNA" 1 "Active" 0 "Inactive" ;
VAL_ 2499762532 BATT_05_SenseLoadVoltError 3 "Error" 2 "SNA" 1 "Active" 0 "Inactive" ;
VAL_ 2499762532 BATT_05_SenseShuntError 3 "Error" 2 "SNA" 1 "Active" 0 "Inactive" ;
VAL_ 2499762532 BATT_05_SenseFcVoltErrorr 3 "Error" 2 "SNA" 1 "Active" 0 "Inactive" ;
VAL_ 2499762532 BATT_05_SenseBrickOpen 3 "Error" 2 "SNA" 1 "Active" 0 "Inactive" ;
VAL_ 2499762532 BATT_06_vBrickOverSev 3 "Error" 2 "SNA" 1 "Active" 0 "Inactive" ;
VAL_ 2499762532 BATT_06_vBrickOverMod 3 "Error" 2 "SNA" 1 "Active" 0 "Inactive" ;
VAL_ 2499762532 BATT_06_vBrickOverWar 3 "Error" 2 "SNA" 1 "Active" 0 "Inactive" ;
VAL_ 2499762532 BATT_06_HostQuiet 3 "Error" 2 "SNA" 1 "Active" 0 "Inactive" ;
VAL_ 2499762532 BATT_06_vBrickUnderMod 3 "Error" 2 "SNA" 1 "Active" 0 "Inactive" ;
VAL_ 2499762532 BATT_06_vBrickUnderWar 3 "Error" 2 "SNA" 1 "Active" 0 "Inactive" ;
VAL_ 2499762532 BATT_06_TempModuleOverSev 3 "Error" 2 "SNA" 1 "Active" 0 "Inactive" ;
VAL_ 2499762532 BATT_06_TempModuleOverMod 3 "Error" 2 "SNA" 1 "Active" 0 "Inactive" ;
VAL_ 2499762532 BATT_06_TempModuleOverWar 3 "Error" 2 "SNA" 1 "Active" 0 "Inactive" ;
VAL_ 2499762532 BATT_06_TempModuleUnderSev 3 "Error" 2 "SNA" 1 "Active" 0 "Inactive" ;
VAL_ 2499762532 BATT_06_TempModuleUnderMod 3 "Error" 2 "SNA" 1 "Active" 0 "Inactive" ;
VAL_ 2499762532 BATT_06_TempModuleUnderWar 3 "Error" 2 "SNA" 1 "Active" 0 "Inactive" ;
VAL_ 2499762532 BATT_06_iOvercharge 3 "Error" 2 "SNA" 1 "Active" 0 "Inactive" ;
VAL_ 2499762532 BATT_06_iOverdischarge 3 "Error" 2 "SNA" 1 "Active" 0 "Inactive" ;
VAL_ 2499762532 BATT_06_iOverHardware 3 "Error" 2 "SNA" 1 "Active" 0 "Inactive" ;
VAL_ 2499762532 BATT_06_PosDcContStuckOpen 3 "Error" 2 "SNA" 1 "Active" 0 "Inactive" ;
VAL_ 2499762532 BATT_06_PosDcContWelded 3 "Error" 2 "SNA" 1 "Active" 0 "Inactive" ;
VAL_ 2499762532 BATT_06_NegDcContStuckOpen 3 "Error" 2 "SNA" 1 "Active" 0 "Inactive" ;
VAL_ 2499762532 BATT_06_NegDcContWelded 3 "Error" 2 "SNA" 1 "Active" 0 "Inactive" ;
VAL_ 2499762532 BATT_06_PrechgTooFast 3 "Error" 2 "SNA" 1 "Active" 0 "Inactive" ;
VAL_ 2499762532 BATT_06_PrechgContWelded 3 "Error" 2 "SNA" 1 "Active" 0 "Inactive" ;
VAL_ 2499762532 BATT_06_PrechgTimeout 3 "Error" 2 "SNA" 1 "Active" 0 "Inactive" ;
VAL_ 2499762532 BATT_06_PrechgContStuckOpen 3 "Error" 2 "SNA" 1 "Active" 0 "Inactive" ;
VAL_ 2499762532 BATT_06_ModuleImbalance 3 "Error" 2 "SNA" 1 "Active" 0 "Inactive" ;
VAL_ 2499762532 BATT_06_ModuleMIA 3 "Error" 2 "SNA" 1 "Active" 0 "Inactive" ;
VAL_ 2499762532 BATT_06_SensePackVoltError 3 "Error" 2 "SNA" 1 "Active" 0 "Inactive" ;
VAL_ 2499762532 BATT_06_SenseLoadVoltError 3 "Error" 2 "SNA" 1 "Active" 0 "Inactive" ;
VAL_ 2499762532 BATT_06_SenseShuntError 3 "Error" 2 "SNA" 1 "Active" 0 "Inactive" ;
VAL_ 2499762532 BATT_06_SenseFcVoltErrorr 3 "Error" 2 "SNA" 1 "Active" 0 "Inactive" ;
VAL_ 2499762532 BATT_06_SenseBrickOpen 3 "Error" 2 "SNA" 1 "Active" 0 "Inactive" ;
VAL_ 2499762532 BATT_07_vBrickOverSev 3 "Error" 2 "SNA" 1 "Active" 0 "Inactive" ;
VAL_ 2499762532 BATT_07_vBrickOverMod 3 "Error" 2 "SNA" 1 "Active" 0 "Inactive" ;
VAL_ 2499762532 BATT_07_vBrickOverWar 3 "Error" 2 "SNA" 1 "Active" 0 "Inactive" ;
VAL_ 2499762532 BATT_07_HostQuiet 3 "Error" 2 "SNA" 1 "Active" 0 "Inactive" ;
VAL_ 2499762532 BATT_07_vBrickUnderMod 3 "Error" 2 "SNA" 1 "Active" 0 "Inactive" ;
VAL_ 2499762532 BATT_07_vBrickUnderWar 3 "Error" 2 "SNA" 1 "Active" 0 "Inactive" ;
VAL_ 2499762532 BATT_07_TempModuleOverSev 3 "Error" 2 "SNA" 1 "Active" 0 "Inactive" ;
VAL_ 2499762532 BATT_07_TempModuleOverMod 3 "Error" 2 "SNA" 1 "Active" 0 "Inactive" ;
VAL_ 2499762532 BATT_07_TempModuleOverWar 3 "Error" 2 "SNA" 1 "Active" 0 "Inactive" ;
VAL_ 2499762532 BATT_07_TempModuleUnderSev 3 "Error" 2 "SNA" 1 "Active" 0 "Inactive" ;
VAL_ 2499762532 BATT_07_TempModuleUnderMod 3 "Error" 2 "SNA" 1 "Active" 0 "Inactive" ;
VAL_ 2499762532 BATT_07_TempModuleUnderWar 3 "Error" 2 "SNA" 1 "Active" 0 "Inactive" ;
VAL_ 2499762532 BATT_07_iOvercharge 3 "Error" 2 "SNA" 1 "Active" 0 "Inactive" ;
VAL_ 2499762532 BATT_07_iOverdischarge 3 "Error" 2 "SNA" 1 "Active" 0 "Inactive" ;
VAL_ 2499762532 BATT_07_iOverHardware 3 "Error" 2 "SNA" 1 "Active" 0 "Inactive" ;
VAL_ 2499762532 BATT_07_PosDcContStuckOpen 3 "Error" 2 "SNA" 1 "Active" 0 "Inactive" ;
VAL_ 2499762532 BATT_07_PosDcContWelded 3 "Error" 2 "SNA" 1 "Active" 0 "Inactive" ;
VAL_ 2499762532 BATT_07_NegDcContStuckOpen 3 "Error" 2 "SNA" 1 "Active" 0 "Inactive" ;
VAL_ 2499762532 BATT_07_NegDcContWelded 3 "Error" 2 "SNA" 1 "Active" 0 "Inactive" ;
VAL_ 2499762532 BATT_07_PrechgTooFast 3 "Error" 2 "SNA" 1 "Active" 0 "Inactive" ;
VAL_ 2499762532 BATT_07_PrechgContWelded 3 "Error" 2 "SNA" 1 "Active" 0 "Inactive" ;
VAL_ 2499762532 BATT_07_PrechgTimeout 3 "Error" 2 "SNA" 1 "Active" 0 "Inactive" ;
VAL_ 2499762532 BATT_07_PrechgContStuckOpen 3 "Error" 2 "SNA" 1 "Active" 0 "Inactive" ;
VAL_ 2499762532 BATT_07_ModuleImbalance 3 "Error" 2 "SNA" 1 "Active" 0 "Inactive" ;
VAL_ 2499762532 BATT_07_ModuleMIA 3 "Error" 2 "SNA" 1 "Active" 0 "Inactive" ;
VAL_ 2499762532 BATT_07_SensePackVoltError 3 "Error" 2 "SNA" 1 "Active" 0 "Inactive" ;
VAL_ 2499762532 BATT_07_SenseLoadVoltError 3 "Error" 2 "SNA" 1 "Active" 0 "Inactive" ;
VAL_ 2499762532 BATT_07_SenseShuntError 3 "Error" 2 "SNA" 1 "Active" 0 "Inactive" ;
VAL_ 2499762532 BATT_07_SenseFcVoltErrorr 3 "Error" 2 "SNA" 1 "Active" 0 "Inactive" ;
VAL_ 2499762532 BATT_07_SenseBrickOpen 3 "Error" 2 "SNA" 1 "Active" 0 "Inactive" ;
VAL_ 2499762532 BATT_08_vBrickOverSev 3 "Error" 2 "SNA" 1 "Active" 0 "Inactive" ;
VAL_ 2499762532 BATT_08_vBrickOverMod 3 "Error" 2 "SNA" 1 "Active" 0 "Inactive" ;
VAL_ 2499762532 BATT_08_vBrickOverWar 3 "Error" 2 "SNA" 1 "Active" 0 "Inactive" ;
VAL_ 2499762532 BATT_08_HostQuiet 3 "Error" 2 "SNA" 1 "Active" 0 "Inactive" ;
VAL_ 2499762532 BATT_08_vBrickUnderMod 3 "Error" 2 "SNA" 1 "Active" 0 "Inactive" ;
VAL_ 2499762532 BATT_08_vBrickUnderWar 3 "Error" 2 "SNA" 1 "Active" 0 "Inactive" ;
VAL_ 2499762532 BATT_08_TempModuleOverSev 3 "Error" 2 "SNA" 1 "Active" 0 "Inactive" ;
VAL_ 2499762532 BATT_08_TempModuleOverMod 3 "Error" 2 "SNA" 1 "Active" 0 "Inactive" ;
VAL_ 2499762532 BATT_08_TempModuleOverWar 3 "Error" 2 "SNA" 1 "Active" 0 "Inactive" ;
VAL_ 2499762532 BATT_08_TempModuleUnderSev 3 "Error" 2 "SNA" 1 "Active" 0 "Inactive" ;
VAL_ 2499762532 BATT_08_TempModuleUnderMod 3 "Error" 2 "SNA" 1 "Active" 0 "Inactive" ;
VAL_ 2499762532 BATT_08_TempModuleUnderWar 3 "Error" 2 "SNA" 1 "Active" 0 "Inactive" ;
VAL_ 2499762532 BATT_08_iOvercharge 3 "Error" 2 "SNA" 1 "Active" 0 "Inactive" ;
VAL_ 2499762532 BATT_08_iOverdischarge 3 "Error" 2 "SNA" 1 "Active" 0 "Inactive" ;
VAL_ 2499762532 BATT_08_iOverHardware 3 "Error" 2 "SNA" 1 "Active" 0 "Inactive" ;
VAL_ 2499762532 BATT_08_PosDcContStuckOpen 3 "Error" 2 "SNA" 1 "Active" 0 "Inactive" ;
VAL_ 2499762532 BATT_08_PosDcContWelded 3 "Error" 2 "SNA" 1 "Active" 0 "Inactive" ;
VAL_ 2499762532 BATT_08_NegDcContStuckOpen 3 "Error" 2 "SNA" 1 "Active" 0 "Inactive" ;
VAL_ 2499762532 BATT_08_NegDcContWelded 3 "Error" 2 "SNA" 1 "Active" 0 "Inactive" ;
VAL_ 2499762532 BATT_08_PrechgTooFast 3 "Error" 2 "SNA" 1 "Active" 0 "Inactive" ;
VAL_ 2499762532 BATT_08_PrechgContWelded 3 "Error" 2 "SNA" 1 "Active" 0 "Inactive" ;
VAL_ 2499762532 BATT_08_PrechgTimeout 3 "Error" 2 "SNA" 1 "Active" 0 "Inactive" ;
VAL_ 2499762532 BATT_08_PrechgContStuckOpen 3 "Error" 2 "SNA" 1 "Active" 0 "Inactive" ;
VAL_ 2499762532 BATT_08_ModuleImbalance 3 "Error" 2 "SNA" 1 "Active" 0 "Inactive" ;
VAL_ 2499762532 BATT_08_ModuleMIA 3 "Error" 2 "SNA" 1 "Active" 0 "Inactive" ;
VAL_ 2499762532 BATT_08_SensePackVoltError 3 "Error" 2 "SNA" 1 "Active" 0 "Inactive" ;
VAL_ 2499762532 BATT_08_SenseLoadVoltError 3 "Error" 2 "SNA" 1 "Active" 0 "Inactive" ;
VAL_ 2499762532 BATT_08_SenseShuntError 3 "Error" 2 "SNA" 1 "Active" 0 "Inactive" ;
VAL_ 2499762532 BATT_08_SenseFcVoltErrorr 3 "Error" 2 "SNA" 1 "Active" 0 "Inactive" ;
VAL_ 2499762532 BATT_08_SenseBrickOpen 3 "Error" 2 "SNA" 1 "Active" 0 "Inactive" ;
VAL_ 2499762532 BATT_09_vBrickOverSev 3 "Error" 2 "SNA" 1 "Active" 0 "Inactive" ;
VAL_ 2499762532 BATT_09_vBrickOverMod 3 "Error" 2 "SNA" 1 "Active" 0 "Inactive" ;
VAL_ 2499762532 BATT_09_vBrickOverWar 3 "Error" 2 "SNA" 1 "Active" 0 "Inactive" ;
VAL_ 2499762532 BATT_09_HostQuiet 3 "Error" 2 "SNA" 1 "Active" 0 "Inactive" ;
VAL_ 2499762532 BATT_09_vBrickUnderMod 3 "Error" 2 "SNA" 1 "Active" 0 "Inactive" ;
VAL_ 2499762532 BATT_09_vBrickUnderWar 3 "Error" 2 "SNA" 1 "Active" 0 "Inactive" ;
VAL_ 2499762532 BATT_09_TempModuleOverSev 3 "Error" 2 "SNA" 1 "Active" 0 "Inactive" ;
VAL_ 2499762532 BATT_09_TempModuleOverMod 3 "Error" 2 "SNA" 1 "Active" 0 "Inactive" ;
VAL_ 2499762532 BATT_09_TempModuleOverWar 3 "Error" 2 "SNA" 1 "Active" 0 "Inactive" ;
VAL_ 2499762532 BATT_09_TempModuleUnderSev 3 "Error" 2 "SNA" 1 "Active" 0 "Inactive" ;
VAL_ 2499762532 BATT_09_TempModuleUnderMod 3 "Error" 2 "SNA" 1 "Active" 0 "Inactive" ;
VAL_ 2499762532 BATT_09_TempModuleUnderWar 3 "Error" 2 "SNA" 1 "Active" 0 "Inactive" ;
VAL_ 2499762532 BATT_09_iOvercharge 3 "Error" 2 "SNA" 1 "Active" 0 "Inactive" ;
VAL_ 2499762532 BATT_09_iOverdischarge 3 "Error" 2 "SNA" 1 "Active" 0 "Inactive" ;
VAL_ 2499762532 BATT_09_iOverHardware 3 "Error" 2 "SNA" 1 "Active" 0 "Inactive" ;
VAL_ 2499762532 BATT_09_PosDcContStuckOpen 3 "Error" 2 "SNA" 1 "Active" 0 "Inactive" ;
VAL_ 2499762532 BATT_09_PosDcContWelded 3 "Error" 2 "SNA" 1 "Active" 0 "Inactive" ;
VAL_ 2499762532 BATT_09_NegDcContStuckOpen 3 "Error" 2 "SNA" 1 "Active" 0 "Inactive" ;
VAL_ 2499762532 BATT_09_NegDcContWelded 3 "Error" 2 "SNA" 1 "Active" 0 "Inactive" ;
VAL_ 2499762532 BATT_09_PrechgTooFast 3 "Error" 2 "SNA" 1 "Active" 0 "Inactive" ;
VAL_ 2499762532 BATT_09_PrechgContWelded 3 "Error" 2 "SNA" 1 "Active" 0 "Inactive" ;
VAL_ 2499762532 BATT_09_PrechgTimeout 3 "Error" 2 "SNA" 1 "Active" 0 "Inactive" ;
VAL_ 2499762532 BATT_09_PrechgContStuckOpen 3 "Error" 2 "SNA" 1 "Active" 0 "Inactive" ;
VAL_ 2499762532 BATT_09_ModuleImbalance 3 "Error" 2 "SNA" 1 "Active" 0 "Inactive" ;
VAL_ 2499762532 BATT_09_ModuleMIA 3 "Error" 2 "SNA" 1 "Active" 0 "Inactive" ;
VAL_ 2499762532 BATT_09_SensePackVoltError 3 "Error" 2 "SNA" 1 "Active" 0 "Inactive" ;
VAL_ 2499762532 BATT_09_SenseLoadVoltError 3 "Error" 2 "SNA" 1 "Active" 0 "Inactive" ;
VAL_ 2499762532 BATT_09_SenseShuntError 3 "Error" 2 "SNA" 1 "Active" 0 "Inactive" ;
VAL_ 2499762532 BATT_09_SenseFcVoltErrorr 3 "Error" 2 "SNA" 1 "Active" 0 "Inactive" ;
VAL_ 2499762532 BATT_09_SenseBrickOpen 3 "Error" 2 "SNA" 1 "Active" 0 "Inactive" ;
VAL_ 2499762532 BATT_10_vBrickOverSev 3 "Error" 2 "SNA" 1 "Active" 0 "Inactive" ;
VAL_ 2499762532 BATT_10_vBrickOverMod 3 "Error" 2 "SNA" 1 "Active" 0 "Inactive" ;
VAL_ 2499762532 BATT_10_vBrickOverWar 3 "Error" 2 "SNA" 1 "Active" 0 "Inactive" ;
VAL_ 2499762532 BATT_10_HostQuiet 3 "Error" 2 "SNA" 1 "Active" 0 "Inactive" ;
VAL_ 2499762532 BATT_10_vBrickUnderMod 3 "Error" 2 "SNA" 1 "Active" 0 "Inactive" ;
VAL_ 2499762532 BATT_10_vBrickUnderWar 3 "Error" 2 "SNA" 1 "Active" 0 "Inactive" ;
VAL_ 2499762532 BATT_10_TempModuleOverSev 3 "Error" 2 "SNA" 1 "Active" 0 "Inactive" ;
VAL_ 2499762532 BATT_10_TempModuleOverMod 3 "Error" 2 "SNA" 1 "Active" 0 "Inactive" ;
VAL_ 2499762532 BATT_10_TempModuleOverWar 3 "Error" 2 "SNA" 1 "Active" 0 "Inactive" ;
VAL_ 2499762532 BATT_10_TempModuleUnderSev 3 "Error" 2 "SNA" 1 "Active" 0 "Inactive" ;
VAL_ 2499762532 BATT_10_TempModuleUnderMod 3 "Error" 2 "SNA" 1 "Active" 0 "Inactive" ;
VAL_ 2499762532 BATT_10_TempModuleUnderWar 3 "Error" 2 "SNA" 1 "Active" 0 "Inactive" ;
VAL_ 2499762532 BATT_10_iOvercharge 3 "Error" 2 "SNA" 1 "Active" 0 "Inactive" ;
VAL_ 2499762532 BATT_10_iOverdischarge 3 "Error" 2 "SNA" 1 "Active" 0 "Inactive" ;
VAL_ 2499762532 BATT_10_iOverHardware 3 "Error" 2 "SNA" 1 "Active" 0 "Inactive" ;
VAL_ 2499762532 BATT_10_PosDcContStuckOpen 3 "Error" 2 "SNA" 1 "Active" 0 "Inactive" ;
VAL_ 2499762532 BATT_10_PosDcContWelded 3 "Error" 2 "SNA" 1 "Active" 0 "Inactive" ;
VAL_ 2499762532 BATT_10_NegDcContStuckOpen 3 "Error" 2 "SNA" 1 "Active" 0 "Inactive" ;
VAL_ 2499762532 BATT_10_NegDcContWelded 3 "Error" 2 "SNA" 1 "Active" 0 "Inactive" ;
VAL_ 2499762532 BATT_10_PrechgTooFast 3 "Error" 2 "SNA" 1 "Active" 0 "Inactive" ;
VAL_ 2499762532 BATT_10_PrechgContWelded 3 "Error" 2 "SNA" 1 "Active" 0 "Inactive" ;
VAL_ 2499762532 BATT_10_PrechgTimeout 3 "Error" 2 "SNA" 1 "Active" 0 "Inactive" ;
VAL_ 2499762532 BATT_10_PrechgContStuckOpen 3 "Error" 2 "SNA" 1 "Active" 0 "Inactive" ;
VAL_ 2499762532 BATT_10_ModuleImbalance 3 "Error" 2 "SNA" 1 "Active" 0 "Inactive" ;
VAL_ 2499762532 BATT_10_ModuleMIA 3 "Error" 2 "SNA" 1 "Active" 0 "Inactive" ;
VAL_ 2499762532 BATT_10_SensePackVoltError 3 "Error" 2 "SNA" 1 "Active" 0 "Inactive" ;
VAL_ 2499762532 BATT_10_SenseLoadVoltError 3 "Error" 2 "SNA" 1 "Active" 0 "Inactive" ;
VAL_ 2499762532 BATT_10_SenseShuntError 3 "Error" 2 "SNA" 1 "Active" 0 "Inactive" ;
VAL_ 2499762532 BATT_10_SenseFcVoltErrorr 3 "Error" 2 "SNA" 1 "Active" 0 "Inactive" ;
VAL_ 2499762532 BATT_10_SenseBrickOpen 3 "Error" 2 "SNA" 1 "Active" 0 "Inactive" ;
VAL_ 2499762532 BATT_11_vBrickOverSev 3 "Error" 2 "SNA" 1 "Active" 0 "Inactive" ;
VAL_ 2499762532 BATT_11_vBrickOverMod 3 "Error" 2 "SNA" 1 "Active" 0 "Inactive" ;
VAL_ 2499762532 BATT_11_vBrickOverWar 3 "Error" 2 "SNA" 1 "Active" 0 "Inactive" ;
VAL_ 2499762532 BATT_11_HostQuiet 3 "Error" 2 "SNA" 1 "Active" 0 "Inactive" ;
VAL_ 2499762532 BATT_11_vBrickUnderMod 3 "Error" 2 "SNA" 1 "Active" 0 "Inactive" ;
VAL_ 2499762532 BATT_11_vBrickUnderWar 3 "Error" 2 "SNA" 1 "Active" 0 "Inactive" ;
VAL_ 2499762532 BATT_11_TempModuleOverSev 3 "Error" 2 "SNA" 1 "Active" 0 "Inactive" ;
VAL_ 2499762532 BATT_11_TempModuleOverMod 3 "Error" 2 "SNA" 1 "Active" 0 "Inactive" ;
VAL_ 2499762532 BATT_11_TempModuleOverWar 3 "Error" 2 "SNA" 1 "Active" 0 "Inactive" ;
VAL_ 2499762532 BATT_11_TempModuleUnderSev 3 "Error" 2 "SNA" 1 "Active" 0 "Inactive" ;
VAL_ 2499762532 BATT_11_TempModuleUnderMod 3 "Error" 2 "SNA" 1 "Active" 0 "Inactive" ;
VAL_ 2499762532 BATT_11_TempModuleUnderWar 3 "Error" 2 "SNA" 1 "Active" 0 "Inactive" ;
VAL_ 2499762532 BATT_11_iOvercharge 3 "Error" 2 "SNA" 1 "Active" 0 "Inactive" ;
VAL_ 2499762532 BATT_11_iOverdischarge 3 "Error" 2 "SNA" 1 "Active" 0 "Inactive" ;
VAL_ 2499762532 BATT_11_iOverHardware 3 "Error" 2 "SNA" 1 "Active" 0 "Inactive" ;
VAL_ 2499762532 BATT_11_PosDcContStuckOpen 3 "Error" 2 "SNA" 1 "Active" 0 "Inactive" ;
VAL_ 2499762532 BATT_11_PosDcContWelded 3 "Error" 2 "SNA" 1 "Active" 0 "Inactive" ;
VAL_ 2499762532 BATT_11_NegDcContStuckOpen 3 "Error" 2 "SNA" 1 "Active" 0 "Inactive" ;
VAL_ 2499762532 BATT_11_NegDcContWelded 3 "Error" 2 "SNA" 1 "Active" 0 "Inactive" ;
VAL_ 2499762532 BATT_11_PrechgTooFast 3 "Error" 2 "SNA" 1 "Active" 0 "Inactive" ;
VAL_ 2499762532 BATT_11_PrechgContWelded 3 "Error" 2 "SNA" 1 "Active" 0 "Inactive" ;
VAL_ 2499762532 BATT_11_PrechgTimeout 3 "Error" 2 "SNA" 1 "Active" 0 "Inactive" ;
VAL_ 2499762532 BATT_11_PrechgContStuckOpen 3 "Error" 2 "SNA" 1 "Active" 0 "Inactive" ;
VAL_ 2499762532 BATT_11_ModuleImbalance 3 "Error" 2 "SNA" 1 "Active" 0 "Inactive" ;
VAL_ 2499762532 BATT_11_ModuleMIA 3 "Error" 2 "SNA" 1 "Active" 0 "Inactive" ;
VAL_ 2499762532 BATT_11_SensePackVoltError 3 "Error" 2 "SNA" 1 "Active" 0 "Inactive" ;
VAL_ 2499762532 BATT_11_SenseLoadVoltError 3 "Error" 2 "SNA" 1 "Active" 0 "Inactive" ;
VAL_ 2499762532 BATT_11_SenseShuntError 3 "Error" 2 "SNA" 1 "Active" 0 "Inactive" ;
VAL_ 2499762532 BATT_11_SenseFcVoltErrorr 3 "Error" 2 "SNA" 1 "Active" 0 "Inactive" ;
VAL_ 2499762532 BATT_11_SenseBrickOpen 3 "Error" 2 "SNA" 1 "Active" 0 "Inactive" ;
VAL_ 2499762532 BATT_12_vBrickOverSev 3 "Error" 2 "SNA" 1 "Active" 0 "Inactive" ;
VAL_ 2499762532 BATT_12_vBrickOverMod 3 "Error" 2 "SNA" 1 "Active" 0 "Inactive" ;
VAL_ 2499762532 BATT_12_vBrickOverWar 3 "Error" 2 "SNA" 1 "Active" 0 "Inactive" ;
VAL_ 2499762532 BATT_12_HostQuiet 3 "Error" 2 "SNA" 1 "Active" 0 "Inactive" ;
VAL_ 2499762532 BATT_12_vBrickUnderMod 3 "Error" 2 "SNA" 1 "Active" 0 "Inactive" ;
VAL_ 2499762532 BATT_12_vBrickUnderWar 3 "Error" 2 "SNA" 1 "Active" 0 "Inactive" ;
VAL_ 2499762532 BATT_12_TempModuleOverSev 3 "Error" 2 "SNA" 1 "Active" 0 "Inactive" ;
VAL_ 2499762532 BATT_12_TempModuleOverMod 3 "Error" 2 "SNA" 1 "Active" 0 "Inactive" ;
VAL_ 2499762532 BATT_12_TempModuleOverWar 3 "Error" 2 "SNA" 1 "Active" 0 "Inactive" ;
VAL_ 2499762532 BATT_12_TempModuleUnderSev 3 "Error" 2 "SNA" 1 "Active" 0 "Inactive" ;
VAL_ 2499762532 BATT_12_TempModuleUnderMod 3 "Error" 2 "SNA" 1 "Active" 0 "Inactive" ;
VAL_ 2499762532 BATT_12_TempModuleUnderWar 3 "Error" 2 "SNA" 1 "Active" 0 "Inactive" ;
VAL_ 2499762532 BATT_12_iOvercharge 3 "Error" 2 "SNA" 1 "Active" 0 "Inactive" ;
VAL_ 2499762532 BATT_12_iOverdischarge 3 "Error" 2 "SNA" 1 "Active" 0 "Inactive" ;
VAL_ 2499762532 BATT_12_iOverHardware 3 "Error" 2 "SNA" 1 "Active" 0 "Inactive" ;
VAL_ 2499762532 BATT_12_PosDcContStuckOpen 3 "Error" 2 "SNA" 1 "Active" 0 "Inactive" ;
VAL_ 2499762532 BATT_12_PosDcContWelded 3 "Error" 2 "SNA" 1 "Active" 0 "Inactive" ;
VAL_ 2499762532 BATT_12_NegDcContStuckOpen 3 "Error" 2 "SNA" 1 "Active" 0 "Inactive" ;
VAL_ 2499762532 BATT_12_NegDcContWelded 3 "Error" 2 "SNA" 1 "Active" 0 "Inactive" ;
VAL_ 2499762532 BATT_12_PrechgTooFast 3 "Error" 2 "SNA" 1 "Active" 0 "Inactive" ;
VAL_ 2499762532 BATT_12_PrechgContWelded 3 "Error" 2 "SNA" 1 "Active" 0 "Inactive" ;
VAL_ 2499762532 BATT_12_PrechgTimeout 3 "Error" 2 "SNA" 1 "Active" 0 "Inactive" ;
VAL_ 2499762532 BATT_12_PrechgContStuckOpen 3 "Error" 2 "SNA" 1 "Active" 0 "Inactive" ;
VAL_ 2499762532 BATT_12_ModuleImbalance 3 "Error" 2 "SNA" 1 "Active" 0 "Inactive" ;
VAL_ 2499762532 BATT_12_ModuleMIA 3 "Error" 2 "SNA" 1 "Active" 0 "Inactive" ;
VAL_ 2499762532 BATT_12_SensePackVoltError 3 "Error" 2 "SNA" 1 "Active" 0 "Inactive" ;
VAL_ 2499762532 BATT_12_SenseLoadVoltError 3 "Error" 2 "SNA" 1 "Active" 0 "Inactive" ;
VAL_ 2499762532 BATT_12_SenseShuntError 3 "Error" 2 "SNA" 1 "Active" 0 "Inactive" ;
VAL_ 2499762532 BATT_12_SenseFcVoltErrorr 3 "Error" 2 "SNA" 1 "Active" 0 "Inactive" ;
VAL_ 2499762532 BATT_12_SenseBrickOpen 3 "Error" 2 "SNA" 1 "Active" 0 "Inactive" ;
VAL_ 2499762532 BATT_13_vBrickOverSev 3 "Error" 2 "SNA" 1 "Active" 0 "Inactive" ;
VAL_ 2499762532 BATT_13_vBrickOverMod 3 "Error" 2 "SNA" 1 "Active" 0 "Inactive" ;
VAL_ 2499762532 BATT_13_vBrickOverWar 3 "Error" 2 "SNA" 1 "Active" 0 "Inactive" ;
VAL_ 2499762532 BATT_13_HostQuiet 3 "Error" 2 "SNA" 1 "Active" 0 "Inactive" ;
VAL_ 2499762532 BATT_13_vBrickUnderMod 3 "Error" 2 "SNA" 1 "Active" 0 "Inactive" ;
VAL_ 2499762532 BATT_13_vBrickUnderWar 3 "Error" 2 "SNA" 1 "Active" 0 "Inactive" ;
VAL_ 2499762532 BATT_13_TempModuleOverSev 3 "Error" 2 "SNA" 1 "Active" 0 "Inactive" ;
VAL_ 2499762532 BATT_13_TempModuleOverMod 3 "Error" 2 "SNA" 1 "Active" 0 "Inactive" ;
VAL_ 2499762532 BATT_13_TempModuleOverWar 3 "Error" 2 "SNA" 1 "Active" 0 "Inactive" ;
VAL_ 2499762532 BATT_13_TempModuleUnderSev 3 "Error" 2 "SNA" 1 "Active" 0 "Inactive" ;
VAL_ 2499762532 BATT_13_TempModuleUnderMod 3 "Error" 2 "SNA" 1 "Active" 0 "Inactive" ;
VAL_ 2499762532 BATT_13_TempModuleUnderWar 3 "Error" 2 "SNA" 1 "Active" 0 "Inactive" ;
VAL_ 2499762532 BATT_13_iOvercharge 3 "Error" 2 "SNA" 1 "Active" 0 "Inactive" ;
VAL_ 2499762532 BATT_13_iOverdischarge 3 "Error" 2 "SNA" 1 "Active" 0 "Inactive" ;
VAL_ 2499762532 BATT_13_iOverHardware 3 "Error" 2 "SNA" 1 "Active" 0 "Inactive" ;
VAL_ 2499762532 BATT_13_PosDcContStuckOpen 3 "Error" 2 "SNA" 1 "Active" 0 "Inactive" ;
VAL_ 2499762532 BATT_13_PosDcContWelded 3 "Error" 2 "SNA" 1 "Active" 0 "Inactive" ;
VAL_ 2499762532 BATT_13_NegDcContStuckOpen 3 "Error" 2 "SNA" 1 "Active" 0 "Inactive" ;
VAL_ 2499762532 BATT_13_NegDcContWelded 3 "Error" 2 "SNA" 1 "Active" 0 "Inactive" ;
VAL_ 2499762532 BATT_13_PrechgTooFast 3 "Error" 2 "SNA" 1 "Active" 0 "Inactive" ;
VAL_ 2499762532 BATT_13_PrechgContWelded 3 "Error" 2 "SNA" 1 "Active" 0 "Inactive" ;
VAL_ 2499762532 BATT_13_PrechgTimeout 3 "Error" 2 "SNA" 1 "Active" 0 "Inactive" ;
VAL_ 2499762532 BATT_13_PrechgContStuckOpen 3 "Error" 2 "SNA" 1 "Active" 0 "Inactive" ;
VAL_ 2499762532 BATT_13_ModuleImbalance 3 "Error" 2 "SNA" 1 "Active" 0 "Inactive" ;
VAL_ 2499762532 BATT_13_ModuleMIA 3 "Error" 2 "SNA" 1 "Active" 0 "Inactive" ;
VAL_ 2499762532 BATT_13_SensePackVoltError 3 "Error" 2 "SNA" 1 "Active" 0 "Inactive" ;
VAL_ 2499762532 BATT_13_SenseLoadVoltError 3 "Error" 2 "SNA" 1 "Active" 0 "Inactive" ;
VAL_ 2499762532 BATT_13_SenseShuntError 3 "Error" 2 "SNA" 1 "Active" 0 "Inactive" ;
VAL_ 2499762532 BATT_13_SenseFcVoltErrorr 3 "Error" 2 "SNA" 1 "Active" 0 "Inactive" ;
VAL_ 2499762532 BATT_13_SenseBrickOpen 3 "Error" 2 "SNA" 1 "Active" 0 "Inactive" ;
VAL_ 2499762532 BATT_14_vBrickOverSev 3 "Error" 2 "SNA" 1 "Active" 0 "Inactive" ;
VAL_ 2499762532 BATT_14_vBrickOverMod 3 "Error" 2 "SNA" 1 "Active" 0 "Inactive" ;
VAL_ 2499762532 BATT_14_vBrickOverWar 3 "Error" 2 "SNA" 1 "Active" 0 "Inactive" ;
VAL_ 2499762532 BATT_14_HostQuiet 3 "Error" 2 "SNA" 1 "Active" 0 "Inactive" ;
VAL_ 2499762532 BATT_14_vBrickUnderMod 3 "Error" 2 "SNA" 1 "Active" 0 "Inactive" ;
VAL_ 2499762532 BATT_14_vBrickUnderWar 3 "Error" 2 "SNA" 1 "Active" 0 "Inactive" ;
VAL_ 2499762532 BATT_14_TempModuleOverSev 3 "Error" 2 "SNA" 1 "Active" 0 "Inactive" ;
VAL_ 2499762532 BATT_14_TempModuleOverMod 3 "Error" 2 "SNA" 1 "Active" 0 "Inactive" ;
VAL_ 2499762532 BATT_14_TempModuleOverWar 3 "Error" 2 "SNA" 1 "Active" 0 "Inactive" ;
VAL_ 2499762532 BATT_14_TempModuleUnderSev 3 "Error" 2 "SNA" 1 "Active" 0 "Inactive" ;
VAL_ 2499762532 BATT_14_TempModuleUnderMod 3 "Error" 2 "SNA" 1 "Active" 0 "Inactive" ;
VAL_ 2499762532 BATT_14_TempModuleUnderWar 3 "Error" 2 "SNA" 1 "Active" 0 "Inactive" ;
VAL_ 2499762532 BATT_14_iOvercharge 3 "Error" 2 "SNA" 1 "Active" 0 "Inactive" ;
VAL_ 2499762532 BATT_14_iOverdischarge 3 "Error" 2 "SNA" 1 "Active" 0 "Inactive" ;
VAL_ 2499762532 BATT_14_iOverHardware 3 "Error" 2 "SNA" 1 "Active" 0 "Inactive" ;
VAL_ 2499762532 BATT_14_PosDcContStuckOpen 3 "Error" 2 "SNA" 1 "Active" 0 "Inactive" ;
VAL_ 2499762532 BATT_14_PosDcContWelded 3 "Error" 2 "SNA" 1 "Active" 0 "Inactive" ;
VAL_ 2499762532 BATT_14_NegDcContStuckOpen 3 "Error" 2 "SNA" 1 "Active" 0 "Inactive" ;
VAL_ 2499762532 BATT_14_NegDcContWelded 3 "Error" 2 "SNA" 1 "Active" 0 "Inactive" ;
VAL_ 2499762532 BATT_14_PrechgTooFast 3 "Error" 2 "SNA" 1 "Active" 0 "Inactive" ;
VAL_ 2499762532 BATT_14_PrechgContWelded 3 "Error" 2 "SNA" 1 "Active" 0 "Inactive" ;
VAL_ 2499762532 BATT_14_PrechgTimeout 3 "Error" 2 "SNA" 1 "Active" 0 "Inactive" ;
VAL_ 2499762532 BATT_14_PrechgContStuckOpen 3 "Error" 2 "SNA" 1 "Active" 0 "Inactive" ;
VAL_ 2499762532 BATT_14_ModuleImbalance 3 "Error" 2 "SNA" 1 "Active" 0 "Inactive" ;
VAL_ 2499762532 BATT_14_ModuleMIA 3 "Error" 2 "SNA" 1 "Active" 0 "Inactive" ;
VAL_ 2499762532 BATT_14_SensePackVoltError 3 "Error" 2 "SNA" 1 "Active" 0 "Inactive" ;
VAL_ 2499762532 BATT_14_SenseLoadVoltError 3 "Error" 2 "SNA" 1 "Active" 0 "Inactive" ;
VAL_ 2499762532 BATT_14_SenseShuntError 3 "Error" 2 "SNA" 1 "Active" 0 "Inactive" ;
VAL_ 2499762532 BATT_14_SenseFcVoltErrorr 3 "Error" 2 "SNA" 1 "Active" 0 "Inactive" ;
VAL_ 2499762532 BATT_14_SenseBrickOpen 3 "Error" 2 "SNA" 1 "Active" 0 "Inactive" ;
VAL_ 2499762532 BATT_15_vBrickOverSev 3 "Error" 2 "SNA" 1 "Active" 0 "Inactive" ;
VAL_ 2499762532 BATT_15_vBrickOverMod 3 "Error" 2 "SNA" 1 "Active" 0 "Inactive" ;
VAL_ 2499762532 BATT_15_vBrickOverWar 3 "Error" 2 "SNA" 1 "Active" 0 "Inactive" ;
VAL_ 2499762532 BATT_15_HostQuiet 3 "Error" 2 "SNA" 1 "Active" 0 "Inactive" ;
VAL_ 2499762532 BATT_15_vBrickUnderMod 3 "Error" 2 "SNA" 1 "Active" 0 "Inactive" ;
VAL_ 2499762532 BATT_15_vBrickUnderWar 3 "Error" 2 "SNA" 1 "Active" 0 "Inactive" ;
VAL_ 2499762532 BATT_15_TempModuleOverSev 3 "Error" 2 "SNA" 1 "Active" 0 "Inactive" ;
VAL_ 2499762532 BATT_15_TempModuleOverMod 3 "Error" 2 "SNA" 1 "Active" 0 "Inactive" ;
VAL_ 2499762532 BATT_15_TempModuleOverWar 3 "Error" 2 "SNA" 1 "Active" 0 "Inactive" ;
VAL_ 2499762532 BATT_15_TempModuleUnderSev 3 "Error" 2 "SNA" 1 "Active" 0 "Inactive" ;
VAL_ 2499762532 BATT_15_TempModuleUnderMod 3 "Error" 2 "SNA" 1 "Active" 0 "Inactive" ;
VAL_ 2499762532 BATT_15_TempModuleUnderWar 3 "Error" 2 "SNA" 1 "Active" 0 "Inactive" ;
VAL_ 2499762532 BATT_15_iOvercharge 3 "Error" 2 "SNA" 1 "Active" 0 "Inactive" ;
VAL_ 2499762532 BATT_15_iOverdischarge 3 "Error" 2 "SNA" 1 "Active" 0 "Inactive" ;
VAL_ 2499762532 BATT_15_iOverHardware 3 "Error" 2 "SNA" 1 "Active" 0 "Inactive" ;
VAL_ 2499762532 BATT_15_PosDcContStuckOpen 3 "Error" 2 "SNA" 1 "Active" 0 "Inactive" ;
VAL_ 2499762532 BATT_15_PosDcContWelded 3 "Error" 2 "SNA" 1 "Active" 0 "Inactive" ;
VAL_ 2499762532 BATT_15_NegDcContStuckOpen 3 "Error" 2 "SNA" 1 "Active" 0 "Inactive" ;
VAL_ 2499762532 BATT_15_NegDcContWelded 3 "Error" 2 "SNA" 1 "Active" 0 "Inactive" ;
VAL_ 2499762532 BATT_15_PrechgTooFast 3 "Error" 2 "SNA" 1 "Active" 0 "Inactive" ;
VAL_ 2499762532 BATT_15_PrechgContWelded 3 "Error" 2 "SNA" 1 "Active" 0 "Inactive" ;
VAL_ 2499762532 BATT_15_PrechgTimeout 3 "Error" 2 "SNA" 1 "Active" 0 "Inactive" ;
VAL_ 2499762532 BATT_15_PrechgContStuckOpen 3 "Error" 2 "SNA" 1 "Active" 0 "Inactive" ;
VAL_ 2499762532 BATT_15_ModuleImbalance 3 "Error" 2 "SNA" 1 "Active" 0 "Inactive" ;
VAL_ 2499762532 BATT_15_ModuleMIA 3 "Error" 2 "SNA" 1 "Active" 0 "Inactive" ;
VAL_ 2499762532 BATT_15_SensePackVoltError 3 "Error" 2 "SNA" 1 "Active" 0 "Inactive" ;
VAL_ 2499762532 BATT_15_SenseLoadVoltError 3 "Error" 2 "SNA" 1 "Active" 0 "Inactive" ;
VAL_ 2499762532 BATT_15_SenseShuntError 3 "Error" 2 "SNA" 1 "Active" 0 "Inactive" ;
VAL_ 2499762532 BATT_15_SenseFcVoltErrorr 3 "Error" 2 "SNA" 1 "Active" 0 "Inactive" ;
VAL_ 2499762532 BATT_15_SenseBrickOpen 3 "Error" 2 "SNA" 1 "Active" 0 "Inactive" ;
VAL_ 2499758948 BATT_vBrickOverSev 3 "Error" 2 "SNA" 1 "Active" 0 "Inactive" ;
VAL_ 2499758948 BATT_vBrickOverMod 3 "Error" 2 "SNA" 1 "Active" 0 "Inactive" ;
VAL_ 2499758948 BATT_vBrickOverWar 3 "Error" 2 "SNA" 1 "Active" 0 "Inactive" ;
VAL_ 2499758948 BATT_HostQuiet 3 "Error" 2 "SNA" 1 "Active" 0 "Inactive" ;
VAL_ 2499758948 BATT_vBrickUnderMod 3 "Error" 2 "SNA" 1 "Active" 0 "Inactive" ;
VAL_ 2499758948 BATT_vBrickUnderWar 3 "Error" 2 "SNA" 1 "Active" 0 "Inactive" ;
VAL_ 2499758948 BATT_TempModuleOverSev 3 "Error" 2 "SNA" 1 "Active" 0 "Inactive" ;
VAL_ 2499758948 BATT_TempModuleOverMod 3 "Error" 2 "SNA" 1 "Active" 0 "Inactive" ;
VAL_ 2499758948 BATT_TempModuleOverWar 3 "Error" 2 "SNA" 1 "Active" 0 "Inactive" ;
VAL_ 2499758948 BATT_TempModuleUnderSev 3 "Error" 2 "SNA" 1 "Active" 0 "Inactive" ;
VAL_ 2499758948 BATT_TempModuleUnderMod 3 "Error" 2 "SNA" 1 "Active" 0 "Inactive" ;
VAL_ 2499758948 BATT_TempModuleUnderWar 3 "Error" 2 "SNA" 1 "Active" 0 "Inactive" ;
VAL_ 2499758948 BATT_iOvercharge 3 "Error" 2 "SNA" 1 "Active" 0 "Inactive" ;
VAL_ 2499758948 BATT_iOverdischarge 3 "Error" 2 "SNA" 1 "Active" 0 "Inactive" ;
VAL_ 2499758948 BATT_iOverHardware 3 "Error" 2 "SNA" 1 "Active" 0 "Inactive" ;
VAL_ 2499758948 BATT_PosDcContStuckOpen 3 "Error" 2 "SNA" 1 "Active" 0 "Inactive" ;
VAL_ 2499758948 BATT_PosDcContWelded 3 "Error" 2 "SNA" 1 "Active" 0 "Inactive" ;
VAL_ 2499758948 BATT_NegDcContStuckOpen 3 "Error" 2 "SNA" 1 "Active" 0 "Inactive" ;
VAL_ 2499758948 BATT_NegDcContWelded 3 "Error" 2 "SNA" 1 "Active" 0 "Inactive" ;
VAL_ 2499758948 BATT_PrechgTooFast 3 "Error" 2 "SNA" 1 "Active" 0 "Inactive" ;
VAL_ 2499758948 BATT_PrechgContWelded 3 "Error" 2 "SNA" 1 "Active" 0 "Inactive" ;
VAL_ 2499758948 BATT_PrechgTimeout 3 "Error" 2 "SNA" 1 "Active" 0 "Inactive" ;
VAL_ 2499758948 BATT_PrechgContStuckOpen 3 "Error" 2 "SNA" 1 "Active" 0 "Inactive" ;
VAL_ 2499758948 BATT_ModuleImbalance 3 "Error" 2 "SNA" 1 "Active" 0 "Inactive" ;
VAL_ 2499758948 BATT_ModuleMIA 3 "Error" 2 "SNA" 1 "Active" 0 "Inactive" ;
VAL_ 2499758948 BATT_SensePackVoltError 3 "Error" 2 "SNA" 1 "Active" 0 "Inactive" ;
VAL_ 2499758948 BATT_SenseLoadVoltError 3 "Error" 2 "SNA" 1 "Active" 0 "Inactive" ;
VAL_ 2499758948 BATT_SenseShuntError 3 "Error" 2 "SNA" 1 "Active" 0 "Inactive" ;
VAL_ 2499758948 BATT_SenseFcVoltErrorr 3 "Error" 2 "SNA" 1 "Active" 0 "Inactive" ;
VAL_ 2499758948 BATT_SenseBrickOpen 3 "Error" 2 "SNA" 1 "Active" 0 "Inactive" ;
VAL_ 2499759204 BATT_SenseBrickImpHigh 3 "Error" 2 "SNA" 1 "Active" 0 "Inactive" ;
VAL_ 2499759204 BATT_AFEfault 3 "Error" 2 "SNA" 1 "Active" 0 "Inactive" ;
VAL_ 2499759204 BATT_AFEerror 3 "Error" 2 "SNA" 1 "Active" 0 "Inactive" ;
VAL_ 2499759204 BATT_HostMIA 3 "Error" 2 "SNA" 1 "Active" 0 "Inactive" ;
VAL_ 2499759204 BATT_TempAmbientOverSev 3 "Error" 2 "SNA" 1 "Active" 0 "Inactive" ;
VAL_ 2499759204 BATT_TempAmbientOverMod 3 "Error" 2 "SNA" 1 "Active" 0 "Inactive" ;
VAL_ 2499759204 BATT_TempAmbientOverWar 3 "Error" 2 "SNA" 1 "Active" 0 "Inactive" ;
VAL_ 2499759204 BATT_AbnormReset 3 "Error" 2 "SNA" 1 "Active" 0 "Inactive" ;
VAL_ 2499759204 BATT_SenseAuxVoltError 3 "Error" 2 "SNA" 1 "Active" 0 "Inactive" ;
VAL_ 2499759204 BATT_CalibrationInvalid 3 "Error" 2 "SNA" 1 "Active" 0 "Inactive" ;
VAL_ 2499759204 BATT_TaskLockup 3 "Error" 2 "SNA" 1 "Active" 0 "Inactive" ;
VAL_ 2499759204 BATT_RAMover 3 "Error" 2 "SNA" 1 "Active" 0 "Inactive" ;
VAL_ 2499759204 BATT_BrickOverdischarge 3 "Error" 2 "SNA" 1 "Active" 0 "Inactive" ;
VAL_ 2499759204 BATT_BrickOvercharge 3 "Error" 2 "SNA" 1 "Active" 0 "Inactive" ;
VAL_ 2499759204 BATT_vBrickImbalance 3 "Error" 2 "SNA" 1 "Active" 0 "Inactive" ;
VAL_ 2499759204 BATT_TempBrickImbalance 3 "Error" 2 "SNA" 1 "Active" 0 "Inactive" ;
VAL_ 2499759204 BATT_CapPackLow 3 "Error" 2 "SNA" 1 "Active" 0 "Inactive" ;
VAL_ 2499759204 BATT_rBrickHigh 3 "Error" 2 "SNA" 1 "Active" 0 "Inactive" ;
VAL_ 2499759204 BATT_PowerpackInsuffErr 3 "Error" 2 "SNA" 1 "Active" 0 "Inactive" ;
VAL_ 2499759204 BATT_BrickSoftShort 3 "Error" 2 "SNA" 1 "Active" 0 "Inactive" ;
VAL_ 2499759204 BATT_chargeUndercurrent 3 "Error" 2 "SNA" 1 "Active" 0 "Inactive" ;
VAL_ 2499759204 BATT_HVILcurrentSourceError 3 "Error" 2 "SNA" 1 "Active" 0 "Inactive" ;
VAL_ 2499759204 BATT_SRS 3 "Error" 2 "SNA" 1 "Active" 0 "Inactive" ;
VAL_ 2499759204 BATT_IsolationExtWar 3 "Error" 2 "SNA" 1 "Active" 0 "Inactive" ;
VAL_ 2499759204 BATT_IsolationIntWar 3 "Error" 2 "SNA" 1 "Active" 0 "Inactive" ;
VAL_ 2499759204 BATT_PyroFuseBlown 3 "Error" 2 "SNA" 1 "Active" 0 "Inactive" ;
VAL_ 2499759204 BATT_vBrickUnderSev 3 "Error" 2 "SNA" 1 "Active" 0 "Inactive" ;
VAL_ 2499759204 BATT_chargePrechargeTimeout 3 "Error" 2 "SNA" 1 "Active" 0 "Inactive" ;
VAL_ 2499759204 BATT_ModuleThermistorShort 3 "Error" 2 "SNA" 1 "Active" 0 "Inactive" ;
VAL_ 2499759204 BATT_ModuleThermistorBroken 3 "Error" 2 "SNA" 1 "Active" 0 "Inactive" ;
VAL_ 2499759460 BATT_HVILvoltageError 3 "Error" 2 "SNA" 1 "Active" 0 "Inactive" ;
VAL_ 2499759460 BATT_HVILcurrentReturnError 3 "Error" 2 "SNA" 1 "Active" 0 "Inactive" ;
VAL_ 2499759460 BATT_PosFcContWelded 3 "Error" 2 "SNA" 1 "Active" 0 "Inactive" ;
VAL_ 2499759460 BATT_PosFcContStuckOpen 3 "Error" 2 "SNA" 1 "Active" 0 "Inactive" ;
VAL_ 2499759460 BATT_NegFcContWelded 3 "Error" 2 "SNA" 1 "Active" 0 "Inactive" ;
VAL_ 2499759460 BATT_NegFcContStuckOpen 3 "Error" 2 "SNA" 1 "Active" 0 "Inactive" ;
VAL_ 2499759460 BATT_IsospiBreak 3 "Error" 2 "SNA" 1 "Active" 0 "Inactive" ;
VAL_ 2499759460 BATT_IsolationIntFault 3 "Error" 2 "SNA" 1 "Active" 0 "Inactive" ;
VAL_ 2499759460 BATT_IsolationExtFault 3 "Error" 2 "SNA" 1 "Active" 0 "Inactive" ;
VAL_ 2499759460 BATT_event_12v_filter_error 3 "Error" 2 "SNA" 1 "Active" 0 "Inactive" ;
VAL_ 2499759460 BATT_event_hall_eff_hi_rang_err 3 "Error" 2 "SNA" 1 "Active" 0 "Inactive" ;
VAL_ 2499759460 BATT_event_brick_volt_sns_open 3 "Error" 2 "SNA" 1 "Active" 0 "Inactive" ;
VAL_ 2499759460 BATT_event_5v_error 3 "Error" 2 "SNA" 1 "Active" 0 "Inactive" ;
VAL_ 2499759460 BATT_event_3_3_hot_error 3 "Error" 2 "SNA" 1 "Active" 0 "Inactive" ;
VAL_ 2499759460 BATT_event_12v_input_error 3 "Error" 2 "SNA" 1 "Active" 0 "Inactive" ;
VAL_ 2499759460 BATT_event_1_25v_error 3 "Error" 2 "SNA" 1 "Active" 0 "Inactive" ;
VAL_ 2499759460 BATT_event_shunt_MIA 3 "Error" 2 "SNA" 1 "Active" 0 "Inactive" ;
VAL_ 2499759460 BATT_event_SBC_int_reg_error 3 "Error" 2 "SNA" 1 "Active" 0 "Inactive" ;
VAL_ 2499759460 BATT_event_pos_3_3v_analog_error 3 "Error" 2 "SNA" 1 "Active" 0 "Inactive" ;
VAL_ 2499759460 BATT_event_outlt_clnt_thrm_open 3 "Error" 2 "SNA" 1 "Active" 0 "Inactive" ;
VAL_ 2499759460 BATT_event_neg_3_3_analog_error 3 "Error" 2 "SNA" 1 "Active" 0 "Inactive" ;
VAL_ 2499759460 BATT_event_inlet_clnt_thrm_open 3 "Error" 2 "SNA" 1 "Active" 0 "Inactive" ;
VAL_ 2499759460 BATT_event_hall_eff_lo_rang_err 3 "Error" 2 "SNA" 1 "Active" 0 "Inactive" ;
VAL_ 2499759460 BATT_event_outlt_clnt_thrm_short 3 "Error" 2 "SNA" 1 "Active" 0 "Inactive" ;
VAL_ 2499759460 BATT_event_inlet_clnt_thrm_short 3 "Error" 2 "SNA" 1 "Active" 0 "Inactive" ;
VAL_ 2499759460 BATT_event_3_3v_error 3 "Error" 2 "SNA" 1 "Active" 0 "Inactive" ;
VAL_ 2499761508 BATT_Sys_SOHR_Module_Min_V 3 "Error" 2 "SNA" 1 "Invalid" 0 "Valid" ;
VAL_ 2499761508 BATT_Sys_SOHR_Module_Max_V 3 "Error" 2 "SNA" 1 "Invalid" 0 "Valid" ;
VAL_ 2499761508 BATT_Sys_SOHR_Module_Avg_V 3 "Error" 2 "SNA" 1 "Invalid" 0 "Valid" ;
VAL_ 2499760996 BATT_Sys_SOHC_Module_Min_V 3 "Error" 2 "SNA" 1 "Invalid" 0 "Valid" ;
VAL_ 2499760996 BATT_Sys_SOHC_Module_Max_V 3 "Error" 2 "SNA" 1 "Invalid" 0 "Valid" ;
VAL_ 2499760996 BATT_Sys_SOHC_Module_Avg_V 3 "Error" 2 "SNA" 1 "Invalid" 0 "Valid" ;
VAL_ 2499760740 BATT_Cnc_Volt_String_Avg_V 3 "Error" 2 "SNA" 1 "Invalid" 0 "Valid" ;
VAL_ 2499760740 BATT_Cnc_Volt_String_Min_V 3 "Error" 2 "SNA" 1 "Invalid" 0 "Valid" ;
VAL_ 2499760740 BATT_Cnc_Volt_String_Max_V 3 "Error" 2 "SNA" 1 "Invalid" 0 "Valid" ;
VAL_ 2499756388 BATT_Cnc_Temp_Module_Avg_V 3 "Error" 2 "SNA" 1 "Invalid" 0 "Valid" ;
VAL_ 2499756388 BATT_Cnc_Temp_Module_Max_V 3 "Error" 2 "SNA" 1 "Invalid" 0 "Valid" ;
VAL_ 2499756388 BATT_Cnc_Temp_Module_Min_V 3 "Error" 2 "SNA" 1 "Invalid" 0 "Valid" ;
VAL_ 2499757668 BATT_Cnc_SOC_String_MinV 3 "Error" 2 "SNA" 1 "Invalid" 0 "Valid" ;
VAL_ 2499757668 BATT_Cnc_SOC_String_MaxV 3 "Error" 2 "SNA" 1 "Invalid" 0 "Valid" ;
VAL_ 2499757668 BATT_Cnc_SOC_String_AvgV 3 "Error" 2 "SNA" 1 "Invalid" 0 "Valid" ;
VAL_ 2499757668 BATT_Cnc_Energy_SystemV 3 "Error" 2 "SNA" 1 "Invalid" 0 "Valid" ;
VAL_ 2499762276 BATT_HVIL_State 3 "Error" 2 "SNA" 1 "Invalid" 0 "Valid" ;
VAL_ 2499762276 BATT_HVIL_SinkVolt_V 3 "Error" 2 "SNA" 1 "Invalid" 0 "Valid" ;
VAL_ 2499762276 BATT_HVIL_SourceVolt_V 3 "Error" 2 "SNA" 1 "Invalid" 0 "Valid" ;
VAL_ 2499761764 BATT_Cnc_Volt_Cell_Avg_V 3 "Error" 2 "SNA" 1 "Invalid" 0 "Valid" ;
VAL_ 2499761764 BATT_Cnc_Volt_Cell_Max_V 3 "Error" 2 "SNA" 1 "Invalid" 0 "Valid" ;
VAL_ 2499761764 BATT_Cnc_Volt_Cell_Min_V 3 "Error" 2 "SNA" 1 "Invalid" 0 "Valid" ;
VAL_ 2499760228 BATT_Limit_ChrgrVolt_V 3 "Error" 2 "SNA" 1 "Invalid" 0 "Valid" ;
VAL_ 2499760228 BATT_Limit_ChrgrCrrnt_V 3 "Error" 2 "SNA" 1 "Invalid" 0 "Valid" ;
VAL_ 2499760228 BATT_State_Chrgr 3 "Error" 2 "SNA" 1 "Is Charging" 0 "Not Charging" ;
VAL_ 2499760228 BATT_State_ChrgrIntrlck 3 "Error" 2 "SNA" 1 "Interlock Active" 0 "Interlock Inactive" ;
VAL_ 2499756105 APP_State_ReqMode 3 "Discharge" 2 "Charge" 1 "Idle" 0 "Off" ;
VAL_ 2499756105 APP_Contactor_Command 3 "Error" 2 "SNA" 1 "Close" 0 "Open" ;
VAL_ 2499756105 APP_Balancing_Enable_F 0 "Balancing not allowed" 1 "Balancing allowed" 2 "SNA" 3 "Error" ;
VAL_ 2499756105 APP_IsoRes_Enable_F 3 "Error" 2 "SNA" 1 "Measurement enabled" 0 "Measurement disabled" ;
VAL_ 2499756132 BATT_SysState 13 "Cooldown" 12 "Disconnect" 11 "Charge" 10 "Drive" 9 "ExternalIsolationTestCharge" 8 "ExternalIsolationTestDrive" 7 "ConnectChargeStagger" 6 "ConnectChargeBusJoin" 5 "ConnectChargePrecharge" 4 "ConnectDriveStagger" 3 "ConnectDriveBusJoin" 2 "ConnectDrivePrecharge" 1 "StandByReady" 0 "StandByNotReady" ;
VAL_ 2499756132 BATT_Contactor_EmergencyOpen_F 3 "SNA" 2 "Status Not Available" 1 "Emergency Open Active" 0 "Emergency Open Not Active" ;
VAL_ 2499756132 BATT_HVIL_Status 3 "Error" 2 "SNA" 1 "Invalid" 0 "Valid" ;
VAL_ 2499756132 BATT_Balancing_Status 0 "Balancing not active" 1 "Balancing active" 2 "SNA" 3 "Error" ;
VAL_ 2499756132 BATT_State_SysPwrMd 5 "Sleep" 4 "Fault" 3 "Run" 2 "Partial Run" 1 "Idle" 0 "Initialize" ;
VAL_ 2499756132 BATT_IsoRes_Source 3 "Error (Invalid)" 2 "SNA (Invalid)" 1 "Source_ThisCycle" 0 "Source_NVM" ;
VAL_ 2499756644 BATT_Current_String_Min_V 3 "Error" 2 "SNA" 1 "Invalid" 0 "Valid" ;
VAL_ 2499756644 BATT_Current_String_Max_V 3 "Error" 2 "SNA" 1 "Invalid" 0 "Valid" ;
VAL_ 2499756644 BATT_Current_System_V 3 "Error" 2 "SNA" 1 "Invalid" 0 "Valid" ;
VAL_ 2499756900 BATT_Sys_Volt_String_Avg_V 3 "Error" 2 "SNA" 1 "Invalid" 0 "Valid" ;
VAL_ 2499756900 BATT_Sys_Volt_String_Min_V 3 "Error" 2 "SNA" 1 "Invalid" 0 "Valid" ;
VAL_ 2499756900 BATT_Sys_Volt_String_Max_V 3 "Error" 2 "SNA" 1 "Invalid" 0 "Valid" ;
VAL_ 2499757156 BATT_Sys_Volt_Cell_Avg_V 3 "Error" 2 "SNA" 1 "Invalid" 0 "Valid" ;
VAL_ 2499757156 BATT_Sys_Volt_Cell_Max_V 3 "Error" 2 "SNA" 1 "Invalid" 0 "Valid" ;
VAL_ 2499757156 BATT_Sys_Volt_Cell_Min_V 3 "Error" 2 "SNA" 1 "Invalid" 0 "Valid" ;
VAL_ 2499757412 BATT_Sys_SOC_String_Min_V 3 "Error" 2 "SNA" 1 "Invalid" 0 "Valid" ;
VAL_ 2499757412 BATT_Sys_SOC_String_Max_V 3 "Error" 2 "SNA" 1 "Invalid" 0 "Valid" ;
VAL_ 2499757412 BATT_Sys_SOC_String_Avg_V 3 "Error" 2 "SNA" 1 "Invalid" 0 "Valid" ;
VAL_ 2499757412 BATT_Sys_Energy_System_V 3 "Error" 2 "SNA" 1 "Invalid" 0 "Valid" ;
VAL_ 2499757924 BATT_Sys_Temp_Module_Avg_V 3 "Error" 2 "SNA" 1 "Invalid" 0 "Valid" ;
VAL_ 2499757924 BATT_Sys_Temp_Module_Max_V 3 "Error" 2 "SNA" 1 "Invalid" 0 "Valid" ;
VAL_ 2499757924 BATT_Sys_Temp_Module_Min_V 3 "Error" 2 "SNA" 1 "Invalid" 0 "Valid" ;
VAL_ 2499758180 BATT_Limit_DschrgCrrnt_V 3 "Error" 2 "SNA" 1 "Invalid" 0 "Valid" ;
VAL_ 2499758180 BATT_Limit_DschrgPwr_V 3 "Error" 2 "SNA" 1 "Invalid" 0 "Valid" ;
VAL_ 2499758436 BATT_Limit_RegenCrrnt_V 3 "Error" 2 "SNA" 1 "Invalid" 0 "Valid" ;
VAL_ 2499758436 BATT_Limit_RegenPwr_V 3 "Error" 2 "SNA" 1 "Invalid" 0 "Valid" ;
